VERSION "29102026"

NS_ :

BS_:

BU_: AMK_INV_RL AMK_INV_RR AMK_INV_FR AMK_INV_FL PC

VAL_TABLE_ VT_AMK_DiagnosticNumber 0 "0 No diagnostic" 257 "257 System diagnostics: SBM withdrawal" 258 "258 Leave RF active" 259 "259 System diagnostics: SBM withdrawal" 514 "514 System diagnostics: Check parallel EEPROM on the control board" 515 "515 System diagnostics: Check parallel EEPROM on the control board" 516 "516 System diagnostics: Check AZ(X27)-AW(X57)-BUS" 517 "517 System diagnostics: Check AZ(X27)-AW(X57)-BUS" 518 "518 System diagnostics" 519 "519 System diagnostics: SEEP in the inverter cannot be addressed" 520 "520 System diagnostics: SEEP in the inverter cannot be addressed" 521 "521 System diagnostics" 770 "770 System diagnostics" 771 "771 System diagnostics: Check parallel EEPROM on the control board" 772 "772 System diagnostics: Check parallel EEPROM on the control board" 773 "773 System diagnostics: Inadmissible database order" 774 "774 System diagnostics" 775 "775 System diagnostics: ID not supported" 776 "776 System diagnostics: It was attempted to use a parameter set which was not reserved for..." 777 "777 System diagnostics: Check parallel EEPROM on the control board" 778 "778 System diagnostics: The attribute of the selected data block is wrong" 779 "779 System diagnostics: The maximum value of the last changed parameter was exceeded" 780 "780 System diagnostics: The minimum value of the last changed parameter was not reached" 781 "781 System diagnostics: It was attempted to write a list which can only be read" 783 "783 System diagnostics: Error at distributing parameters during internal system update" 1024 "1024 System diagnostics: System fault in the control board area" 1025 "1025 System diagnostics" 1026 "1026 System diagnostics: Error on writing the serial EEPROM" 1027 "1027 System diagnostics: Data error in the EPROM" 1028 "1028 System diagnostics: RAM memory error, is checked during system initialization" 1029 "1029 System diagnostics: Data error in the parallel EEPROM" 1030 "1030 System diagnostics: Error on writing the parallel EEPROM" 1031 "1031 System diagnostics: Control panel does not report on initialization" 1032 "1032 System diagnostics: Reception error from the serial interface 1" 1033 "1033 System diagnostics: Reception error from the serial interface 2" 1034 "1034 System diagnostics: Time level overflow" 1035 "1035 System diagnostics: Faulty system initialization, possible external fault" 1036 "1036 System diagnostics: Fault" 1037 "1037 System diagnostics: Fault" 1038 "1038 System diagnostics: Fault" 1039 "1039 System diagnostics: Faulty memory access of the processor. Software reset is triggered...." 1040 "1040 Tripzone" 1041 "1041 Overtemperature external component mains" 1042 "1042 Mains phase fault" 1043 "1043 Line Voltage Error" 1044 "1044 No SBM" 1045 "1045 Mains overvoltage" 1046 "1046 Mains undervoltage" 1047 "1047 Inhibit time for UE" 1048 "1048 UE switching frequency too high" 1049 "1049 DC bus" 1050 "1050 Phase error L1" 1051 "1051 Phase error L2" 1052 "1052 Phase error L3" 1053 "1053 Phase sequence L1/L2" 1054 "1054 Phase sequence L1/L3" 1055 "1055 Phase sequence L2/L3" 1056 "1056 Mains phase sequence L1, L2 , L3" 1057 "1057 Fault +12 V" 1058 "1058 Fault -12 V" 1059 "1059 DC bus overvoltage" 1060 "1060 Regeneration fault" 1061 "1061 Braking transistor fault" 1062 "1062 System diagnostics" 1063 "1063 System diagnostics" 1064 "1064 System diagnostics" 1065 "1065 System diagnostics: QUE missing on RF activation" 1066 "1066 System diagnostics" 1067 "1067 System diagnostics: Fault DC bus" 1068 "1068 System diagnostics" 1069 "1069 System diagnostics" 1070 "1070 System diagnostics: FL not possible (timeout 20 s)" 1071 "1071 System diagnostics: Brake acknowledgment does not correspond to the expected value" 1072 "1072 System diagnostics" 1073 "1073 Cooling Air Temperature Warning" 1074 "1074 External line component temperature warning" 1075 "1075 Power supply unit temperature warning" 1076 "1076 Feed / Regeneration temperature warning" 1077 "1077 Line Voltage warning" 1078 "1078 Line undervoltage warning" 1079 "1079 System diagnostics: All square wave encoder breakage messages are displayed only with a..." 1080 "1080 Encoder line break analysis on option card, input 1 slot 1" 1081 "1081 Encoder line break analysis on option card, input 2 slot 1" 1082 "1082 Encoder line break analysis on option card, input 3 slot 1" 1083 "1083 Encoder line break analysis on option card, input 4 slot 1" 1084 "1084 Encoder line break analysis on option card, input 1 slot 2" 1085 "1085 Encoder line break analysis on option card, input 2 slot 2" 1086 "1086 Encoder line break analysis on option card, input 3 slot 2" 1087 "1087 Encoder line break analysis on option card, input 4 slot 2" 1088 "1088 Encoder line break analysis on option card, input 1 slot 3" 1089 "1089 Encoder line break analysis on option card, input 2 slot 3" 1090 "1090 Encoder line break analysis on option card, input 3 slot 3" 1091 "1091 Encoder line break analysis on option card, input 4 slot 3" 1092 "1092 Encoder line break analysis on option card, input 1 slot 4" 1093 "1093 Encoder line break analysis on option card, input 2 slot 4" 1094 "1094 Encoder line break analysis on option card, input 3 slot 4" 1095 "1095 Encoder line break analysis on option card, input 4 slot 4" 1096 "1096 Short-circuit/overload of the outputs option card, slot 1 (e.g. AZ-EA8 or AZ-EA24)" 1097 "1097 Short-circuit / overload of the outputs option card, slot 2 (e.g. AZ-EA8 or AZ-EA24)" 1098 "1098 Short-circuit/overload of the outputs option card, slot 3 (e.g. AZ-EA8 or AZ-EA24)" 1099 "1099 Short-circuit/overload of the outputs option card, slot 4 (e.g. AZ-EA8 or AZ-EA24)" 1100 "1100 System diagnostics: Short-circuit / overload digital outputs" 1101 "1101 Logic voltage error" 1102 "1102 Line voltage limit" 1103 "1103 Field bus warning" 1104 "1104 No FL with RF active" 1105 "1105 Reserved" 1106 "1106 System diagnostic" 1107 "1107 System diagnostics: Short circuit DC bus voltage" 1108 "1108 System diagnostics: Main contactor" 1109 "1109 System diagnostics: Shifting of Y-point" 1110 "1110 Warning brake transistor" 1111 "1111 Warning external component" 1112 "1112 Overload error external component" 1115 "1115 Communication monitoring" 1281 "1281 System diagnostics" 1282 "1282 ID32777, ID111, ID32769" 1283 "1283 ID111, ID32769" 1284 "1284 ID111, ID32769" 1285 "1285 ID32772 wrong" 1286 "1286 ID82 or ID83 too large" 1287 "1287 ID32890: 1, 2, 5, 10" 1288 "1288 ID110, ID111, ID32769" 1289 "1289 ID83 too small" 1290 "1290 ID82 too large" 1291 "1291 ID32774 faulty" 1292 "1292 SEEP checksum" 1293 "1293 Boot strap EEPROM" 1294 "1294 EEPROM defective" 1295 "1295 ID100 / ID101" 1296 "1296 ID211 / ID209 / ID210" 1297 "1297 ID212 / ID209 / ID210" 1298 "1298 ID100 faulty" 1299 "1299 ID32775: even" 1300 "1300 Error in Temporary Parameters" 1301 "1301 ID32778 faulty" 1302 "1302 System diagnostics: Operating mode incomplete, see 'ID32800 AMK main operating mode' et..." 1303 "1303 System diagnostics: Operating mode incomplete, see 'ID32800 AMK main operating mode' et..." 1304 "1304 System diagnostics: Operating mode incomplete, see 'ID32800 AMK main operating mode' et..." 1305 "1305 System diagnostics: Operating mode incomplete, see 'ID32800 AMK main operating mode' et..." 1306 "1306 System diagnostics: Operating mode incomplete, see 'ID32800 AMK main operating mode' et..." 1307 "1307 System diagnostics: Position resolution not realizable" 1308 "1308 System diagnostics: Resolution of the “Speed source pulses” source not realizable" 1309 "1309 System diagnostics: Speed window larger than 107372.5 rpm" 1310 "1310 System diagnostics: “Pole factor POLF” calculation out of tolerance" 1311 "1311 System diagnostics: 4 GPZ calculation inconclusive" 1312 "1312 System diagnostics: Negated direction of rotation permissible only for A and I encoders" 1313 "1313 ID82 less then ID83" 1314 "1314 System diagnostics" 1315 "1315 System diagnostics: Resolver 0 point shift inadmissible" 1316 "1316 ID32769/ID100 too large" 1317 "1317 ID32770/ID110 too large" 1318 "1318 ID32774 faulty" 1319 "1319 System diagnostics: Configuration of “Strobe” binary input wrong" 1320 "1320 System diagnostics" 1321 "1321 System diagnostics" 1322 "1322 System diagnostics" 1323 "1323 ID32769 IM < ID111 IN" 1324 "1324 ID32772 nN too large" 1325 "1325 ID32772 P1 reference" 1326 "1326 System diagnostics: Source converter/on (UE) incorrect" 1327 "1327 ID104 kv factor" 1328 "1328 System diagnostics" 1329 "1329 ID111/ID110 > 80%" 1330 "1330 ID32772 > ID113" 1331 "1331 ID209 > ID113" 1332 "1332 ID210 > ID113" 1333 "1333 System diagnostics: 'ID32780 Acceleration ramp' resp. 'ID32781 Deceleration ramp' are t..." 1334 "1334 ID38 > ID113" 1335 "1335 |ID39| > ID113" 1336 "1336 ID32778 > ID113" 1337 "1337 ID32783 > ID113" 1338 "1338 ID157 > ID113" 1339 "1339 ID125 > ID113" 1340 "1340 ID124 > ID113" 1341 "1341 AW-Imax wrong (SEEP)" 1342 "1342 System diagnostics: External error" 1343 "1343 System diagnostics: Internal fault or component failure" 1344 "1344 System diagnostics: Internal fault or component failure (AWMON)" 1345 "1345 System diagnostics: Internal fault or component failure (wrong BAV order)" 1346 "1346 System diagnostics: Internal fault or component failure (Handshake BAV/DTH)" 1347 "1347 System diagnostics: Internal fault or component failure (Handshake BAV/PEEP)" 1348 "1348 System diagnostics: Internal fault or component failure (Handshake BAV/AWMON)" 1349 "1349 System diagnostics: Internal fault or component failure" 1350 "1350 AW not present" 1351 "1351 AW not active" 1352 "1352 Can be changed only offline" 1353 "1353 Parameter Set change wrong" 1354 "1354 Im < Im1" 1355 "1355 Date ID32785" 1356 "1356 Date ID32785, ID32786" 1357 "1357 AWNR ID32787, ID32789, ID32791, ID32793" 1358 "1358 Source ID32787, ID32789, ID32791, ID32793" 1359 "1359 ID32873, ID32968, ID32977" 1360 "1360 Opt.1 ID32846, ID32855, ID32864" 1361 "1361 Opt.2 ID32846, ID32855, ID32864" 1362 "1362 Opt.3 ID32846, ID32855, ID32864" 1363 "1363 Opt.4 ID32846, ID32855, ID32864" 1364 "1364 Definition of output bits" 1365 "1365 AWNR output bit" 1366 "1366 Definition of input bits" 1367 "1367 ID32883 Option place 1" 1368 "1368 ID32884 Option place 2" 1369 "1369 ID32885 Option place 3" 1370 "1370 ID32886 Option place 4" 1371 "1371 ID32799 Standard Periphery" 1372 "1372 Option place 1 card defect" 1373 "1373 Option place 2 card defect" 1374 "1374 Option place 3 card defect" 1375 "1375 Option place 4 card defect" 1376 "1376 ID32882 Option place 1" 1377 "1377 ID32882 Option place 2" 1378 "1378 ID32882 Option place 3" 1379 "1379 ID32882 Option place 4" 1380 "1380 ID110, ID111, ID32769" 1381 "1381 LIW source calculation" 1382 "1382 System diagnostics" 1383 "1383 2PI value wrong" 1384 "1384 2PI value calculation" 1385 "1385 ID116, ID32776 ratio" 1386 "1386 Output DA1 … DA4" 1387 "1387 ID32846 wrong" 1388 "1388 ID32855 wrong" 1389 "1389 ID32864 wrong" 1390 "1390 System diagnostics: NC/LR time not integral." 1391 "1391 ID32772 wrong" 1392 "1392 ID158, ID32771, ID32772" 1393 "1393 AW not AZ-compatible" 1394 "1394 ID32892: x times 2 to the power 16" 1395 "1395 No Main Operation Mode" 1396 "1396 Operation mode not defined" 1397 "1397 Operation mode not impl." 1398 "1398 Setpoint source undefined" 1399 "1399 Setpoint Source (SQ) is Not Admissible in this Operation Mode (BA)" 1400 "1400 Option Card for Setpoint Source (SQ)" 1401 "1401 MGQ not selected" 1402 "1402 Source of Torque Limit (MGQ) inadmissible for this Operation Mode (BA)" 1403 "1403 Source of Torque Limit (MGQ) not implemented" 1404 "1404 Source of Torque Limit (MGQ) AW-analog assigned" 1405 "1405 Speed Ramp (DZLRMP) function missing" 1406 "1406 Speed Filter (DZLFLT) function missing" 1407 "1407 Selected Operation Mode (BA) not configured" 1408 "1408 Change of Operation Mode (BA) not executable" 1409 "1409 Selected AW No. not active" 1410 "1410 Selected Parameter Set" 1411 "1411 Type of Position Controller is Inadmissible" 1412 "1412 Type of External Encoder inadmissible" 1413 "1413 Missing option card" 1414 "1414 Unknown AW type" 1415 "1415 Wrong AW type" 1416 "1416 Change of Operation Mode inadmissible" 1417 "1417 System diagnostics: The chosen operation mode cannot be mapped" 1418 "1418 System diagnostics: The chosen operation mode cannot be mapped" 1419 "1419 System diagnostics: Speed filter activated but parameterised wrongly" 1420 "1420 System diagnostics: Speed ramp is activated but the ramp parameters are asymmetric or f..." 1421 "1421 System diagnostics: 'ID82 Positive torque limit' faulty" 1422 "1422 System diagnostics: Internal lists of controller configuration do not fit the operation..." 1423 "1423 Inadmissible Setpoint Source" 1424 "1424 Inadmissible Setpoint Source" 1425 "1425 Polarity" 1426 "1426 ID121/122 wrong" 1427 "1427 ID44 inadmissible" 1428 "1428 ID86 inadmissible" 1429 "1429 ID160 inadmissible" 1430 "1430 Position scaling" 1431 "1431 Velocity scaling" 1432 "1432 Velocity scaling IPO" 1433 "1433 Torque scaling" 1434 "1434 Acceleration scaling" 1435 "1435 ID76 inadmissible" 1436 "1436 Decade switch" 1438 "1438 Band width barrier" 1440 "1440 Data record changed" 1441 "1441 Clock synchronization" 1442 "1442 SEEP configuration" 1443 "1443 Test generator" 1444 "1444 PWM frequency" 1445 "1445 Current controller" 1446 "1446 EF can not be activated" 1447 "1447 Motor encoder gear" 1448 "1448 ID113 > ID34153" 1451 "1451 Configuration temperature sensor" 1453 "1453 Feed forward control" 1454 "1454 Error initialisation angle observer" 1455 "1455 Plausibility I/O" 1456 "1456 Ratio ID33194 to ID33195 incorrect" 1457 "1457 ID38 less then ID39" 1537 "1537 System diagnostics: SEEP error in the inverter" 1538 "1538 System diagnostics: Taskmaster- / taskslave combination is inadmissible" 1539 "1539 SEEP 1st checksum" 1540 "1540 SEEP 2nd checksum" 1541 "1541 Commanded AW missing" 1542 "1542 System diagnostics" 1543 "1543 System diagnostics: The manufacturer information was not written correctly in the SEEP" 1544 "1544 ID32953 no adjustment permissible" 1545 "1545 System diagnostics: Errors occurred when writing the current encoder values in the SEEP..." 1546 "1546 System diagnostics: Fault counter is missing" 1547 "1547 System diagnostics" 1548 "1548 System diagnostics" 1549 "1549 System diagnostics: Clock master / clock slave combination not permissible" 1550 "1550 System diagnostics: Clock master / clock slave combination not permissible" 1551 "1551 Encoder track failed" 1552 "1552 Encoder adjustment abort" 1553 "1553 Encoder adjustment timeout" 1554 "1554 ID32776 Sinus Encoder Period is faulty" 1555 "1555 Reference pulse" 1556 "1556 Reference Pulse - Encoder Input" 1557 "1557 Turn axis" 1558 "1558 System diagnostics: Inverter transfers faulty encoder feedback values" 1794 "1794 System diagnostics: Interpolator" 1795 "1795 System diagnostics: Interpolator" 1796 "1796 System diagnostics: Interpolator" 1797 "1797 System diagnostics: Interpolator" 1798 "1798 System diagnostics: Interpolator" 1799 "1799 System diagnostics: Interpolator" 1800 "1800 System diagnostics: Interpolator" 1801 "1801 System diagnostics: Interpolator" 1802 "1802 System diagnostics: Interpolator" 1803 "1803 System diagnostics: Interpolator" 1804 "1804 System diagnostics: Check final value (target value)" 1805 "1805 System diagnostics: Interpolator standardisation: dxifaktor with remainder ID136, ID137..." 1806 "1806 System diagnostics: Interpolator standardisation: dxifaktor = 0: increase ID136, ID137,..." 1807 "1807 System diagnostics: Permissible time between KMD commanding and BAV operation mode mana..." 1808 "1808 System diagnostics: Operation mode management acknowledges error after commanding" 1809 "1809 System diagnostics: Inadmissible commanding code in KMD-SS, check interface" 1810 "1810 System diagnostics: Inadmissible commanding function in KMD-SS, check interface" 1811 "1811 System diagnostics: Inverter can no longer be addressed" 1812 "1812 System diagnostics: Inverter can no longer be addressed" 1813 "1813 KMD user error" 1814 "1814 System diagnostics: Inadmissible commanding operation mode selected, BA may be assigned..." 1815 "1815 Controller enable missing" 1816 "1816 Not homed" 1817 "1817 System diagnostics: Synchronous running source in synchronous running inadmissible" 1818 "1818 System diagnostics" 1819 "1819 System diagnostics: Inverter address calculation impossible, operation mode incomplete" 1820 "1820 System diagnostics: Ramp down error e.g. in lifting axis function, time according to ID..." 1821 "1821 System diagnostics: IPO cannot perform direction change" 1822 "1822 System diagnostics: IPO cannot be activated" 1823 "1823 System diagnostics: IPO cannot be activated" 1824 "1824 System diagnostics: Inadmissible KMD code in KMD-SS, inadmissible timing check interface" 1825 "1825 System diagnostics: SINCOS encoder, encoder does not report within 2 sec. through RS485-SS" 1826 "1826 System diagnostics: SINCOS encoder, checksum of the encoder acknowledgement does not ag..." 1827 "1827 System diagnostics: Invalid encoder type, the SINCOS encoder type is not permitted in t..." 1828 "1828 System diagnostics: This message can occur only in connection with an abort of drive fu..." 1829 "1829 System diagnostics: 'ID55 Closed loop polarity' and 'ID43 Velocity polarity' may be onl..." 1830 "1830 System diagnostics: “Flying saw” drive function, waiting distance (ID278) is greater th..." 1831 "1831 System diagnostics: SINCOS encoder, encoder reports error (error bit set)" 1832 "1832 System diagnostics: “Absolute positioning” drive function" 1833 "1833 System diagnostics: “Lifting axis” drive function, |nactual| ≥ |1.2 x nlimit|" 1834 "1834 System diagnostics: SINCOS encoders: The difference of the double sampling of the absol..." 1835 "1835 System diagnostics: Special lift function" 1836 "1836 System diagnostics: Special Lift function" 1837 "1837 System diagnostics: Special Lift function" 1838 "1838 System diagnostics: Special Lift function" 1839 "1839 System diagnostics: Special Lift function" 1840 "1840 System diagnostics: Special Lift function" 1841 "1841 System diagnostics" 1842 "1842 System diagnostics: Special lift function" 1843 "1843 System diagnostics" 2049 "2049 System diagnostics" 2050 "2050 System diagnostics: ID address or ID property is not known" 2051 "2051 System diagnostics: Waiting time after order to logical subscriber is exceeded" 2052 "2052 System diagnostics: The ID to be edited is not contained in the database of the system" 2053 "2053 System diagnostics: Error acknowledgement in commanding the database" 2054 "2054 System diagnostics: Error acknowledgement in commanding the monitor" 2055 "2055 System diagnostics: Error acknowledgement in commanding the serial EEPROM" 2056 "2056 System diagnostics: Error acknowledgement in commanding the operation mode management" 2057 "2057 System diagnostics: Error acknowledgement in commanding the drive commanding KMD" 2058 "2058 System diagnostics: Error in LT → KMD commanding inverter, LT → KMD - logical subscribe..." 2059 "2059 System diagnostics: Error in LT→ KMD commanding AW2" 2060 "2060 System diagnostics: Error in LT → KMD commanding AW3" 2061 "2061 System diagnostics: Error in LT → KMD commanding AW4" 2062 "2062 System diagnostics: Error in LT → KMD commanding AW5" 2063 "2063 System diagnostics: Error in LT → KMD commanding AW6" 2064 "2064 System diagnostics: Error in LT → MD commanding AW7" 2065 "2065 System diagnostics: Error in LT → KMD commanding AW8" 2066 "2066 System diagnostics: Error acknowledgement in commanding a drive control" 2067 "2067 System diagnostics: Error acknowledgement in commanding the diagnostics" 2068 "2068 System diagnostics: Error acknowledgement in commanding the display function" 2069 "2069 System diagnostics: Error acknowledgement in commanding the lift function" 2070 "2070 System diagnostics: LT-SBUS, inverter not present" 2071 "2071 System diagnostics: Failure in the s-bus hardware; re-boot system or check hardware" 2072 "2072 System diagnostics: S-bus software received faulty information from connected device, c..." 2073 "2073 System diagnostics" 2074 "2074 System diagnostics: Disturbance of scope function" 2305 "2305 Phase U Short Circuit" 2306 "2306 Phase V Short Circuit" 2307 "2307 Phase W Short Circuit" 2308 "2308 Supply +12 V" 2309 "2309 Supply" 2310 "2310 Encoder communication" 2311 "2311 Encoder signal" 2312 "2312 Output Terminal Ground Fault" 2313 "2313 Synchronous running error" 2314 "2314 Master Synchronous Telegram AW" 2315 "2315 AW controller clock error" 2316 "2316 Motor direction of rotation" 2317 "2317 External encoder direction of rotation" 2318 "2318 Control deviation" 2319 "2319 n > nmax" 2320 "2320 EF inactive" 2321 "2321 System diagnostics: IGBT monitoring in PWM device detects overcurrent" 2322 "2322 System diagnostics: Inverter RAM memory error" 2323 "2323 System diagnostics: VECON watchdog" 2324 "2324 System diagnostics: Hardware significance in the AW SEEP invalid (M8030, 2 or 3 current..." 2325 "2325 System diagnostics: Error (timeout 5s) current controller adjustment" 2326 "2326 System diagnostics" 2327 "2327 Plausibility of the External Encoder" 2328 "2328 System diagnostics: Missing option card e.g. in the KU. For instance, if an AMK-A encod..." 2329 "2329 System diagnostics: Commutation error in synchronous machine with AMK-T encoder (SINCOS..." 2330 "2330 System diagnostics" 2331 "2331 System diagnostics: Ramp down error" 2332 "2332 System diagnostics" 2333 "2333 Position growth too large" 2334 "2334 System diagnostics: Output terminal overcurrent" 2335 "2335 Error reference pulse" 2336 "2336 System diagnostics: Current setpoint at the analog input of the slave AW was too large...." 2337 "2337 No clock enable acknowledgement" 2338 "2338 Magnetizing timeout" 2339 "2339 Ramp down error" 2340 "2340 Communication on AW" 2342 "2342 System diagnostics" 2343 "2343 System diagnostics" 2344 "2344 Monitoring actual position" 2345 "2345 Inverter overload error" 2346 "2346 Converter temperature error" 2347 "2347 Motor temperature error" 2348 "2348 System diagnostics" 2349 "2349 Inverter overload warning" 2350 "2350 Device temperature warning" 2351 "2351 Motor temperature warning" 2352 "2352 Motor overload warning" 2353 "2353 Motor overload error" 2354 "2354 Handshake brake" 2356 "2356 Setpoint stop active" 2357 "2357 Device overload warning" 2358 "2358 Device overload error" 2359 "2359 Motor overload warning" 2360 "2360 Motor overload error" 2361 "2361 EF Logic" 2362 "2362 Error Commutation Motor" 2365 "2365 Error angle observer" 2366 "2366 Limit switch" 2367 "2367 Error Non Dual Use" 2560 "2560 System diagnostics: EtherCAT" 2561 "2561 System diagnostics: SERCOS" 2562 "2562 System diagnostics: MDT reception error in the Comm.phase 3 or 4 Device Description Cla..." 2563 "2563 System diagnostics: SERCOS Device Description Invalid communication phase Class Error D..." 2564 "2564 System diagnostics: SERCOS" 2565 "2565 System diagnostics: Phase switchback (not on phase 0)" 2566 "2566 System diagnostics: Phase switchover without ready message" 2569 "2569 System diagnostics: Memory error (allocating)" 2570 "2570 System diagnostics: Memory error (deallocating)" 2571 "2571 System diagnostics: Timeout during communication phases switch-over (AS-PL)" 2572 "2572 System diagnostics: SERCOS" 2573 "2573 System diagnostics: SERCOS" 2574 "2574 System diagnostics: SERCOS" 2575 "2575 System diagnostics: In Kx-SC2 modules: ext. 48 V power supply is not available or has b..." 2576 "2576 System diagnostics" 2577 "2577 System diagnostics: Allocation of the real time control or real time status bit" 2578 "2578 System diagnostics: Test function active message (continuous light, zero bit stream)" 2579 "2579 System diagnostics: Error on initialization of the SERCOS option card" 2581 "2581 System diagnostics: SERCOS master driver initialization" 2582 "2582 System diagnostics: SERCOS master driver initialization" 2583 "2583 System diagnostics: SERCOS master configuration 'ID34036 CCB File'" 2584 "2584 System diagnostics: SERCOS master phase switchover" 2585 "2585 System diagnostics: SERCOS master time slot calculation" 2586 "2586 System diagnostics: SERCOS master service channel" 2587 "2587 System diagnostics: SERCOS master incorrect data in the service channel" 2588 "2588 System diagnostics: SERCOS master error in command execution" 2589 "2589 System diagnostics: SERCOS master has detected ring interruption" 2590 "2590 System diagnostics: SERCOS master has detected AT failure" 2591 "2591 System diagnostics: SERCOS master software error" 2592 "2592 System diagnostics: SERCOS master has detected MST failure" 2593 "2593 System diagnostics: SERCOS master real time error" 2594 "2594 System diagnostics: SERCOS master software error" 2595 "2595 System diagnostics: SERCOS" 2596 "2596 System diagnostics: SERCOS master has received the “error” acknowledgment to a command" 2597 "2597 System diagnostics: SERCOS master has received an error message from a remote node" 2598 "2598 System diagnostics: SERCOS has indicated a bad signal quality on the OWG receiver (exce..." 2599 "2599 System diagnostics: Error while activating the advanced operating mode" 2600 "2600 System diagnostics: Error memory space" 2601 "2601 System diagnostics: Adapter cannot be initialized" 2602 "2602 System diagnostics: Cable is interrupted (reaction according to 'ID 34027 BUS failure c..." 2603 "2603 System diagnostics: Data exchange mode is exited (e.g. after watchdog error; reaction a..." 2604 "2604 System diagnostics: Inadmissible field bus handshake code (e.g. SERVERERROR, SERVERWARN..." 2605 "2605 System diagnostics: PROFIBUS Initialization/ Error state" 2606 "2606 System diagnostics: PROFIBUS MSAC-C1 error (Master-Slave Acyclic Communication-Class1)" 2607 "2607 System diagnostics: PROFIBUS MSAC-C2 error (Master-Slave Acyclic Communication-Class2)" 2608 "2608 System diagnostics: PROFIBUS initialisation error" 2609 "2609 System diagnostics: PROFIBUS Warning – wrong parameter initialization" 2610 "2610 System diagnostics: PROFIBUS error bus configuration" 2611 "2611 System diagnostics: PROFIBUS error bus configuration" 2612 "2612 System diagnostics: PROFIBUS error bus configuration" 2613 "2613 System diagnostics: PROFIBUS error bus configuration" 2614 "2614 System diagnostics: PROFIBUS error bus configuration" 2615 "2615 System diagnostics: PROFIBUS error bus configuration" 2620 "2620 System diagnostics: Subscriber not connected with network" 2621 "2621 System diagnostics: Network error" 2622 "2622 System diagnostics: Transfer error/transmission error" 2623 "2623 System diagnostics: Adapter is constantly reconfigured" 2624 "2624 System diagnostics: ID34023=0, BUS subscriber address must be unequal to 0" 2625 "2625 System diagnostics: ARCNET telegram too long" 2626 "2626 System diagnostics: Node ID is already present" 2628 "2628 System diagnostics: Init. state error" 2640 "2640 LON failure" 2641 "2641 LON timeout IN" 2642 "2642 LON timeout OUT" 2643 "2643 LON timeout application" 2644 "2644 System diagnostics: Device reports within 2 s in the ramp up" 2645 "2645 System diagnostics: DPRAM writing error" 2660 "2660 System diagnostics: The required RAM memory for the system data is not present" 2661 "2661 System diagnostics: Unknown bus mode entry in 'ID34025 BUS mode'" 2663 "2663 System diagnostics: Interbus is inactive" 2664 "2664 System diagnostics: Interbus reset" 2665 "2665 System diagnostics: At least 20 invalid data cycles detected" 2680 "2680 System diagnostics: CAN AFP error during initialization" 2681 "2681 System diagnostics: Object Dictionary error" 2682 "2682 System diagnostics: Too much Receive PDOs and SDOs configured" 2683 "2683 System diagnostics: Software error (Reason could be false configuration data)" 2684 "2684 System diagnostics: Communication error" 2685 "2685 System diagnostics: Communication error" 2686 "2686 System diagnostics: AFP error" 2687 "2687 System diagnostics: Invalid Node address" 2688 "2688 System diagnostics: 'ID34025 Bus mode':AFP bit not valid" 2689 "2689 System diagnostics: Errors on configuring" 2690 "2690 System diagnostics: Error in Slave configuration (Data size in CCF element too big)" 2691 "2691 System diagnostics" 2692 "2692 System diagnostics: Software warning" 2693 "2693 System diagnostics: Slave Node State error" 2694 "2694 System diagnostics: Slave Node Guarding error" 2695 "2695 System diagnostics: Emergency received" 2696 "2696 System diagnostics: DSDO Router error" 2697 "2697 System diagnostics: Mandatory slave node missing" 2698 "2698 System diagnostics: SDO error during network configuration" 2699 "2699 System diagnostics: System error" 2721 "2721 System diagnostics: Slave defective or no longer on the bus" 2722 "2722 System diagnostics: Cable breakage" 2723 "2723 System Diagnostics" 2724 "2724 System diagnostics: Error during the initialisation for the EtherCAT option" 2725 "2725 System diagnostics" 2726 "2726 System diagnostics: Error in the EtherCAT master booting process" 2727 "2727 System diagnostics: Error EtherCAT configuration" 2728 "2728 System diagnostics: Error EtherCAT protocol during ID access" 2729 "2729 System diagnostics: Error EtherCAT service channel / mailbox" 2730 "2730 System diagnostics: Error EtherCAT datagram sending procedure, communication error" 2731 "2731 System diagnostics: Error EtherCAT sequence slave configuration" 2732 "2732 System diagnostics" 2741 "2741 Modbus configuration" 2742 "2742 MODBUS communication" 2743 "2743 MODBUS protocol" 2744 "2744 MODBUS command" 2760 "2760 System diagnostics: Missing DC bus voltage at state 'SWITCHED ON' or when switching to..." 2761 "2761 System diagnostics: Error when changing the operating mode" 2762 "2762 System diagnostics: Error in function 'Touch Probe'" 2763 "2763 System diagnostics: Error in scaling configuration" 2764 "2764 System diagnostics: Error in Brake function" 2816 "2816 PS option" 3072 "3072 Error option SERCOS" 3328 "3328 NC option error" 3584 "3584 Special SW msg: Fault overload protection connectbox (n)" 3585 "3585 FSE: CAN/config error during init (voltage limit / torque reduction limits)" 3586 "3586 FSE CAN: Error during initialization (config mode, index, signal, length, baud)" 3587 "3587 FSE CAN: Error during operation (setpoint telegram failure, checksum, counter)" 3588 "3588 Special SW msg: Frequency too low" 3589 "3589 Special SW msg: Frequency too high" 3590 "3590 Special SW msg: Voltage too low" 3591 "3591 Special SW msg: Voltage too high" 3592 "3592 Special SW msg: Fault voltage (switch on)" 3593 "3593 Special SW msg: Fault frequency (switch on)" 3594 "3594 Special SW msg: Warning string monitoring connectbox (n)..." 3595 "3595 Special SW msg: Fault init bus" 3596 "3596 Special SW msg: Fault check DC" 3597 "3597 Special SW msg: Fault check AC / DC" 3598 "3598 Special SW msg: See special descriptions corresponding to..." 3599 "3599 Special SW msg: See special descriptions corresponding to..." 3600 "3600 Special SW msg: See special descriptions corresponding to..." 3601 "3601 Special SW msg: See special descriptions corresponding to..." 3602 "3602 Special SW msg: See special descriptions corresponding to..." 3603 "3603 System diagnostics: AFP-PLC error" 3605 "3605 Safety - Invalid parameterisation" 3606 "3606 Safety - Error during operation" 3607 "3607 Safety - Internal system error" 3609 "3609 Safety - Faulty parameter transfer" 3610 "3610 Safety - Warning during operation" 3840 "3840 File access" 3841 "3841 System diagnostics: Internal communication: Error message returned from end device" 3842 "3842 System diagnostics: Internal communication: No heap memory could be addressed." 3843 "3843 System diagnostics: Internal communication: Source module does not exist (not logged in?)" 3844 "3844 System diagnostics: Internal communication: The addressed target does not exist" 3845 "3845 System diagnostics" 3846 "3846 System diagnostics: Internal communication: A module has logged on that already exists..." 3847 "3847 System diagnostics: Internal communication: The element code is unknown" 3848 "3848 System diagnostics: Internal communication: Too many modules have logged in or" 3849 "3849 System diagnostics: Internal communication: Protocol or command order is incorrect" 3850 "3850 System diagnostics: A bus connected to the internal communication is not in standby mod..." 3851 "3851 System diagnostics: An internal communication path has been occupied by a module by wri..." 3852 "3852 System diagnostics: An internal communication path specified by a module is not valid o..." 3853 "3853 System diagnostics: Router error in module setting" 3854 "3854 System diagnostics: Router memory overflow of the inernal buffer" 3855 "3855 System diagnostics: Router memory overflow at access to the internal database" 3860 "3860 ADB-File access" 3861 "3861 System start / update" 3862 "3862 System diagnostics: System exception, CPU error" 3863 "3863 System diagnostics: Router memory overflow internal buffer" 3864 "3864 Bus configuration" 3865 "3865 Software version option" 3867 "3867 System diagnostics: Error in updating device data record" 3868 "3868 System diagnostics: Error during initialisation of system" 3869 "3869 I/O Optional Card" 3871 "3871 System diagnostics: Communication" ;
VAL_TABLE_ VT_AMK_SystemReady 0 "Not_Ready" 1 "System_Ready" ;
VAL_TABLE_ VT_AMK_Error 0 "No_Error" 1 "Error_Active" ;
VAL_TABLE_ VT_AMK_Warning 0 "No_Warning" 1 "Warning_Active" ;
VAL_TABLE_ VT_AMK_Quit 0 "Not_Acknowledged" 1 "Acknowledged" ;
VAL_TABLE_ VT_AMK_DcOnStatus 0 "HV_Off" 1 "HV_On" ;
VAL_TABLE_ VT_AMK_InverterOnStatus 0 "Inverter_Off" 1 "Inverter_On" ;
VAL_TABLE_ VT_AMK_Derating 0 "No_Derating" 1 "Derating_Active" ;
VAL_TABLE_ VT_AMK_EnableCmd 0 "Disable" 1 "Enable" ;
VAL_TABLE_ VT_AMK_ErrorResetCmd 0 "No_Action" 1 "Reset_Error" ;

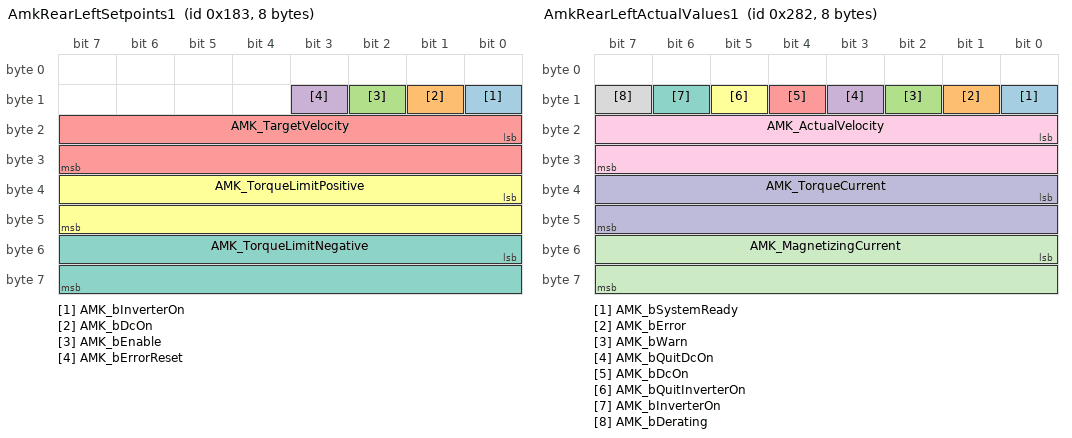
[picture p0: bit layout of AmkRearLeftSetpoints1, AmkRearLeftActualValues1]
BO_ 387 AmkRearLeftSetpoints1: 8 PC
 SG_ AMK_bInverterOn : 8|1@1+ (1,0) [0|1] ""  AMK_INV_RL
 SG_ AMK_bDcOn : 9|1@1+ (1,0) [0|1] ""  AMK_INV_RL
 SG_ AMK_bEnable : 10|1@1+ (1,0) [0|1] ""  AMK_INV_RL
 SG_ AMK_bErrorReset : 11|1@1+ (1,0) [0|1] ""  AMK_INV_RL
 SG_ AMK_TargetVelocity : 16|16@1- (1,0) [-30000|30000] "rpm"  AMK_INV_RL
 SG_ AMK_TorqueLimitPositive : 32|16@1- (0.1,0) [0|3276.7] "%Mn"  AMK_INV_RL
 SG_ AMK_TorqueLimitNegative : 48|16@1- (0.1,0) [-3276.8|0] "%Mn"  AMK_INV_RL

BO_ 642 AmkRearLeftActualValues1: 8 AMK_INV_RL
 SG_ AMK_bSystemReady : 8|1@1+ (1,0) [0|1] ""  PC
 SG_ AMK_bError : 9|1@1+ (1,0) [0|1] ""  PC
 SG_ AMK_bWarn : 10|1@1+ (1,0) [0|1] ""  PC
 SG_ AMK_bQuitDcOn : 11|1@1+ (1,0) [0|1] ""  PC
 SG_ AMK_bDcOn : 12|1@1+ (1,0) [0|1] ""  PC
 SG_ AMK_bQuitInverterOn : 13|1@1+ (1,0) [0|1] ""  PC
 SG_ AMK_bInverterOn : 14|1@1+ (1,0) [0|1] ""  PC
 SG_ AMK_bDerating : 15|1@1+ (1,0) [0|1] ""  PC
 SG_ AMK_ActualVelocity : 16|16@1- (1,0) [-32768|32767] "rpm"  PC
 SG_ AMK_TorqueCurrent : 32|16@1- (0.00653076171875,0) [-214.000|213.993] "A"  PC
 SG_ AMK_MagnetizingCurrent : 48|16@1- (0.00653076171875,0) [-214.000|213.993] "A"  PC

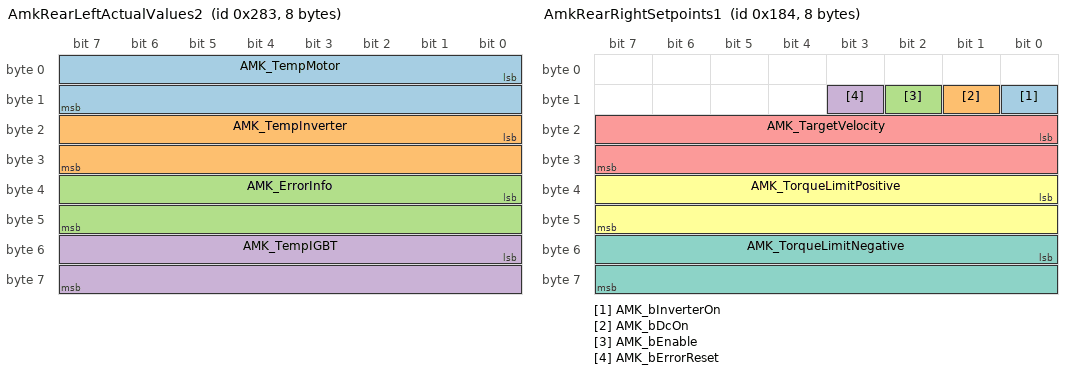
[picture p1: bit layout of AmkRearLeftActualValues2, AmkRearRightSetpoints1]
BO_ 643 AmkRearLeftActualValues2: 8 AMK_INV_RL
 SG_ AMK_TempMotor : 0|16@1- (0.1,0) [-3276.8|3276.7] "degC"  PC
 SG_ AMK_TempInverter : 16|16@1- (0.1,0) [-3276.8|3276.7] "degC"  PC
 SG_ AMK_ErrorInfo : 32|16@1+ (1,0) [0|65535] ""  PC
 SG_ AMK_TempIGBT : 48|16@1- (0.1,0) [-3276.8|3276.7] "degC"  PC

BO_ 388 AmkRearRightSetpoints1: 8 PC
 SG_ AMK_bInverterOn : 8|1@1+ (1,0) [0|1] ""  AMK_INV_RR
 SG_ AMK_bDcOn : 9|1@1+ (1,0) [0|1] ""  AMK_INV_RR
 SG_ AMK_bEnable : 10|1@1+ (1,0) [0|1] ""  AMK_INV_RR
 SG_ AMK_bErrorReset : 11|1@1+ (1,0) [0|1] ""  AMK_INV_RR
 SG_ AMK_TargetVelocity : 16|16@1- (1,0) [-30000|30000] "rpm"  AMK_INV_RR
 SG_ AMK_TorqueLimitPositive : 32|16@1- (0.1,0) [0|3276.7] "%Mn"  AMK_INV_RR
 SG_ AMK_TorqueLimitNegative : 48|16@1- (0.1,0) [-3276.8|0] "%Mn"  AMK_INV_RR

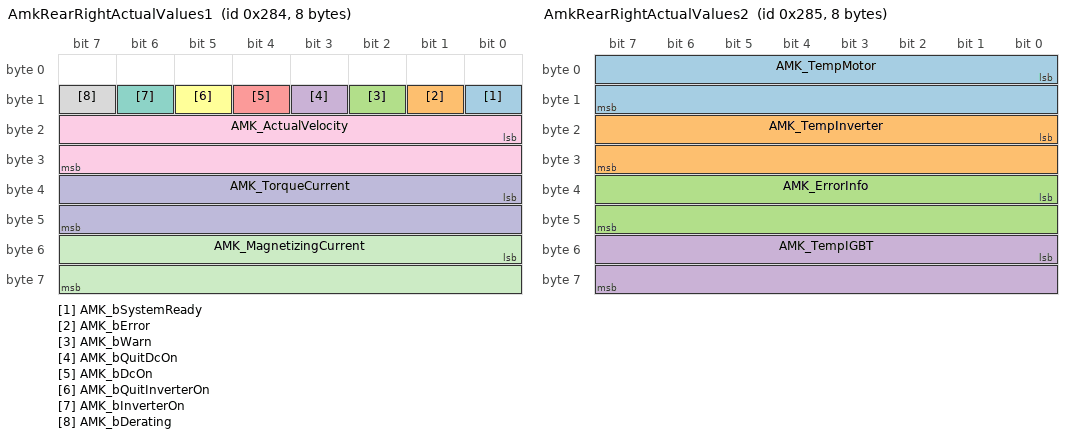
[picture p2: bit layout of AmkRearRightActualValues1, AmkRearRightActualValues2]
BO_ 644 AmkRearRightActualValues1: 8 AMK_INV_RR
 SG_ AMK_bSystemReady : 8|1@1+ (1,0) [0|1] ""  PC
 SG_ AMK_bError : 9|1@1+ (1,0) [0|1] ""  PC
 SG_ AMK_bWarn : 10|1@1+ (1,0) [0|1] ""  PC
 SG_ AMK_bQuitDcOn : 11|1@1+ (1,0) [0|1] ""  PC
 SG_ AMK_bDcOn : 12|1@1+ (1,0) [0|1] ""  PC
 SG_ AMK_bQuitInverterOn : 13|1@1+ (1,0) [0|1] ""  PC
 SG_ AMK_bInverterOn : 14|1@1+ (1,0) [0|1] ""  PC
 SG_ AMK_bDerating : 15|1@1+ (1,0) [0|1] ""  PC
 SG_ AMK_ActualVelocity : 16|16@1- (1,0) [-32768|32767] "rpm"  PC
 SG_ AMK_TorqueCurrent : 32|16@1- (0.00653076171875,0) [-214.000|213.993] "A"  PC
 SG_ AMK_MagnetizingCurrent : 48|16@1- (0.00653076171875,0) [-214.000|213.993] "A"  PC

BO_ 645 AmkRearRightActualValues2: 8 AMK_INV_RR
 SG_ AMK_TempMotor : 0|16@1- (0.1,0) [-3276.8|3276.7] "degC"  PC
 SG_ AMK_TempInverter : 16|16@1- (0.1,0) [-3276.8|3276.7] "degC"  PC
 SG_ AMK_ErrorInfo : 32|16@1+ (1,0) [0|65535] ""  PC
 SG_ AMK_TempIGBT : 48|16@1- (0.1,0) [-3276.8|3276.7] "degC"  PC

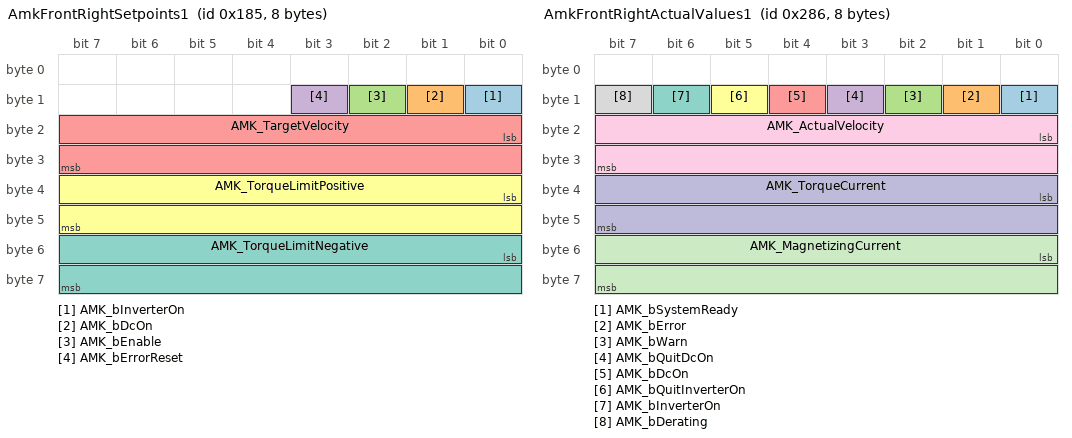
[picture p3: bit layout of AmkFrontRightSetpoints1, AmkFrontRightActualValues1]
BO_ 389 AmkFrontRightSetpoints1: 8 PC
 SG_ AMK_bInverterOn : 8|1@1+ (1,0) [0|1] ""  AMK_INV_FR
 SG_ AMK_bDcOn : 9|1@1+ (1,0) [0|1] ""  AMK_INV_FR
 SG_ AMK_bEnable : 10|1@1+ (1,0) [0|1] ""  AMK_INV_FR
 SG_ AMK_bErrorReset : 11|1@1+ (1,0) [0|1] ""  AMK_INV_FR
 SG_ AMK_TargetVelocity : 16|16@1- (1,0) [-30000|30000] "rpm"  AMK_INV_FR
 SG_ AMK_TorqueLimitPositive : 32|16@1- (0.1,0) [0|3276.7] "%Mn"  AMK_INV_FR
 SG_ AMK_TorqueLimitNegative : 48|16@1- (0.1,0) [-3276.8|0] "%Mn"  AMK_INV_FR

BO_ 646 AmkFrontRightActualValues1: 8 AMK_INV_FR
 SG_ AMK_bSystemReady : 8|1@1+ (1,0) [0|1] ""  PC
 SG_ AMK_bError : 9|1@1+ (1,0) [0|1] ""  PC
 SG_ AMK_bWarn : 10|1@1+ (1,0) [0|1] ""  PC
 SG_ AMK_bQuitDcOn : 11|1@1+ (1,0) [0|1] ""  PC
 SG_ AMK_bDcOn : 12|1@1+ (1,0) [0|1] ""  PC
 SG_ AMK_bQuitInverterOn : 13|1@1+ (1,0) [0|1] ""  PC
 SG_ AMK_bInverterOn : 14|1@1+ (1,0) [0|1] ""  PC
 SG_ AMK_bDerating : 15|1@1+ (1,0) [0|1] ""  PC
 SG_ AMK_ActualVelocity : 16|16@1- (1,0) [-32768|32767] "rpm"  PC
 SG_ AMK_TorqueCurrent : 32|16@1- (0.00653076171875,0) [-214.000|213.993] "A"  PC
 SG_ AMK_MagnetizingCurrent : 48|16@1- (0.00653076171875,0) [-214.000|213.993] "A"  PC

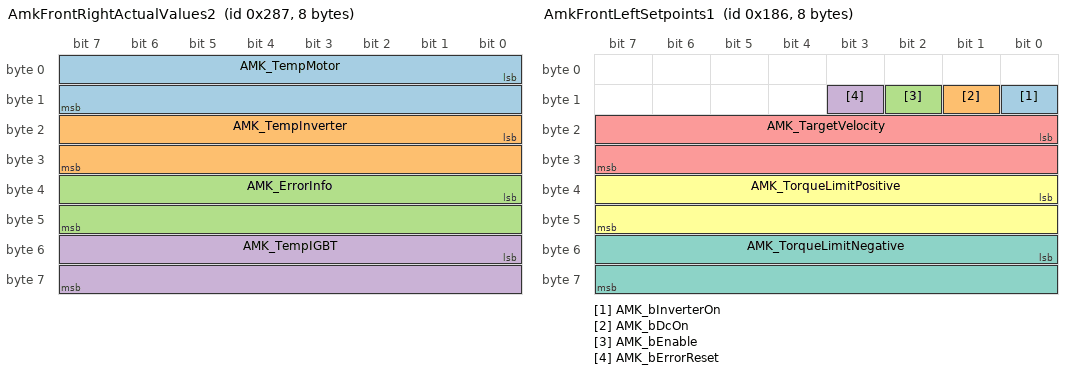
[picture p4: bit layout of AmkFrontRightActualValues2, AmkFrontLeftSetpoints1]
BO_ 647 AmkFrontRightActualValues2: 8 AMK_INV_FR
 SG_ AMK_TempMotor : 0|16@1- (0.1,0) [-3276.8|3276.7] "degC"  PC
 SG_ AMK_TempInverter : 16|16@1- (0.1,0) [-3276.8|3276.7] "degC"  PC
 SG_ AMK_ErrorInfo : 32|16@1+ (1,0) [0|65535] ""  PC
 SG_ AMK_TempIGBT : 48|16@1- (0.1,0) [-3276.8|3276.7] "degC"  PC

BO_ 390 AmkFrontLeftSetpoints1: 8 PC
 SG_ AMK_bInverterOn : 8|1@1+ (1,0) [0|1] ""  AMK_INV_FL
 SG_ AMK_bDcOn : 9|1@1+ (1,0) [0|1] ""  AMK_INV_FL
 SG_ AMK_bEnable : 10|1@1+ (1,0) [0|1] ""  AMK_INV_FL
 SG_ AMK_bErrorReset : 11|1@1+ (1,0) [0|1] ""  AMK_INV_FL
 SG_ AMK_TargetVelocity : 16|16@1- (1,0) [-30000|30000] "rpm"  AMK_INV_FL
 SG_ AMK_TorqueLimitPositive : 32|16@1- (0.1,0) [0|3276.7] "%Mn"  AMK_INV_FL
 SG_ AMK_TorqueLimitNegative : 48|16@1- (0.1,0) [-3276.8|0] "%Mn"  AMK_INV_FL

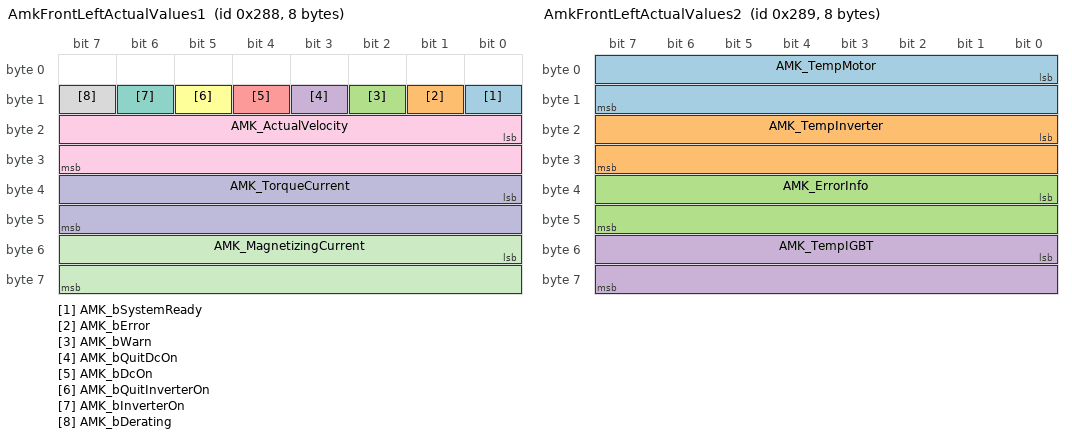
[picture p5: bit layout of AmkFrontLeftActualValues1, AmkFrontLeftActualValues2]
BO_ 648 AmkFrontLeftActualValues1: 8 AMK_INV_FL
 SG_ AMK_bSystemReady : 8|1@1+ (1,0) [0|1] ""  PC
 SG_ AMK_bError : 9|1@1+ (1,0) [0|1] ""  PC
 SG_ AMK_bWarn : 10|1@1+ (1,0) [0|1] ""  PC
 SG_ AMK_bQuitDcOn : 11|1@1+ (1,0) [0|1] ""  PC
 SG_ AMK_bDcOn : 12|1@1+ (1,0) [0|1] ""  PC
 SG_ AMK_bQuitInverterOn : 13|1@1+ (1,0) [0|1] ""  PC
 SG_ AMK_bInverterOn : 14|1@1+ (1,0) [0|1] ""  PC
 SG_ AMK_bDerating : 15|1@1+ (1,0) [0|1] ""  PC
 SG_ AMK_ActualVelocity : 16|16@1- (1,0) [-32768|32767] "rpm"  PC
 SG_ AMK_TorqueCurrent : 32|16@1- (0.00653076171875,0) [-214.000|213.993] "A"  PC
 SG_ AMK_MagnetizingCurrent : 48|16@1- (0.00653076171875,0) [-214.000|213.993] "A"  PC

BO_ 649 AmkFrontLeftActualValues2: 8 AMK_INV_FL
 SG_ AMK_TempMotor : 0|16@1- (0.1,0) [-3276.8|3276.7] "degC"  PC
 SG_ AMK_TempInverter : 16|16@1- (0.1,0) [-3276.8|3276.7] "degC"  PC
 SG_ AMK_ErrorInfo : 32|16@1+ (1,0) [0|65535] ""  PC
 SG_ AMK_TempIGBT : 48|16@1- (0.1,0) [-3276.8|3276.7] "degC"  PC

CM_ "AMK Racing Kit 4WD (KW26-S5-FSE-4Q) - Fixed CAN message configuration, CAN 2.0A, Intel byte order. Sources: PDK_205481_KW26-S5-FSE-4Q 2020/44, PDK_025786_Diagnose 2023/16, Motor_data_sheet_A2370DD_DD5.";
CM_ BO_ 387 "Rear Left AMK Setpoints 1: control word + setpoints (PC -> inverter). Telegram failure monitoring: error if no telegram > 50 ms.";
CM_ BO_ 642 "Rear Left AMK Actual Values 1: status word + actual values.";
CM_ BO_ 643 "Rear Left AMK Actual Values 2: temperatures + diagnostic number.";
CM_ SG_ 387 AMK_bInverterOn "Controller enable (AMK_Control bit 8). Motor control also needs HW RF signal X140 BE1 + AMK_bEnable.";
CM_ SG_ 387 AMK_bDcOn "HV activation (AMK_Control bit 9).";
CM_ SG_ 387 AMK_bEnable "Driver enable (AMK_Control bit 10).";
CM_ SG_ 387 AMK_bErrorReset "Remove error (AMK_Control bit 11). All setpoints must be 0, otherwise the command is not executed.";
CM_ SG_ 387 AMK_TargetVelocity "Speed setpoint [rpm]. Inverter limits setpoints to +/-30000 rpm (motor A2370DD: Nn 12000 rpm, no-load 18617 rpm).";
CM_ SG_ 387 AMK_TorqueLimitPositive "Positive torque limit, unit 0.1 % Mn (raw 1000 = 100 % Mn). Motor A2370DD: Mn = 9.8 Nm (ID32771), Mmax = 21 Nm ~ 214 % Mn.";
CM_ SG_ 387 AMK_TorqueLimitNegative "Negative torque limit, unit 0.1 % Mn (raw -1000 = -100 % Mn). Motor A2370DD: Mn = 9.8 Nm, Mmax = 21 Nm ~ 214 % Mn.";
CM_ SG_ 642 AMK_bSystemReady "System ready, SBM (AMK_Status bit 8).";
CM_ SG_ 642 AMK_bError "Error (AMK_Status bit 9). Diagnostic number in AMK_ErrorInfo.";
CM_ SG_ 642 AMK_bWarn "Warning (AMK_Status bit 10).";
CM_ SG_ 642 AMK_bQuitDcOn "HV activation acknowledgment (AMK_Status bit 11).";
CM_ SG_ 642 AMK_bDcOn "HV activation level (AMK_Status bit 12).";
CM_ SG_ 642 AMK_bQuitInverterOn "Controller enable acknowledgment (AMK_Status bit 13). Reset when motor control is deactivated after an error.";
CM_ SG_ 642 AMK_bInverterOn "Controller enable level (AMK_Status bit 14).";
CM_ SG_ 642 AMK_bDerating "Derating, torque limitation active (AMK_Status bit 15).";
CM_ SG_ 642 AMK_ActualVelocity "Actual speed value [rpm].";
CM_ SG_ 642 AMK_TorqueCurrent "Actual torque current Iq. Iq[A] = raw * ID110 / 16384. Factor assumes ID110 'Converter peak current' = 107 A (KW26-S5-FSE-4Q Imax) - verify ID110 in AIPEX.";
CM_ SG_ 642 AMK_MagnetizingCurrent "Actual magnetizing (field weakening) current Id. Id[A] = raw * ID110 / 16384. Factor assumes ID110 = 107 A - verify in AIPEX.";
CM_ SG_ 643 AMK_TempMotor "Motor temperature [0.1 degC] (KTY84 on X12). Torque reduction default 125.0-140.0 degC (ID32798-11/12).";
CM_ SG_ 643 AMK_TempInverter "Inverter cold plate temperature [0.1 degC]. Torque reduction default 50.0-60.0 degC (ID32798-5/6).";
CM_ SG_ 643 AMK_ErrorInfo "Diagnostic number (AMK ID390), see PDK_025786_Diagnose. 0 = no diagnostic. 3587 = CAN error during operation (e.g. setpoint telegram missing > 50 ms).";
CM_ SG_ 643 AMK_TempIGBT "IGBT temperature [0.1 degC].";
CM_ BO_ 388 "Rear Right AMK Setpoints 1: control word + setpoints (PC -> inverter). Telegram failure monitoring: error if no telegram > 50 ms.";
CM_ BO_ 644 "Rear Right AMK Actual Values 1: status word + actual values.";
CM_ BO_ 645 "Rear Right AMK Actual Values 2: temperatures + diagnostic number.";
CM_ SG_ 388 AMK_bInverterOn "Controller enable (AMK_Control bit 8). Motor control also needs HW RF signal X140 BE1 + AMK_bEnable.";
CM_ SG_ 388 AMK_bDcOn "HV activation (AMK_Control bit 9).";
CM_ SG_ 388 AMK_bEnable "Driver enable (AMK_Control bit 10).";
CM_ SG_ 388 AMK_bErrorReset "Remove error (AMK_Control bit 11). All setpoints must be 0, otherwise the command is not executed.";
CM_ SG_ 388 AMK_TargetVelocity "Speed setpoint [rpm]. Inverter limits setpoints to +/-30000 rpm (motor A2370DD: Nn 12000 rpm, no-load 18617 rpm).";
CM_ SG_ 388 AMK_TorqueLimitPositive "Positive torque limit, unit 0.1 % Mn (raw 1000 = 100 % Mn). Motor A2370DD: Mn = 9.8 Nm (ID32771), Mmax = 21 Nm ~ 214 % Mn.";
CM_ SG_ 388 AMK_TorqueLimitNegative "Negative torque limit, unit 0.1 % Mn (raw -1000 = -100 % Mn). Motor A2370DD: Mn = 9.8 Nm, Mmax = 21 Nm ~ 214 % Mn.";
CM_ SG_ 644 AMK_bSystemReady "System ready, SBM (AMK_Status bit 8).";
CM_ SG_ 644 AMK_bError "Error (AMK_Status bit 9). Diagnostic number in AMK_ErrorInfo.";
CM_ SG_ 644 AMK_bWarn "Warning (AMK_Status bit 10).";
CM_ SG_ 644 AMK_bQuitDcOn "HV activation acknowledgment (AMK_Status bit 11).";
CM_ SG_ 644 AMK_bDcOn "HV activation level (AMK_Status bit 12).";
CM_ SG_ 644 AMK_bQuitInverterOn "Controller enable acknowledgment (AMK_Status bit 13). Reset when motor control is deactivated after an error.";
CM_ SG_ 644 AMK_bInverterOn "Controller enable level (AMK_Status bit 14).";
CM_ SG_ 644 AMK_bDerating "Derating, torque limitation active (AMK_Status bit 15).";
CM_ SG_ 644 AMK_ActualVelocity "Actual speed value [rpm].";
CM_ SG_ 644 AMK_TorqueCurrent "Actual torque current Iq. Iq[A] = raw * ID110 / 16384. Factor assumes ID110 'Converter peak current' = 107 A (KW26-S5-FSE-4Q Imax) - verify ID110 in AIPEX.";
CM_ SG_ 644 AMK_MagnetizingCurrent "Actual magnetizing (field weakening) current Id. Id[A] = raw * ID110 / 16384. Factor assumes ID110 = 107 A - verify in AIPEX.";
CM_ SG_ 645 AMK_TempMotor "Motor temperature [0.1 degC] (KTY84 on X12). Torque reduction default 125.0-140.0 degC (ID32798-11/12).";
CM_ SG_ 645 AMK_TempInverter "Inverter cold plate temperature [0.1 degC]. Torque reduction default 50.0-60.0 degC (ID32798-5/6).";
CM_ SG_ 645 AMK_ErrorInfo "Diagnostic number (AMK ID390), see PDK_025786_Diagnose. 0 = no diagnostic. 3587 = CAN error during operation (e.g. setpoint telegram missing > 50 ms).";
CM_ SG_ 645 AMK_TempIGBT "IGBT temperature [0.1 degC].";
CM_ BO_ 389 "Front Right AMK Setpoints 1: control word + setpoints (PC -> inverter). Telegram failure monitoring: error if no telegram > 50 ms.";
CM_ BO_ 646 "Front Right AMK Actual Values 1: status word + actual values.";
CM_ BO_ 647 "Front Right AMK Actual Values 2: temperatures + diagnostic number.";
CM_ SG_ 389 AMK_bInverterOn "Controller enable (AMK_Control bit 8). Motor control also needs HW RF signal X140 BE1 + AMK_bEnable.";
CM_ SG_ 389 AMK_bDcOn "HV activation (AMK_Control bit 9).";
CM_ SG_ 389 AMK_bEnable "Driver enable (AMK_Control bit 10).";
CM_ SG_ 389 AMK_bErrorReset "Remove error (AMK_Control bit 11). All setpoints must be 0, otherwise the command is not executed.";
CM_ SG_ 389 AMK_TargetVelocity "Speed setpoint [rpm]. Inverter limits setpoints to +/-30000 rpm (motor A2370DD: Nn 12000 rpm, no-load 18617 rpm).";
CM_ SG_ 389 AMK_TorqueLimitPositive "Positive torque limit, unit 0.1 % Mn (raw 1000 = 100 % Mn). Motor A2370DD: Mn = 9.8 Nm (ID32771), Mmax = 21 Nm ~ 214 % Mn.";
CM_ SG_ 389 AMK_TorqueLimitNegative "Negative torque limit, unit 0.1 % Mn (raw -1000 = -100 % Mn). Motor A2370DD: Mn = 9.8 Nm, Mmax = 21 Nm ~ 214 % Mn.";
CM_ SG_ 646 AMK_bSystemReady "System ready, SBM (AMK_Status bit 8).";
CM_ SG_ 646 AMK_bError "Error (AMK_Status bit 9). Diagnostic number in AMK_ErrorInfo.";
CM_ SG_ 646 AMK_bWarn "Warning (AMK_Status bit 10).";
CM_ SG_ 646 AMK_bQuitDcOn "HV activation acknowledgment (AMK_Status bit 11).";
CM_ SG_ 646 AMK_bDcOn "HV activation level (AMK_Status bit 12).";
CM_ SG_ 646 AMK_bQuitInverterOn "Controller enable acknowledgment (AMK_Status bit 13). Reset when motor control is deactivated after an error.";
CM_ SG_ 646 AMK_bInverterOn "Controller enable level (AMK_Status bit 14).";
CM_ SG_ 646 AMK_bDerating "Derating, torque limitation active (AMK_Status bit 15).";
CM_ SG_ 646 AMK_ActualVelocity "Actual speed value [rpm].";
CM_ SG_ 646 AMK_TorqueCurrent "Actual torque current Iq. Iq[A] = raw * ID110 / 16384. Factor assumes ID110 'Converter peak current' = 107 A (KW26-S5-FSE-4Q Imax) - verify ID110 in AIPEX.";
CM_ SG_ 646 AMK_MagnetizingCurrent "Actual magnetizing (field weakening) current Id. Id[A] = raw * ID110 / 16384. Factor assumes ID110 = 107 A - verify in AIPEX.";
CM_ SG_ 647 AMK_TempMotor "Motor temperature [0.1 degC] (KTY84 on X12). Torque reduction default 125.0-140.0 degC (ID32798-11/12).";
CM_ SG_ 647 AMK_TempInverter "Inverter cold plate temperature [0.1 degC]. Torque reduction default 50.0-60.0 degC (ID32798-5/6).";
CM_ SG_ 647 AMK_ErrorInfo "Diagnostic number (AMK ID390), see PDK_025786_Diagnose. 0 = no diagnostic. 3587 = CAN error during operation (e.g. setpoint telegram missing > 50 ms).";
CM_ SG_ 647 AMK_TempIGBT "IGBT temperature [0.1 degC].";
CM_ BO_ 390 "Front Left AMK Setpoints 1: control word + setpoints (PC -> inverter). Telegram failure monitoring: error if no telegram > 50 ms.";
CM_ BO_ 648 "Front Left AMK Actual Values 1: status word + actual values.";
CM_ BO_ 649 "Front Left AMK Actual Values 2: temperatures + diagnostic number.";
CM_ SG_ 390 AMK_bInverterOn "Controller enable (AMK_Control bit 8). Motor control also needs HW RF signal X140 BE1 + AMK_bEnable.";
CM_ SG_ 390 AMK_bDcOn "HV activation (AMK_Control bit 9).";
CM_ SG_ 390 AMK_bEnable "Driver enable (AMK_Control bit 10).";
CM_ SG_ 390 AMK_bErrorReset "Remove error (AMK_Control bit 11). All setpoints must be 0, otherwise the command is not executed.";
CM_ SG_ 390 AMK_TargetVelocity "Speed setpoint [rpm]. Inverter limits setpoints to +/-30000 rpm (motor A2370DD: Nn 12000 rpm, no-load 18617 rpm).";
CM_ SG_ 390 AMK_TorqueLimitPositive "Positive torque limit, unit 0.1 % Mn (raw 1000 = 100 % Mn). Motor A2370DD: Mn = 9.8 Nm (ID32771), Mmax = 21 Nm ~ 214 % Mn.";
CM_ SG_ 390 AMK_TorqueLimitNegative "Negative torque limit, unit 0.1 % Mn (raw -1000 = -100 % Mn). Motor A2370DD: Mn = 9.8 Nm, Mmax = 21 Nm ~ 214 % Mn.";
CM_ SG_ 648 AMK_bSystemReady "System ready, SBM (AMK_Status bit 8).";
CM_ SG_ 648 AMK_bError "Error (AMK_Status bit 9). Diagnostic number in AMK_ErrorInfo.";
CM_ SG_ 648 AMK_bWarn "Warning (AMK_Status bit 10).";
CM_ SG_ 648 AMK_bQuitDcOn "HV activation acknowledgment (AMK_Status bit 11).";
CM_ SG_ 648 AMK_bDcOn "HV activation level (AMK_Status bit 12).";
CM_ SG_ 648 AMK_bQuitInverterOn "Controller enable acknowledgment (AMK_Status bit 13). Reset when motor control is deactivated after an error.";
CM_ SG_ 648 AMK_bInverterOn "Controller enable level (AMK_Status bit 14).";
CM_ SG_ 648 AMK_bDerating "Derating, torque limitation active (AMK_Status bit 15).";
CM_ SG_ 648 AMK_ActualVelocity "Actual speed value [rpm].";
CM_ SG_ 648 AMK_TorqueCurrent "Actual torque current Iq. Iq[A] = raw * ID110 / 16384. Factor assumes ID110 'Converter peak current' = 107 A (KW26-S5-FSE-4Q Imax) - verify ID110 in AIPEX.";
CM_ SG_ 648 AMK_MagnetizingCurrent "Actual magnetizing (field weakening) current Id. Id[A] = raw * ID110 / 16384. Factor assumes ID110 = 107 A - verify in AIPEX.";
CM_ SG_ 649 AMK_TempMotor "Motor temperature [0.1 degC] (KTY84 on X12). Torque reduction default 125.0-140.0 degC (ID32798-11/12).";
CM_ SG_ 649 AMK_TempInverter "Inverter cold plate temperature [0.1 degC]. Torque reduction default 50.0-60.0 degC (ID32798-5/6).";
CM_ SG_ 649 AMK_ErrorInfo "Diagnostic number (AMK ID390), see PDK_025786_Diagnose. 0 = no diagnostic. 3587 = CAN error during operation (e.g. setpoint telegram missing > 50 ms).";
CM_ SG_ 649 AMK_TempIGBT "IGBT temperature [0.1 degC].";

BA_DEF_ BO_ "GenMsgCycleTime" INT 0 65535;
BA_DEF_ SG_ "GenSigStartValue" FLOAT -100000 100000;
BA_DEF_DEF_ "GenMsgCycleTime" 0;
BA_DEF_DEF_ "GenSigStartValue" 0;

BA_ "GenMsgCycleTime" BO_ 387 5;
BA_ "GenMsgCycleTime" BO_ 642 5;
BA_ "GenMsgCycleTime" BO_ 643 5;
BA_ "GenMsgCycleTime" BO_ 388 5;
BA_ "GenMsgCycleTime" BO_ 644 5;
BA_ "GenMsgCycleTime" BO_ 645 5;
BA_ "GenMsgCycleTime" BO_ 389 5;
BA_ "GenMsgCycleTime" BO_ 646 5;
BA_ "GenMsgCycleTime" BO_ 647 5;
BA_ "GenMsgCycleTime" BO_ 390 5;
BA_ "GenMsgCycleTime" BO_ 648 5;
BA_ "GenMsgCycleTime" BO_ 649 5;

BA_ "GenSigStartValue" SG_ 387 AMK_TorqueLimitPositive 1000;
BA_ "GenSigStartValue" SG_ 388 AMK_TorqueLimitPositive 1000;
BA_ "GenSigStartValue" SG_ 389 AMK_TorqueLimitPositive 1000;
BA_ "GenSigStartValue" SG_ 390 AMK_TorqueLimitPositive 1000;

BA_ "GenSigStartValue" SG_ 387 AMK_TorqueLimitNegative -1000;
BA_ "GenSigStartValue" SG_ 388 AMK_TorqueLimitNegative -1000;
BA_ "GenSigStartValue" SG_ 389 AMK_TorqueLimitNegative -1000;
BA_ "GenSigStartValue" SG_ 390 AMK_TorqueLimitNegative -1000;

VAL_ 642 AMK_bSystemReady 0 "Not_Ready" 1 "System_Ready" ;
VAL_ 642 AMK_bError 0 "No_Error" 1 "Error_Active" ;
VAL_ 642 AMK_bWarn 0 "No_Warning" 1 "Warning_Active" ;
VAL_ 642 AMK_bQuitDcOn 0 "Not_Acknowledged" 1 "Acknowledged" ;
VAL_ 642 AMK_bDcOn 0 "HV_Off" 1 "HV_On" ;
VAL_ 642 AMK_bQuitInverterOn 0 "Not_Acknowledged" 1 "Acknowledged" ;
VAL_ 642 AMK_bInverterOn 0 "Inverter_Off" 1 "Inverter_On" ;
VAL_ 642 AMK_bDerating 0 "No_Derating" 1 "Derating_Active" ;

VAL_ 644 AMK_bSystemReady 0 "Not_Ready" 1 "System_Ready" ;
VAL_ 644 AMK_bError 0 "No_Error" 1 "Error_Active" ;
VAL_ 644 AMK_bWarn 0 "No_Warning" 1 "Warning_Active" ;
VAL_ 644 AMK_bQuitDcOn 0 "Not_Acknowledged" 1 "Acknowledged" ;
VAL_ 644 AMK_bDcOn 0 "HV_Off" 1 "HV_On" ;
VAL_ 644 AMK_bQuitInverterOn 0 "Not_Acknowledged" 1 "Acknowledged" ;
VAL_ 644 AMK_bInverterOn 0 "Inverter_Off" 1 "Inverter_On" ;
VAL_ 644 AMK_bDerating 0 "No_Derating" 1 "Derating_Active" ;

VAL_ 646 AMK_bSystemReady 0 "Not_Ready" 1 "System_Ready" ;
VAL_ 646 AMK_bError 0 "No_Error" 1 "Error_Active" ;
VAL_ 646 AMK_bWarn 0 "No_Warning" 1 "Warning_Active" ;
VAL_ 646 AMK_bQuitDcOn 0 "Not_Acknowledged" 1 "Acknowledged" ;
VAL_ 646 AMK_bDcOn 0 "HV_Off" 1 "HV_On" ;
VAL_ 646 AMK_bQuitInverterOn 0 "Not_Acknowledged" 1 "Acknowledged" ;
VAL_ 646 AMK_bInverterOn 0 "Inverter_Off" 1 "Inverter_On" ;
VAL_ 646 AMK_bDerating 0 "No_Derating" 1 "Derating_Active" ;

VAL_ 648 AMK_bSystemReady 0 "Not_Ready" 1 "System_Ready" ;
VAL_ 648 AMK_bError 0 "No_Error" 1 "Error_Active" ;
VAL_ 648 AMK_bWarn 0 "No_Warning" 1 "Warning_Active" ;
VAL_ 648 AMK_bQuitDcOn 0 "Not_Acknowledged" 1 "Acknowledged" ;
VAL_ 648 AMK_bDcOn 0 "HV_Off" 1 "HV_On" ;
VAL_ 648 AMK_bQuitInverterOn 0 "Not_Acknowledged" 1 "Acknowledged" ;
VAL_ 648 AMK_bInverterOn 0 "Inverter_Off" 1 "Inverter_On" ;
VAL_ 648 AMK_bDerating 0 "No_Derating" 1 "Derating_Active" ;

VAL_ 387 AMK_bInverterOn 0 "Disable" 1 "Enable" ;
VAL_ 387 AMK_bDcOn 0 "Disable" 1 "Enable" ;
VAL_ 387 AMK_bEnable 0 "Disable" 1 "Enable" ;
VAL_ 387 AMK_bErrorReset 0 "No_Action" 1 "Reset_Error" ;

VAL_ 388 AMK_bInverterOn 0 "Disable" 1 "Enable" ;
VAL_ 388 AMK_bDcOn 0 "Disable" 1 "Enable" ;
VAL_ 388 AMK_bEnable 0 "Disable" 1 "Enable" ;
VAL_ 388 AMK_bErrorReset 0 "No_Action" 1 "Reset_Error" ;

VAL_ 389 AMK_bInverterOn 0 "Disable" 1 "Enable" ;
VAL_ 389 AMK_bDcOn 0 "Disable" 1 "Enable" ;
VAL_ 389 AMK_bEnable 0 "Disable" 1 "Enable" ;
VAL_ 389 AMK_bErrorReset 0 "No_Action" 1 "Reset_Error" ;

VAL_ 390 AMK_bInverterOn 0 "Disable" 1 "Enable" ;
VAL_ 390 AMK_bDcOn 0 "Disable" 1 "Enable" ;
VAL_ 390 AMK_bEnable 0 "Disable" 1 "Enable" ;
VAL_ 390 AMK_bErrorReset 0 "No_Action" 1 "Reset_Error" ;

VAL_ 643 AMK_ErrorInfo 0 "0 No diagnostic" 257 "257 System diagnostics: SBM withdrawal" 258 "258 Leave RF active" 259 "259 System diagnostics: SBM withdrawal" 514 "514 System diagnostics: Check parallel EEPROM on the control board" 515 "515 System diagnostics: Check parallel EEPROM on the control board" 516 "516 System diagnostics: Check AZ(X27)-AW(X57)-BUS" 517 "517 System diagnostics: Check AZ(X27)-AW(X57)-BUS" 518 "518 System diagnostics" 519 "519 System diagnostics: SEEP in the inverter cannot be addressed" 520 "520 System diagnostics: SEEP in the inverter cannot be addressed" 521 "521 System diagnostics" 770 "770 System diagnostics" 771 "771 System diagnostics: Check parallel EEPROM on the control board" 772 "772 System diagnostics: Check parallel EEPROM on the control board" 773 "773 System diagnostics: Inadmissible database order" 774 "774 System diagnostics" 775 "775 System diagnostics: ID not supported" 776 "776 System diagnostics: It was attempted to use a parameter set which was not reserved for..." 777 "777 System diagnostics: Check parallel EEPROM on the control board" 778 "778 System diagnostics: The attribute of the selected data block is wrong" 779 "779 System diagnostics: The maximum value of the last changed parameter was exceeded" 780 "780 System diagnostics: The minimum value of the last changed parameter was not reached" 781 "781 System diagnostics: It was attempted to write a list which can only be read" 783 "783 System diagnostics: Error at distributing parameters during internal system update" 1024 "1024 System diagnostics: System fault in the control board area" 1025 "1025 System diagnostics" 1026 "1026 System diagnostics: Error on writing the serial EEPROM" 1027 "1027 System diagnostics: Data error in the EPROM" 1028 "1028 System diagnostics: RAM memory error, is checked during system initialization" 1029 "1029 System diagnostics: Data error in the parallel EEPROM" 1030 "1030 System diagnostics: Error on writing the parallel EEPROM" 1031 "1031 System diagnostics: Control panel does not report on initialization" 1032 "1032 System diagnostics: Reception error from the serial interface 1" 1033 "1033 System diagnostics: Reception error from the serial interface 2" 1034 "1034 System diagnostics: Time level overflow" 1035 "1035 System diagnostics: Faulty system initialization, possible external fault" 1036 "1036 System diagnostics: Fault" 1037 "1037 System diagnostics: Fault" 1038 "1038 System diagnostics: Fault" 1039 "1039 System diagnostics: Faulty memory access of the processor. Software reset is triggered...." 1040 "1040 Tripzone" 1041 "1041 Overtemperature external component mains" 1042 "1042 Mains phase fault" 1043 "1043 Line Voltage Error" 1044 "1044 No SBM" 1045 "1045 Mains overvoltage" 1046 "1046 Mains undervoltage" 1047 "1047 Inhibit time for UE" 1048 "1048 UE switching frequency too high" 1049 "1049 DC bus" 1050 "1050 Phase error L1" 1051 "1051 Phase error L2" 1052 "1052 Phase error L3" 1053 "1053 Phase sequence L1/L2" 1054 "1054 Phase sequence L1/L3" 1055 "1055 Phase sequence L2/L3" 1056 "1056 Mains phase sequence L1, L2 , L3" 1057 "1057 Fault +12 V" 1058 "1058 Fault -12 V" 1059 "1059 DC bus overvoltage" 1060 "1060 Regeneration fault" 1061 "1061 Braking transistor fault" 1062 "1062 System diagnostics" 1063 "1063 System diagnostics" 1064 "1064 System diagnostics" 1065 "1065 System diagnostics: QUE missing on RF activation" 1066 "1066 System diagnostics" 1067 "1067 System diagnostics: Fault DC bus" 1068 "1068 System diagnostics" 1069 "1069 System diagnostics" 1070 "1070 System diagnostics: FL not possible (timeout 20 s)" 1071 "1071 System diagnostics: Brake acknowledgment does not correspond to the expected value" 1072 "1072 System diagnostics" 1073 "1073 Cooling Air Temperature Warning" 1074 "1074 External line component temperature warning" 1075 "1075 Power supply unit temperature warning" 1076 "1076 Feed / Regeneration temperature warning" 1077 "1077 Line Voltage warning" 1078 "1078 Line undervoltage warning" 1079 "1079 System diagnostics: All square wave encoder breakage messages are displayed only with a..." 1080 "1080 Encoder line break analysis on option card, input 1 slot 1" 1081 "1081 Encoder line break analysis on option card, input 2 slot 1" 1082 "1082 Encoder line break analysis on option card, input 3 slot 1" 1083 "1083 Encoder line break analysis on option card, input 4 slot 1" 1084 "1084 Encoder line break analysis on option card, input 1 slot 2" 1085 "1085 Encoder line break analysis on option card, input 2 slot 2" 1086 "1086 Encoder line break analysis on option card, input 3 slot 2" 1087 "1087 Encoder line break analysis on option card, input 4 slot 2" 1088 "1088 Encoder line break analysis on option card, input 1 slot 3" 1089 "1089 Encoder line break analysis on option card, input 2 slot 3" 1090 "1090 Encoder line break analysis on option card, input 3 slot 3" 1091 "1091 Encoder line break analysis on option card, input 4 slot 3" 1092 "1092 Encoder line break analysis on option card, input 1 slot 4" 1093 "1093 Encoder line break analysis on option card, input 2 slot 4" 1094 "1094 Encoder line break analysis on option card, input 3 slot 4" 1095 "1095 Encoder line break analysis on option card, input 4 slot 4" 1096 "1096 Short-circuit/overload of the outputs option card, slot 1 (e.g. AZ-EA8 or AZ-EA24)" 1097 "1097 Short-circuit / overload of the outputs option card, slot 2 (e.g. AZ-EA8 or AZ-EA24)" 1098 "1098 Short-circuit/overload of the outputs option card, slot 3 (e.g. AZ-EA8 or AZ-EA24)" 1099 "1099 Short-circuit/overload of the outputs option card, slot 4 (e.g. AZ-EA8 or AZ-EA24)" 1100 "1100 System diagnostics: Short-circuit / overload digital outputs" 1101 "1101 Logic voltage error" 1102 "1102 Line voltage limit" 1103 "1103 Field bus warning" 1104 "1104 No FL with RF active" 1105 "1105 Reserved" 1106 "1106 System diagnostic" 1107 "1107 System diagnostics: Short circuit DC bus voltage" 1108 "1108 System diagnostics: Main contactor" 1109 "1109 System diagnostics: Shifting of Y-point" 1110 "1110 Warning brake transistor" 1111 "1111 Warning external component" 1112 "1112 Overload error external component" 1115 "1115 Communication monitoring" 1281 "1281 System diagnostics" 1282 "1282 ID32777, ID111, ID32769" 1283 "1283 ID111, ID32769" 1284 "1284 ID111, ID32769" 1285 "1285 ID32772 wrong" 1286 "1286 ID82 or ID83 too large" 1287 "1287 ID32890: 1, 2, 5, 10" 1288 "1288 ID110, ID111, ID32769" 1289 "1289 ID83 too small" 1290 "1290 ID82 too large" 1291 "1291 ID32774 faulty" 1292 "1292 SEEP checksum" 1293 "1293 Boot strap EEPROM" 1294 "1294 EEPROM defective" 1295 "1295 ID100 / ID101" 1296 "1296 ID211 / ID209 / ID210" 1297 "1297 ID212 / ID209 / ID210" 1298 "1298 ID100 faulty" 1299 "1299 ID32775: even" 1300 "1300 Error in Temporary Parameters" 1301 "1301 ID32778 faulty" 1302 "1302 System diagnostics: Operating mode incomplete, see 'ID32800 AMK main operating mode' et..." 1303 "1303 System diagnostics: Operating mode incomplete, see 'ID32800 AMK main operating mode' et..." 1304 "1304 System diagnostics: Operating mode incomplete, see 'ID32800 AMK main operating mode' et..." 1305 "1305 System diagnostics: Operating mode incomplete, see 'ID32800 AMK main operating mode' et..." 1306 "1306 System diagnostics: Operating mode incomplete, see 'ID32800 AMK main operating mode' et..." 1307 "1307 System diagnostics: Position resolution not realizable" 1308 "1308 System diagnostics: Resolution of the “Speed source pulses” source not realizable" 1309 "1309 System diagnostics: Speed window larger than 107372.5 rpm" 1310 "1310 System diagnostics: “Pole factor POLF” calculation out of tolerance" 1311 "1311 System diagnostics: 4 GPZ calculation inconclusive" 1312 "1312 System diagnostics: Negated direction of rotation permissible only for A and I encoders" 1313 "1313 ID82 less then ID83" 1314 "1314 System diagnostics" 1315 "1315 System diagnostics: Resolver 0 point shift inadmissible" 1316 "1316 ID32769/ID100 too large" 1317 "1317 ID32770/ID110 too large" 1318 "1318 ID32774 faulty" 1319 "1319 System diagnostics: Configuration of “Strobe” binary input wrong" 1320 "1320 System diagnostics" 1321 "1321 System diagnostics" 1322 "1322 System diagnostics" 1323 "1323 ID32769 IM < ID111 IN" 1324 "1324 ID32772 nN too large" 1325 "1325 ID32772 P1 reference" 1326 "1326 System diagnostics: Source converter/on (UE) incorrect" 1327 "1327 ID104 kv factor" 1328 "1328 System diagnostics" 1329 "1329 ID111/ID110 > 80%" 1330 "1330 ID32772 > ID113" 1331 "1331 ID209 > ID113" 1332 "1332 ID210 > ID113" 1333 "1333 System diagnostics: 'ID32780 Acceleration ramp' resp. 'ID32781 Deceleration ramp' are t..." 1334 "1334 ID38 > ID113" 1335 "1335 |ID39| > ID113" 1336 "1336 ID32778 > ID113" 1337 "1337 ID32783 > ID113" 1338 "1338 ID157 > ID113" 1339 "1339 ID125 > ID113" 1340 "1340 ID124 > ID113" 1341 "1341 AW-Imax wrong (SEEP)" 1342 "1342 System diagnostics: External error" 1343 "1343 System diagnostics: Internal fault or component failure" 1344 "1344 System diagnostics: Internal fault or component failure (AWMON)" 1345 "1345 System diagnostics: Internal fault or component failure (wrong BAV order)" 1346 "1346 System diagnostics: Internal fault or component failure (Handshake BAV/DTH)" 1347 "1347 System diagnostics: Internal fault or component failure (Handshake BAV/PEEP)" 1348 "1348 System diagnostics: Internal fault or component failure (Handshake BAV/AWMON)" 1349 "1349 System diagnostics: Internal fault or component failure" 1350 "1350 AW not present" 1351 "1351 AW not active" 1352 "1352 Can be changed only offline" 1353 "1353 Parameter Set change wrong" 1354 "1354 Im < Im1" 1355 "1355 Date ID32785" 1356 "1356 Date ID32785, ID32786" 1357 "1357 AWNR ID32787, ID32789, ID32791, ID32793" 1358 "1358 Source ID32787, ID32789, ID32791, ID32793" 1359 "1359 ID32873, ID32968, ID32977" 1360 "1360 Opt.1 ID32846, ID32855, ID32864" 1361 "1361 Opt.2 ID32846, ID32855, ID32864" 1362 "1362 Opt.3 ID32846, ID32855, ID32864" 1363 "1363 Opt.4 ID32846, ID32855, ID32864" 1364 "1364 Definition of output bits" 1365 "1365 AWNR output bit" 1366 "1366 Definition of input bits" 1367 "1367 ID32883 Option place 1" 1368 "1368 ID32884 Option place 2" 1369 "1369 ID32885 Option place 3" 1370 "1370 ID32886 Option place 4" 1371 "1371 ID32799 Standard Periphery" 1372 "1372 Option place 1 card defect" 1373 "1373 Option place 2 card defect" 1374 "1374 Option place 3 card defect" 1375 "1375 Option place 4 card defect" 1376 "1376 ID32882 Option place 1" 1377 "1377 ID32882 Option place 2" 1378 "1378 ID32882 Option place 3" 1379 "1379 ID32882 Option place 4" 1380 "1380 ID110, ID111, ID32769" 1381 "1381 LIW source calculation" 1382 "1382 System diagnostics" 1383 "1383 2PI value wrong" 1384 "1384 2PI value calculation" 1385 "1385 ID116, ID32776 ratio" 1386 "1386 Output DA1 … DA4" 1387 "1387 ID32846 wrong" 1388 "1388 ID32855 wrong" 1389 "1389 ID32864 wrong" 1390 "1390 System diagnostics: NC/LR time not integral." 1391 "1391 ID32772 wrong" 1392 "1392 ID158, ID32771, ID32772" 1393 "1393 AW not AZ-compatible" 1394 "1394 ID32892: x times 2 to the power 16" 1395 "1395 No Main Operation Mode" 1396 "1396 Operation mode not defined" 1397 "1397 Operation mode not impl." 1398 "1398 Setpoint source undefined" 1399 "1399 Setpoint Source (SQ) is Not Admissible in this Operation Mode (BA)" 1400 "1400 Option Card for Setpoint Source (SQ)" 1401 "1401 MGQ not selected" 1402 "1402 Source of Torque Limit (MGQ) inadmissible for this Operation Mode (BA)" 1403 "1403 Source of Torque Limit (MGQ) not implemented" 1404 "1404 Source of Torque Limit (MGQ) AW-analog assigned" 1405 "1405 Speed Ramp (DZLRMP) function missing" 1406 "1406 Speed Filter (DZLFLT) function missing" 1407 "1407 Selected Operation Mode (BA) not configured" 1408 "1408 Change of Operation Mode (BA) not executable" 1409 "1409 Selected AW No. not active" 1410 "1410 Selected Parameter Set" 1411 "1411 Type of Position Controller is Inadmissible" 1412 "1412 Type of External Encoder inadmissible" 1413 "1413 Missing option card" 1414 "1414 Unknown AW type" 1415 "1415 Wrong AW type" 1416 "1416 Change of Operation Mode inadmissible" 1417 "1417 System diagnostics: The chosen operation mode cannot be mapped" 1418 "1418 System diagnostics: The chosen operation mode cannot be mapped" 1419 "1419 System diagnostics: Speed filter activated but parameterised wrongly" 1420 "1420 System diagnostics: Speed ramp is activated but the ramp parameters are asymmetric or f..." 1421 "1421 System diagnostics: 'ID82 Positive torque limit' faulty" 1422 "1422 System diagnostics: Internal lists of controller configuration do not fit the operation..." 1423 "1423 Inadmissible Setpoint Source" 1424 "1424 Inadmissible Setpoint Source" 1425 "1425 Polarity" 1426 "1426 ID121/122 wrong" 1427 "1427 ID44 inadmissible" 1428 "1428 ID86 inadmissible" 1429 "1429 ID160 inadmissible" 1430 "1430 Position scaling" 1431 "1431 Velocity scaling" 1432 "1432 Velocity scaling IPO" 1433 "1433 Torque scaling" 1434 "1434 Acceleration scaling" 1435 "1435 ID76 inadmissible" 1436 "1436 Decade switch" 1438 "1438 Band width barrier" 1440 "1440 Data record changed" 1441 "1441 Clock synchronization" 1442 "1442 SEEP configuration" 1443 "1443 Test generator" 1444 "1444 PWM frequency" 1445 "1445 Current controller" 1446 "1446 EF can not be activated" 1447 "1447 Motor encoder gear" 1448 "1448 ID113 > ID34153" 1451 "1451 Configuration temperature sensor" 1453 "1453 Feed forward control" 1454 "1454 Error initialisation angle observer" 1455 "1455 Plausibility I/O" 1456 "1456 Ratio ID33194 to ID33195 incorrect" 1457 "1457 ID38 less then ID39" 1537 "1537 System diagnostics: SEEP error in the inverter" 1538 "1538 System diagnostics: Taskmaster- / taskslave combination is inadmissible" 1539 "1539 SEEP 1st checksum" 1540 "1540 SEEP 2nd checksum" 1541 "1541 Commanded AW missing" 1542 "1542 System diagnostics" 1543 "1543 System diagnostics: The manufacturer information was not written correctly in the SEEP" 1544 "1544 ID32953 no adjustment permissible" 1545 "1545 System diagnostics: Errors occurred when writing the current encoder values in the SEEP..." 1546 "1546 System diagnostics: Fault counter is missing" 1547 "1547 System diagnostics" 1548 "1548 System diagnostics" 1549 "1549 System diagnostics: Clock master / clock slave combination not permissible" 1550 "1550 System diagnostics: Clock master / clock slave combination not permissible" 1551 "1551 Encoder track failed" 1552 "1552 Encoder adjustment abort" 1553 "1553 Encoder adjustment timeout" 1554 "1554 ID32776 Sinus Encoder Period is faulty" 1555 "1555 Reference pulse" 1556 "1556 Reference Pulse - Encoder Input" 1557 "1557 Turn axis" 1558 "1558 System diagnostics: Inverter transfers faulty encoder feedback values" 1794 "1794 System diagnostics: Interpolator" 1795 "1795 System diagnostics: Interpolator" 1796 "1796 System diagnostics: Interpolator" 1797 "1797 System diagnostics: Interpolator" 1798 "1798 System diagnostics: Interpolator" 1799 "1799 System diagnostics: Interpolator" 1800 "1800 System diagnostics: Interpolator" 1801 "1801 System diagnostics: Interpolator" 1802 "1802 System diagnostics: Interpolator" 1803 "1803 System diagnostics: Interpolator" 1804 "1804 System diagnostics: Check final value (target value)" 1805 "1805 System diagnostics: Interpolator standardisation: dxifaktor with remainder ID136, ID137..." 1806 "1806 System diagnostics: Interpolator standardisation: dxifaktor = 0: increase ID136, ID137,..." 1807 "1807 System diagnostics: Permissible time between KMD commanding and BAV operation mode mana..." 1808 "1808 System diagnostics: Operation mode management acknowledges error after commanding" 1809 "1809 System diagnostics: Inadmissible commanding code in KMD-SS, check interface" 1810 "1810 System diagnostics: Inadmissible commanding function in KMD-SS, check interface" 1811 "1811 System diagnostics: Inverter can no longer be addressed" 1812 "1812 System diagnostics: Inverter can no longer be addressed" 1813 "1813 KMD user error" 1814 "1814 System diagnostics: Inadmissible commanding operation mode selected, BA may be assigned..." 1815 "1815 Controller enable missing" 1816 "1816 Not homed" 1817 "1817 System diagnostics: Synchronous running source in synchronous running inadmissible" 1818 "1818 System diagnostics" 1819 "1819 System diagnostics: Inverter address calculation impossible, operation mode incomplete" 1820 "1820 System diagnostics: Ramp down error e.g. in lifting axis function, time according to ID..." 1821 "1821 System diagnostics: IPO cannot perform direction change" 1822 "1822 System diagnostics: IPO cannot be activated" 1823 "1823 System diagnostics: IPO cannot be activated" 1824 "1824 System diagnostics: Inadmissible KMD code in KMD-SS, inadmissible timing check interface" 1825 "1825 System diagnostics: SINCOS encoder, encoder does not report within 2 sec. through RS485-SS" 1826 "1826 System diagnostics: SINCOS encoder, checksum of the encoder acknowledgement does not ag..." 1827 "1827 System diagnostics: Invalid encoder type, the SINCOS encoder type is not permitted in t..." 1828 "1828 System diagnostics: This message can occur only in connection with an abort of drive fu..." 1829 "1829 System diagnostics: 'ID55 Closed loop polarity' and 'ID43 Velocity polarity' may be onl..." 1830 "1830 System diagnostics: “Flying saw” drive function, waiting distance (ID278) is greater th..." 1831 "1831 System diagnostics: SINCOS encoder, encoder reports error (error bit set)" 1832 "1832 System diagnostics: “Absolute positioning” drive function" 1833 "1833 System diagnostics: “Lifting axis” drive function, |nactual| ≥ |1.2 x nlimit|" 1834 "1834 System diagnostics: SINCOS encoders: The difference of the double sampling of the absol..." 1835 "1835 System diagnostics: Special lift function" 1836 "1836 System diagnostics: Special Lift function" 1837 "1837 System diagnostics: Special Lift function" 1838 "1838 System diagnostics: Special Lift function" 1839 "1839 System diagnostics: Special Lift function" 1840 "1840 System diagnostics: Special Lift function" 1841 "1841 System diagnostics" 1842 "1842 System diagnostics: Special lift function" 1843 "1843 System diagnostics" 2049 "2049 System diagnostics" 2050 "2050 System diagnostics: ID address or ID property is not known" 2051 "2051 System diagnostics: Waiting time after order to logical subscriber is exceeded" 2052 "2052 System diagnostics: The ID to be edited is not contained in the database of the system" 2053 "2053 System diagnostics: Error acknowledgement in commanding the database" 2054 "2054 System diagnostics: Error acknowledgement in commanding the monitor" 2055 "2055 System diagnostics: Error acknowledgement in commanding the serial EEPROM" 2056 "2056 System diagnostics: Error acknowledgement in commanding the operation mode management" 2057 "2057 System diagnostics: Error acknowledgement in commanding the drive commanding KMD" 2058 "2058 System diagnostics: Error in LT → KMD commanding inverter, LT → KMD - logical subscribe..." 2059 "2059 System diagnostics: Error in LT→ KMD commanding AW2" 2060 "2060 System diagnostics: Error in LT → KMD commanding AW3" 2061 "2061 System diagnostics: Error in LT → KMD commanding AW4" 2062 "2062 System diagnostics: Error in LT → KMD commanding AW5" 2063 "2063 System diagnostics: Error in LT → KMD commanding AW6" 2064 "2064 System diagnostics: Error in LT → MD commanding AW7" 2065 "2065 System diagnostics: Error in LT → KMD commanding AW8" 2066 "2066 System diagnostics: Error acknowledgement in commanding a drive control" 2067 "2067 System diagnostics: Error acknowledgement in commanding the diagnostics" 2068 "2068 System diagnostics: Error acknowledgement in commanding the display function" 2069 "2069 System diagnostics: Error acknowledgement in commanding the lift function" 2070 "2070 System diagnostics: LT-SBUS, inverter not present" 2071 "2071 System diagnostics: Failure in the s-bus hardware; re-boot system or check hardware" 2072 "2072 System diagnostics: S-bus software received faulty information from connected device, c..." 2073 "2073 System diagnostics" 2074 "2074 System diagnostics: Disturbance of scope function" 2305 "2305 Phase U Short Circuit" 2306 "2306 Phase V Short Circuit" 2307 "2307 Phase W Short Circuit" 2308 "2308 Supply +12 V" 2309 "2309 Supply" 2310 "2310 Encoder communication" 2311 "2311 Encoder signal" 2312 "2312 Output Terminal Ground Fault" 2313 "2313 Synchronous running error" 2314 "2314 Master Synchronous Telegram AW" 2315 "2315 AW controller clock error" 2316 "2316 Motor direction of rotation" 2317 "2317 External encoder direction of rotation" 2318 "2318 Control deviation" 2319 "2319 n > nmax" 2320 "2320 EF inactive" 2321 "2321 System diagnostics: IGBT monitoring in PWM device detects overcurrent" 2322 "2322 System diagnostics: Inverter RAM memory error" 2323 "2323 System diagnostics: VECON watchdog" 2324 "2324 System diagnostics: Hardware significance in the AW SEEP invalid (M8030, 2 or 3 current..." 2325 "2325 System diagnostics: Error (timeout 5s) current controller adjustment" 2326 "2326 System diagnostics" 2327 "2327 Plausibility of the External Encoder" 2328 "2328 System diagnostics: Missing option card e.g. in the KU. For instance, if an AMK-A encod..." 2329 "2329 System diagnostics: Commutation error in synchronous machine with AMK-T encoder (SINCOS..." 2330 "2330 System diagnostics" 2331 "2331 System diagnostics: Ramp down error" 2332 "2332 System diagnostics" 2333 "2333 Position growth too large" 2334 "2334 System diagnostics: Output terminal overcurrent" 2335 "2335 Error reference pulse" 2336 "2336 System diagnostics: Current setpoint at the analog input of the slave AW was too large...." 2337 "2337 No clock enable acknowledgement" 2338 "2338 Magnetizing timeout" 2339 "2339 Ramp down error" 2340 "2340 Communication on AW" 2342 "2342 System diagnostics" 2343 "2343 System diagnostics" 2344 "2344 Monitoring actual position" 2345 "2345 Inverter overload error" 2346 "2346 Converter temperature error" 2347 "2347 Motor temperature error" 2348 "2348 System diagnostics" 2349 "2349 Inverter overload warning" 2350 "2350 Device temperature warning" 2351 "2351 Motor temperature warning" 2352 "2352 Motor overload warning" 2353 "2353 Motor overload error" 2354 "2354 Handshake brake" 2356 "2356 Setpoint stop active" 2357 "2357 Device overload warning" 2358 "2358 Device overload error" 2359 "2359 Motor overload warning" 2360 "2360 Motor overload error" 2361 "2361 EF Logic" 2362 "2362 Error Commutation Motor" 2365 "2365 Error angle observer" 2366 "2366 Limit switch" 2367 "2367 Error Non Dual Use" 2560 "2560 System diagnostics: EtherCAT" 2561 "2561 System diagnostics: SERCOS" 2562 "2562 System diagnostics: MDT reception error in the Comm.phase 3 or 4 Device Description Cla..." 2563 "2563 System diagnostics: SERCOS Device Description Invalid communication phase Class Error D..." 2564 "2564 System diagnostics: SERCOS" 2565 "2565 System diagnostics: Phase switchback (not on phase 0)" 2566 "2566 System diagnostics: Phase switchover without ready message" 2569 "2569 System diagnostics: Memory error (allocating)" 2570 "2570 System diagnostics: Memory error (deallocating)" 2571 "2571 System diagnostics: Timeout during communication phases switch-over (AS-PL)" 2572 "2572 System diagnostics: SERCOS" 2573 "2573 System diagnostics: SERCOS" 2574 "2574 System diagnostics: SERCOS" 2575 "2575 System diagnostics: In Kx-SC2 modules: ext. 48 V power supply is not available or has b..." 2576 "2576 System diagnostics" 2577 "2577 System diagnostics: Allocation of the real time control or real time status bit" 2578 "2578 System diagnostics: Test function active message (continuous light, zero bit stream)" 2579 "2579 System diagnostics: Error on initialization of the SERCOS option card" 2581 "2581 System diagnostics: SERCOS master driver initialization" 2582 "2582 System diagnostics: SERCOS master driver initialization" 2583 "2583 System diagnostics: SERCOS master configuration 'ID34036 CCB File'" 2584 "2584 System diagnostics: SERCOS master phase switchover" 2585 "2585 System diagnostics: SERCOS master time slot calculation" 2586 "2586 System diagnostics: SERCOS master service channel" 2587 "2587 System diagnostics: SERCOS master incorrect data in the service channel" 2588 "2588 System diagnostics: SERCOS master error in command execution" 2589 "2589 System diagnostics: SERCOS master has detected ring interruption" 2590 "2590 System diagnostics: SERCOS master has detected AT failure" 2591 "2591 System diagnostics: SERCOS master software error" 2592 "2592 System diagnostics: SERCOS master has detected MST failure" 2593 "2593 System diagnostics: SERCOS master real time error" 2594 "2594 System diagnostics: SERCOS master software error" 2595 "2595 System diagnostics: SERCOS" 2596 "2596 System diagnostics: SERCOS master has received the “error” acknowledgment to a command" 2597 "2597 System diagnostics: SERCOS master has received an error message from a remote node" 2598 "2598 System diagnostics: SERCOS has indicated a bad signal quality on the OWG receiver (exce..." 2599 "2599 System diagnostics: Error while activating the advanced operating mode" 2600 "2600 System diagnostics: Error memory space" 2601 "2601 System diagnostics: Adapter cannot be initialized" 2602 "2602 System diagnostics: Cable is interrupted (reaction according to 'ID 34027 BUS failure c..." 2603 "2603 System diagnostics: Data exchange mode is exited (e.g. after watchdog error; reaction a..." 2604 "2604 System diagnostics: Inadmissible field bus handshake code (e.g. SERVERERROR, SERVERWARN..." 2605 "2605 System diagnostics: PROFIBUS Initialization/ Error state" 2606 "2606 System diagnostics: PROFIBUS MSAC-C1 error (Master-Slave Acyclic Communication-Class1)" 2607 "2607 System diagnostics: PROFIBUS MSAC-C2 error (Master-Slave Acyclic Communication-Class2)" 2608 "2608 System diagnostics: PROFIBUS initialisation error" 2609 "2609 System diagnostics: PROFIBUS Warning – wrong parameter initialization" 2610 "2610 System diagnostics: PROFIBUS error bus configuration" 2611 "2611 System diagnostics: PROFIBUS error bus configuration" 2612 "2612 System diagnostics: PROFIBUS error bus configuration" 2613 "2613 System diagnostics: PROFIBUS error bus configuration" 2614 "2614 System diagnostics: PROFIBUS error bus configuration" 2615 "2615 System diagnostics: PROFIBUS error bus configuration" 2620 "2620 System diagnostics: Subscriber not connected with network" 2621 "2621 System diagnostics: Network error" 2622 "2622 System diagnostics: Transfer error/transmission error" 2623 "2623 System diagnostics: Adapter is constantly reconfigured" 2624 "2624 System diagnostics: ID34023=0, BUS subscriber address must be unequal to 0" 2625 "2625 System diagnostics: ARCNET telegram too long" 2626 "2626 System diagnostics: Node ID is already present" 2628 "2628 System diagnostics: Init. state error" 2640 "2640 LON failure" 2641 "2641 LON timeout IN" 2642 "2642 LON timeout OUT" 2643 "2643 LON timeout application" 2644 "2644 System diagnostics: Device reports within 2 s in the ramp up" 2645 "2645 System diagnostics: DPRAM writing error" 2660 "2660 System diagnostics: The required RAM memory for the system data is not present" 2661 "2661 System diagnostics: Unknown bus mode entry in 'ID34025 BUS mode'" 2663 "2663 System diagnostics: Interbus is inactive" 2664 "2664 System diagnostics: Interbus reset" 2665 "2665 System diagnostics: At least 20 invalid data cycles detected" 2680 "2680 System diagnostics: CAN AFP error during initialization" 2681 "2681 System diagnostics: Object Dictionary error" 2682 "2682 System diagnostics: Too much Receive PDOs and SDOs configured" 2683 "2683 System diagnostics: Software error (Reason could be false configuration data)" 2684 "2684 System diagnostics: Communication error" 2685 "2685 System diagnostics: Communication error" 2686 "2686 System diagnostics: AFP error" 2687 "2687 System diagnostics: Invalid Node address" 2688 "2688 System diagnostics: 'ID34025 Bus mode':AFP bit not valid" 2689 "2689 System diagnostics: Errors on configuring" 2690 "2690 System diagnostics: Error in Slave configuration (Data size in CCF element too big)" 2691 "2691 System diagnostics" 2692 "2692 System diagnostics: Software warning" 2693 "2693 System diagnostics: Slave Node State error" 2694 "2694 System diagnostics: Slave Node Guarding error" 2695 "2695 System diagnostics: Emergency received" 2696 "2696 System diagnostics: DSDO Router error" 2697 "2697 System diagnostics: Mandatory slave node missing" 2698 "2698 System diagnostics: SDO error during network configuration" 2699 "2699 System diagnostics: System error" 2721 "2721 System diagnostics: Slave defective or no longer on the bus" 2722 "2722 System diagnostics: Cable breakage" 2723 "2723 System Diagnostics" 2724 "2724 System diagnostics: Error during the initialisation for the EtherCAT option" 2725 "2725 System diagnostics" 2726 "2726 System diagnostics: Error in the EtherCAT master booting process" 2727 "2727 System diagnostics: Error EtherCAT configuration" 2728 "2728 System diagnostics: Error EtherCAT protocol during ID access" 2729 "2729 System diagnostics: Error EtherCAT service channel / mailbox" 2730 "2730 System diagnostics: Error EtherCAT datagram sending procedure, communication error" 2731 "2731 System diagnostics: Error EtherCAT sequence slave configuration" 2732 "2732 System diagnostics" 2741 "2741 Modbus configuration" 2742 "2742 MODBUS communication" 2743 "2743 MODBUS protocol" 2744 "2744 MODBUS command" 2760 "2760 System diagnostics: Missing DC bus voltage at state 'SWITCHED ON' or when switching to..." 2761 "2761 System diagnostics: Error when changing the operating mode" 2762 "2762 System diagnostics: Error in function 'Touch Probe'" 2763 "2763 System diagnostics: Error in scaling configuration" 2764 "2764 System diagnostics: Error in Brake function" 2816 "2816 PS option" 3072 "3072 Error option SERCOS" 3328 "3328 NC option error" 3584 "3584 Special SW msg: Fault overload protection connectbox (n)" 3585 "3585 FSE: CAN/config error during init (voltage limit / torque reduction limits)" 3586 "3586 FSE CAN: Error during initialization (config mode, index, signal, length, baud)" 3587 "3587 FSE CAN: Error during operation (setpoint telegram failure, checksum, counter)" 3588 "3588 Special SW msg: Frequency too low" 3589 "3589 Special SW msg: Frequency too high" 3590 "3590 Special SW msg: Voltage too low" 3591 "3591 Special SW msg: Voltage too high" 3592 "3592 Special SW msg: Fault voltage (switch on)" 3593 "3593 Special SW msg: Fault frequency (switch on)" 3594 "3594 Special SW msg: Warning string monitoring connectbox (n)..." 3595 "3595 Special SW msg: Fault init bus" 3596 "3596 Special SW msg: Fault check DC" 3597 "3597 Special SW msg: Fault check AC / DC" 3598 "3598 Special SW msg: See special descriptions corresponding to..." 3599 "3599 Special SW msg: See special descriptions corresponding to..." 3600 "3600 Special SW msg: See special descriptions corresponding to..." 3601 "3601 Special SW msg: See special descriptions corresponding to..." 3602 "3602 Special SW msg: See special descriptions corresponding to..." 3603 "3603 System diagnostics: AFP-PLC error" 3605 "3605 Safety - Invalid parameterisation" 3606 "3606 Safety - Error during operation" 3607 "3607 Safety - Internal system error" 3609 "3609 Safety - Faulty parameter transfer" 3610 "3610 Safety - Warning during operation" 3840 "3840 File access" 3841 "3841 System diagnostics: Internal communication: Error message returned from end device" 3842 "3842 System diagnostics: Internal communication: No heap memory could be addressed." 3843 "3843 System diagnostics: Internal communication: Source module does not exist (not logged in?)" 3844 "3844 System diagnostics: Internal communication: The addressed target does not exist" 3845 "3845 System diagnostics" 3846 "3846 System diagnostics: Internal communication: A module has logged on that already exists..." 3847 "3847 System diagnostics: Internal communication: The element code is unknown" 3848 "3848 System diagnostics: Internal communication: Too many modules have logged in or" 3849 "3849 System diagnostics: Internal communication: Protocol or command order is incorrect" 3850 "3850 System diagnostics: A bus connected to the internal communication is not in standby mod..." 3851 "3851 System diagnostics: An internal communication path has been occupied by a module by wri..." 3852 "3852 System diagnostics: An internal communication path specified by a module is not valid o..." 3853 "3853 System diagnostics: Router error in module setting" 3854 "3854 System diagnostics: Router memory overflow of the inernal buffer" 3855 "3855 System diagnostics: Router memory overflow at access to the internal database" 3860 "3860 ADB-File access" 3861 "3861 System start / update" 3862 "3862 System diagnostics: System exception, CPU error" 3863 "3863 System diagnostics: Router memory overflow internal buffer" 3864 "3864 Bus configuration" 3865 "3865 Software version option" 3867 "3867 System diagnostics: Error in updating device data record" 3868 "3868 System diagnostics: Error during initialisation of system" 3869 "3869 I/O Optional Card" 3871 "3871 System diagnostics: Communication" ;
VAL_ 645 AMK_ErrorInfo 0 "0 No diagnostic" 257 "257 System diagnostics: SBM withdrawal" 258 "258 Leave RF active" 259 "259 System diagnostics: SBM withdrawal" 514 "514 System diagnostics: Check parallel EEPROM on the control board" 515 "515 System diagnostics: Check parallel EEPROM on the control board" 516 "516 System diagnostics: Check AZ(X27)-AW(X57)-BUS" 517 "517 System diagnostics: Check AZ(X27)-AW(X57)-BUS" 518 "518 System diagnostics" 519 "519 System diagnostics: SEEP in the inverter cannot be addressed" 520 "520 System diagnostics: SEEP in the inverter cannot be addressed" 521 "521 System diagnostics" 770 "770 System diagnostics" 771 "771 System diagnostics: Check parallel EEPROM on the control board" 772 "772 System diagnostics: Check parallel EEPROM on the control board" 773 "773 System diagnostics: Inadmissible database order" 774 "774 System diagnostics" 775 "775 System diagnostics: ID not supported" 776 "776 System diagnostics: It was attempted to use a parameter set which was not reserved for..." 777 "777 System diagnostics: Check parallel EEPROM on the control board" 778 "778 System diagnostics: The attribute of the selected data block is wrong" 779 "779 System diagnostics: The maximum value of the last changed parameter was exceeded" 780 "780 System diagnostics: The minimum value of the last changed parameter was not reached" 781 "781 System diagnostics: It was attempted to write a list which can only be read" 783 "783 System diagnostics: Error at distributing parameters during internal system update" 1024 "1024 System diagnostics: System fault in the control board area" 1025 "1025 System diagnostics" 1026 "1026 System diagnostics: Error on writing the serial EEPROM" 1027 "1027 System diagnostics: Data error in the EPROM" 1028 "1028 System diagnostics: RAM memory error, is checked during system initialization" 1029 "1029 System diagnostics: Data error in the parallel EEPROM" 1030 "1030 System diagnostics: Error on writing the parallel EEPROM" 1031 "1031 System diagnostics: Control panel does not report on initialization" 1032 "1032 System diagnostics: Reception error from the serial interface 1" 1033 "1033 System diagnostics: Reception error from the serial interface 2" 1034 "1034 System diagnostics: Time level overflow" 1035 "1035 System diagnostics: Faulty system initialization, possible external fault" 1036 "1036 System diagnostics: Fault" 1037 "1037 System diagnostics: Fault" 1038 "1038 System diagnostics: Fault" 1039 "1039 System diagnostics: Faulty memory access of the processor. Software reset is triggered...." 1040 "1040 Tripzone" 1041 "1041 Overtemperature external component mains" 1042 "1042 Mains phase fault" 1043 "1043 Line Voltage Error" 1044 "1044 No SBM" 1045 "1045 Mains overvoltage" 1046 "1046 Mains undervoltage" 1047 "1047 Inhibit time for UE" 1048 "1048 UE switching frequency too high" 1049 "1049 DC bus" 1050 "1050 Phase error L1" 1051 "1051 Phase error L2" 1052 "1052 Phase error L3" 1053 "1053 Phase sequence L1/L2" 1054 "1054 Phase sequence L1/L3" 1055 "1055 Phase sequence L2/L3" 1056 "1056 Mains phase sequence L1, L2 , L3" 1057 "1057 Fault +12 V" 1058 "1058 Fault -12 V" 1059 "1059 DC bus overvoltage" 1060 "1060 Regeneration fault" 1061 "1061 Braking transistor fault" 1062 "1062 System diagnostics" 1063 "1063 System diagnostics" 1064 "1064 System diagnostics" 1065 "1065 System diagnostics: QUE missing on RF activation" 1066 "1066 System diagnostics" 1067 "1067 System diagnostics: Fault DC bus" 1068 "1068 System diagnostics" 1069 "1069 System diagnostics" 1070 "1070 System diagnostics: FL not possible (timeout 20 s)" 1071 "1071 System diagnostics: Brake acknowledgment does not correspond to the expected value" 1072 "1072 System diagnostics" 1073 "1073 Cooling Air Temperature Warning" 1074 "1074 External line component temperature warning" 1075 "1075 Power supply unit temperature warning" 1076 "1076 Feed / Regeneration temperature warning" 1077 "1077 Line Voltage warning" 1078 "1078 Line undervoltage warning" 1079 "1079 System diagnostics: All square wave encoder breakage messages are displayed only with a..." 1080 "1080 Encoder line break analysis on option card, input 1 slot 1" 1081 "1081 Encoder line break analysis on option card, input 2 slot 1" 1082 "1082 Encoder line break analysis on option card, input 3 slot 1" 1083 "1083 Encoder line break analysis on option card, input 4 slot 1" 1084 "1084 Encoder line break analysis on option card, input 1 slot 2" 1085 "1085 Encoder line break analysis on option card, input 2 slot 2" 1086 "1086 Encoder line break analysis on option card, input 3 slot 2" 1087 "1087 Encoder line break analysis on option card, input 4 slot 2" 1088 "1088 Encoder line break analysis on option card, input 1 slot 3" 1089 "1089 Encoder line break analysis on option card, input 2 slot 3" 1090 "1090 Encoder line break analysis on option card, input 3 slot 3" 1091 "1091 Encoder line break analysis on option card, input 4 slot 3" 1092 "1092 Encoder line break analysis on option card, input 1 slot 4" 1093 "1093 Encoder line break analysis on option card, input 2 slot 4" 1094 "1094 Encoder line break analysis on option card, input 3 slot 4" 1095 "1095 Encoder line break analysis on option card, input 4 slot 4" 1096 "1096 Short-circuit/overload of the outputs option card, slot 1 (e.g. AZ-EA8 or AZ-EA24)" 1097 "1097 Short-circuit / overload of the outputs option card, slot 2 (e.g. AZ-EA8 or AZ-EA24)" 1098 "1098 Short-circuit/overload of the outputs option card, slot 3 (e.g. AZ-EA8 or AZ-EA24)" 1099 "1099 Short-circuit/overload of the outputs option card, slot 4 (e.g. AZ-EA8 or AZ-EA24)" 1100 "1100 System diagnostics: Short-circuit / overload digital outputs" 1101 "1101 Logic voltage error" 1102 "1102 Line voltage limit" 1103 "1103 Field bus warning" 1104 "1104 No FL with RF active" 1105 "1105 Reserved" 1106 "1106 System diagnostic" 1107 "1107 System diagnostics: Short circuit DC bus voltage" 1108 "1108 System diagnostics: Main contactor" 1109 "1109 System diagnostics: Shifting of Y-point" 1110 "1110 Warning brake transistor" 1111 "1111 Warning external component" 1112 "1112 Overload error external component" 1115 "1115 Communication monitoring" 1281 "1281 System diagnostics" 1282 "1282 ID32777, ID111, ID32769" 1283 "1283 ID111, ID32769" 1284 "1284 ID111, ID32769" 1285 "1285 ID32772 wrong" 1286 "1286 ID82 or ID83 too large" 1287 "1287 ID32890: 1, 2, 5, 10" 1288 "1288 ID110, ID111, ID32769" 1289 "1289 ID83 too small" 1290 "1290 ID82 too large" 1291 "1291 ID32774 faulty" 1292 "1292 SEEP checksum" 1293 "1293 Boot strap EEPROM" 1294 "1294 EEPROM defective" 1295 "1295 ID100 / ID101" 1296 "1296 ID211 / ID209 / ID210" 1297 "1297 ID212 / ID209 / ID210" 1298 "1298 ID100 faulty" 1299 "1299 ID32775: even" 1300 "1300 Error in Temporary Parameters" 1301 "1301 ID32778 faulty" 1302 "1302 System diagnostics: Operating mode incomplete, see 'ID32800 AMK main operating mode' et..." 1303 "1303 System diagnostics: Operating mode incomplete, see 'ID32800 AMK main operating mode' et..." 1304 "1304 System diagnostics: Operating mode incomplete, see 'ID32800 AMK main operating mode' et..." 1305 "1305 System diagnostics: Operating mode incomplete, see 'ID32800 AMK main operating mode' et..." 1306 "1306 System diagnostics: Operating mode incomplete, see 'ID32800 AMK main operating mode' et..." 1307 "1307 System diagnostics: Position resolution not realizable" 1308 "1308 System diagnostics: Resolution of the “Speed source pulses” source not realizable" 1309 "1309 System diagnostics: Speed window larger than 107372.5 rpm" 1310 "1310 System diagnostics: “Pole factor POLF” calculation out of tolerance" 1311 "1311 System diagnostics: 4 GPZ calculation inconclusive" 1312 "1312 System diagnostics: Negated direction of rotation permissible only for A and I encoders" 1313 "1313 ID82 less then ID83" 1314 "1314 System diagnostics" 1315 "1315 System diagnostics: Resolver 0 point shift inadmissible" 1316 "1316 ID32769/ID100 too large" 1317 "1317 ID32770/ID110 too large" 1318 "1318 ID32774 faulty" 1319 "1319 System diagnostics: Configuration of “Strobe” binary input wrong" 1320 "1320 System diagnostics" 1321 "1321 System diagnostics" 1322 "1322 System diagnostics" 1323 "1323 ID32769 IM < ID111 IN" 1324 "1324 ID32772 nN too large" 1325 "1325 ID32772 P1 reference" 1326 "1326 System diagnostics: Source converter/on (UE) incorrect" 1327 "1327 ID104 kv factor" 1328 "1328 System diagnostics" 1329 "1329 ID111/ID110 > 80%" 1330 "1330 ID32772 > ID113" 1331 "1331 ID209 > ID113" 1332 "1332 ID210 > ID113" 1333 "1333 System diagnostics: 'ID32780 Acceleration ramp' resp. 'ID32781 Deceleration ramp' are t..." 1334 "1334 ID38 > ID113" 1335 "1335 |ID39| > ID113" 1336 "1336 ID32778 > ID113" 1337 "1337 ID32783 > ID113" 1338 "1338 ID157 > ID113" 1339 "1339 ID125 > ID113" 1340 "1340 ID124 > ID113" 1341 "1341 AW-Imax wrong (SEEP)" 1342 "1342 System diagnostics: External error" 1343 "1343 System diagnostics: Internal fault or component failure" 1344 "1344 System diagnostics: Internal fault or component failure (AWMON)" 1345 "1345 System diagnostics: Internal fault or component failure (wrong BAV order)" 1346 "1346 System diagnostics: Internal fault or component failure (Handshake BAV/DTH)" 1347 "1347 System diagnostics: Internal fault or component failure (Handshake BAV/PEEP)" 1348 "1348 System diagnostics: Internal fault or component failure (Handshake BAV/AWMON)" 1349 "1349 System diagnostics: Internal fault or component failure" 1350 "1350 AW not present" 1351 "1351 AW not active" 1352 "1352 Can be changed only offline" 1353 "1353 Parameter Set change wrong" 1354 "1354 Im < Im1" 1355 "1355 Date ID32785" 1356 "1356 Date ID32785, ID32786" 1357 "1357 AWNR ID32787, ID32789, ID32791, ID32793" 1358 "1358 Source ID32787, ID32789, ID32791, ID32793" 1359 "1359 ID32873, ID32968, ID32977" 1360 "1360 Opt.1 ID32846, ID32855, ID32864" 1361 "1361 Opt.2 ID32846, ID32855, ID32864" 1362 "1362 Opt.3 ID32846, ID32855, ID32864" 1363 "1363 Opt.4 ID32846, ID32855, ID32864" 1364 "1364 Definition of output bits" 1365 "1365 AWNR output bit" 1366 "1366 Definition of input bits" 1367 "1367 ID32883 Option place 1" 1368 "1368 ID32884 Option place 2" 1369 "1369 ID32885 Option place 3" 1370 "1370 ID32886 Option place 4" 1371 "1371 ID32799 Standard Periphery" 1372 "1372 Option place 1 card defect" 1373 "1373 Option place 2 card defect" 1374 "1374 Option place 3 card defect" 1375 "1375 Option place 4 card defect" 1376 "1376 ID32882 Option place 1" 1377 "1377 ID32882 Option place 2" 1378 "1378 ID32882 Option place 3" 1379 "1379 ID32882 Option place 4" 1380 "1380 ID110, ID111, ID32769" 1381 "1381 LIW source calculation" 1382 "1382 System diagnostics" 1383 "1383 2PI value wrong" 1384 "1384 2PI value calculation" 1385 "1385 ID116, ID32776 ratio" 1386 "1386 Output DA1 … DA4" 1387 "1387 ID32846 wrong" 1388 "1388 ID32855 wrong" 1389 "1389 ID32864 wrong" 1390 "1390 System diagnostics: NC/LR time not integral." 1391 "1391 ID32772 wrong" 1392 "1392 ID158, ID32771, ID32772" 1393 "1393 AW not AZ-compatible" 1394 "1394 ID32892: x times 2 to the power 16" 1395 "1395 No Main Operation Mode" 1396 "1396 Operation mode not defined" 1397 "1397 Operation mode not impl." 1398 "1398 Setpoint source undefined" 1399 "1399 Setpoint Source (SQ) is Not Admissible in this Operation Mode (BA)" 1400 "1400 Option Card for Setpoint Source (SQ)" 1401 "1401 MGQ not selected" 1402 "1402 Source of Torque Limit (MGQ) inadmissible for this Operation Mode (BA)" 1403 "1403 Source of Torque Limit (MGQ) not implemented" 1404 "1404 Source of Torque Limit (MGQ) AW-analog assigned" 1405 "1405 Speed Ramp (DZLRMP) function missing" 1406 "1406 Speed Filter (DZLFLT) function missing" 1407 "1407 Selected Operation Mode (BA) not configured" 1408 "1408 Change of Operation Mode (BA) not executable" 1409 "1409 Selected AW No. not active" 1410 "1410 Selected Parameter Set" 1411 "1411 Type of Position Controller is Inadmissible" 1412 "1412 Type of External Encoder inadmissible" 1413 "1413 Missing option card" 1414 "1414 Unknown AW type" 1415 "1415 Wrong AW type" 1416 "1416 Change of Operation Mode inadmissible" 1417 "1417 System diagnostics: The chosen operation mode cannot be mapped" 1418 "1418 System diagnostics: The chosen operation mode cannot be mapped" 1419 "1419 System diagnostics: Speed filter activated but parameterised wrongly" 1420 "1420 System diagnostics: Speed ramp is activated but the ramp parameters are asymmetric or f..." 1421 "1421 System diagnostics: 'ID82 Positive torque limit' faulty" 1422 "1422 System diagnostics: Internal lists of controller configuration do not fit the operation..." 1423 "1423 Inadmissible Setpoint Source" 1424 "1424 Inadmissible Setpoint Source" 1425 "1425 Polarity" 1426 "1426 ID121/122 wrong" 1427 "1427 ID44 inadmissible" 1428 "1428 ID86 inadmissible" 1429 "1429 ID160 inadmissible" 1430 "1430 Position scaling" 1431 "1431 Velocity scaling" 1432 "1432 Velocity scaling IPO" 1433 "1433 Torque scaling" 1434 "1434 Acceleration scaling" 1435 "1435 ID76 inadmissible" 1436 "1436 Decade switch" 1438 "1438 Band width barrier" 1440 "1440 Data record changed" 1441 "1441 Clock synchronization" 1442 "1442 SEEP configuration" 1443 "1443 Test generator" 1444 "1444 PWM frequency" 1445 "1445 Current controller" 1446 "1446 EF can not be activated" 1447 "1447 Motor encoder gear" 1448 "1448 ID113 > ID34153" 1451 "1451 Configuration temperature sensor" 1453 "1453 Feed forward control" 1454 "1454 Error initialisation angle observer" 1455 "1455 Plausibility I/O" 1456 "1456 Ratio ID33194 to ID33195 incorrect" 1457 "1457 ID38 less then ID39" 1537 "1537 System diagnostics: SEEP error in the inverter" 1538 "1538 System diagnostics: Taskmaster- / taskslave combination is inadmissible" 1539 "1539 SEEP 1st checksum" 1540 "1540 SEEP 2nd checksum" 1541 "1541 Commanded AW missing" 1542 "1542 System diagnostics" 1543 "1543 System diagnostics: The manufacturer information was not written correctly in the SEEP" 1544 "1544 ID32953 no adjustment permissible" 1545 "1545 System diagnostics: Errors occurred when writing the current encoder values in the SEEP..." 1546 "1546 System diagnostics: Fault counter is missing" 1547 "1547 System diagnostics" 1548 "1548 System diagnostics" 1549 "1549 System diagnostics: Clock master / clock slave combination not permissible" 1550 "1550 System diagnostics: Clock master / clock slave combination not permissible" 1551 "1551 Encoder track failed" 1552 "1552 Encoder adjustment abort" 1553 "1553 Encoder adjustment timeout" 1554 "1554 ID32776 Sinus Encoder Period is faulty" 1555 "1555 Reference pulse" 1556 "1556 Reference Pulse - Encoder Input" 1557 "1557 Turn axis" 1558 "1558 System diagnostics: Inverter transfers faulty encoder feedback values" 1794 "1794 System diagnostics: Interpolator" 1795 "1795 System diagnostics: Interpolator" 1796 "1796 System diagnostics: Interpolator" 1797 "1797 System diagnostics: Interpolator" 1798 "1798 System diagnostics: Interpolator" 1799 "1799 System diagnostics: Interpolator" 1800 "1800 System diagnostics: Interpolator" 1801 "1801 System diagnostics: Interpolator" 1802 "1802 System diagnostics: Interpolator" 1803 "1803 System diagnostics: Interpolator" 1804 "1804 System diagnostics: Check final value (target value)" 1805 "1805 System diagnostics: Interpolator standardisation: dxifaktor with remainder ID136, ID137..." 1806 "1806 System diagnostics: Interpolator standardisation: dxifaktor = 0: increase ID136, ID137,..." 1807 "1807 System diagnostics: Permissible time between KMD commanding and BAV operation mode mana..." 1808 "1808 System diagnostics: Operation mode management acknowledges error after commanding" 1809 "1809 System diagnostics: Inadmissible commanding code in KMD-SS, check interface" 1810 "1810 System diagnostics: Inadmissible commanding function in KMD-SS, check interface" 1811 "1811 System diagnostics: Inverter can no longer be addressed" 1812 "1812 System diagnostics: Inverter can no longer be addressed" 1813 "1813 KMD user error" 1814 "1814 System diagnostics: Inadmissible commanding operation mode selected, BA may be assigned..." 1815 "1815 Controller enable missing" 1816 "1816 Not homed" 1817 "1817 System diagnostics: Synchronous running source in synchronous running inadmissible" 1818 "1818 System diagnostics" 1819 "1819 System diagnostics: Inverter address calculation impossible, operation mode incomplete" 1820 "1820 System diagnostics: Ramp down error e.g. in lifting axis function, time according to ID..." 1821 "1821 System diagnostics: IPO cannot perform direction change" 1822 "1822 System diagnostics: IPO cannot be activated" 1823 "1823 System diagnostics: IPO cannot be activated" 1824 "1824 System diagnostics: Inadmissible KMD code in KMD-SS, inadmissible timing check interface" 1825 "1825 System diagnostics: SINCOS encoder, encoder does not report within 2 sec. through RS485-SS" 1826 "1826 System diagnostics: SINCOS encoder, checksum of the encoder acknowledgement does not ag..." 1827 "1827 System diagnostics: Invalid encoder type, the SINCOS encoder type is not permitted in t..." 1828 "1828 System diagnostics: This message can occur only in connection with an abort of drive fu..." 1829 "1829 System diagnostics: 'ID55 Closed loop polarity' and 'ID43 Velocity polarity' may be onl..." 1830 "1830 System diagnostics: “Flying saw” drive function, waiting distance (ID278) is greater th..." 1831 "1831 System diagnostics: SINCOS encoder, encoder reports error (error bit set)" 1832 "1832 System diagnostics: “Absolute positioning” drive function" 1833 "1833 System diagnostics: “Lifting axis” drive function, |nactual| ≥ |1.2 x nlimit|" 1834 "1834 System diagnostics: SINCOS encoders: The difference of the double sampling of the absol..." 1835 "1835 System diagnostics: Special lift function" 1836 "1836 System diagnostics: Special Lift function" 1837 "1837 System diagnostics: Special Lift function" 1838 "1838 System diagnostics: Special Lift function" 1839 "1839 System diagnostics: Special Lift function" 1840 "1840 System diagnostics: Special Lift function" 1841 "1841 System diagnostics" 1842 "1842 System diagnostics: Special lift function" 1843 "1843 System diagnostics" 2049 "2049 System diagnostics" 2050 "2050 System diagnostics: ID address or ID property is not known" 2051 "2051 System diagnostics: Waiting time after order to logical subscriber is exceeded" 2052 "2052 System diagnostics: The ID to be edited is not contained in the database of the system" 2053 "2053 System diagnostics: Error acknowledgement in commanding the database" 2054 "2054 System diagnostics: Error acknowledgement in commanding the monitor" 2055 "2055 System diagnostics: Error acknowledgement in commanding the serial EEPROM" 2056 "2056 System diagnostics: Error acknowledgement in commanding the operation mode management" 2057 "2057 System diagnostics: Error acknowledgement in commanding the drive commanding KMD" 2058 "2058 System diagnostics: Error in LT → KMD commanding inverter, LT → KMD - logical subscribe..." 2059 "2059 System diagnostics: Error in LT→ KMD commanding AW2" 2060 "2060 System diagnostics: Error in LT → KMD commanding AW3" 2061 "2061 System diagnostics: Error in LT → KMD commanding AW4" 2062 "2062 System diagnostics: Error in LT → KMD commanding AW5" 2063 "2063 System diagnostics: Error in LT → KMD commanding AW6" 2064 "2064 System diagnostics: Error in LT → MD commanding AW7" 2065 "2065 System diagnostics: Error in LT → KMD commanding AW8" 2066 "2066 System diagnostics: Error acknowledgement in commanding a drive control" 2067 "2067 System diagnostics: Error acknowledgement in commanding the diagnostics" 2068 "2068 System diagnostics: Error acknowledgement in commanding the display function" 2069 "2069 System diagnostics: Error acknowledgement in commanding the lift function" 2070 "2070 System diagnostics: LT-SBUS, inverter not present" 2071 "2071 System diagnostics: Failure in the s-bus hardware; re-boot system or check hardware" 2072 "2072 System diagnostics: S-bus software received faulty information from connected device, c..." 2073 "2073 System diagnostics" 2074 "2074 System diagnostics: Disturbance of scope function" 2305 "2305 Phase U Short Circuit" 2306 "2306 Phase V Short Circuit" 2307 "2307 Phase W Short Circuit" 2308 "2308 Supply +12 V" 2309 "2309 Supply" 2310 "2310 Encoder communication" 2311 "2311 Encoder signal" 2312 "2312 Output Terminal Ground Fault" 2313 "2313 Synchronous running error" 2314 "2314 Master Synchronous Telegram AW" 2315 "2315 AW controller clock error" 2316 "2316 Motor direction of rotation" 2317 "2317 External encoder direction of rotation" 2318 "2318 Control deviation" 2319 "2319 n > nmax" 2320 "2320 EF inactive" 2321 "2321 System diagnostics: IGBT monitoring in PWM device detects overcurrent" 2322 "2322 System diagnostics: Inverter RAM memory error" 2323 "2323 System diagnostics: VECON watchdog" 2324 "2324 System diagnostics: Hardware significance in the AW SEEP invalid (M8030, 2 or 3 current..." 2325 "2325 System diagnostics: Error (timeout 5s) current controller adjustment" 2326 "2326 System diagnostics" 2327 "2327 Plausibility of the External Encoder" 2328 "2328 System diagnostics: Missing option card e.g. in the KU. For instance, if an AMK-A encod..." 2329 "2329 System diagnostics: Commutation error in synchronous machine with AMK-T encoder (SINCOS..." 2330 "2330 System diagnostics" 2331 "2331 System diagnostics: Ramp down error" 2332 "2332 System diagnostics" 2333 "2333 Position growth too large" 2334 "2334 System diagnostics: Output terminal overcurrent" 2335 "2335 Error reference pulse" 2336 "2336 System diagnostics: Current setpoint at the analog input of the slave AW was too large...." 2337 "2337 No clock enable acknowledgement" 2338 "2338 Magnetizing timeout" 2339 "2339 Ramp down error" 2340 "2340 Communication on AW" 2342 "2342 System diagnostics" 2343 "2343 System diagnostics" 2344 "2344 Monitoring actual position" 2345 "2345 Inverter overload error" 2346 "2346 Converter temperature error" 2347 "2347 Motor temperature error" 2348 "2348 System diagnostics" 2349 "2349 Inverter overload warning" 2350 "2350 Device temperature warning" 2351 "2351 Motor temperature warning" 2352 "2352 Motor overload warning" 2353 "2353 Motor overload error" 2354 "2354 Handshake brake" 2356 "2356 Setpoint stop active" 2357 "2357 Device overload warning" 2358 "2358 Device overload error" 2359 "2359 Motor overload warning" 2360 "2360 Motor overload error" 2361 "2361 EF Logic" 2362 "2362 Error Commutation Motor" 2365 "2365 Error angle observer" 2366 "2366 Limit switch" 2367 "2367 Error Non Dual Use" 2560 "2560 System diagnostics: EtherCAT" 2561 "2561 System diagnostics: SERCOS" 2562 "2562 System diagnostics: MDT reception error in the Comm.phase 3 or 4 Device Description Cla..." 2563 "2563 System diagnostics: SERCOS Device Description Invalid communication phase Class Error D..." 2564 "2564 System diagnostics: SERCOS" 2565 "2565 System diagnostics: Phase switchback (not on phase 0)" 2566 "2566 System diagnostics: Phase switchover without ready message" 2569 "2569 System diagnostics: Memory error (allocating)" 2570 "2570 System diagnostics: Memory error (deallocating)" 2571 "2571 System diagnostics: Timeout during communication phases switch-over (AS-PL)" 2572 "2572 System diagnostics: SERCOS" 2573 "2573 System diagnostics: SERCOS" 2574 "2574 System diagnostics: SERCOS" 2575 "2575 System diagnostics: In Kx-SC2 modules: ext. 48 V power supply is not available or has b..." 2576 "2576 System diagnostics" 2577 "2577 System diagnostics: Allocation of the real time control or real time status bit" 2578 "2578 System diagnostics: Test function active message (continuous light, zero bit stream)" 2579 "2579 System diagnostics: Error on initialization of the SERCOS option card" 2581 "2581 System diagnostics: SERCOS master driver initialization" 2582 "2582 System diagnostics: SERCOS master driver initialization" 2583 "2583 System diagnostics: SERCOS master configuration 'ID34036 CCB File'" 2584 "2584 System diagnostics: SERCOS master phase switchover" 2585 "2585 System diagnostics: SERCOS master time slot calculation" 2586 "2586 System diagnostics: SERCOS master service channel" 2587 "2587 System diagnostics: SERCOS master incorrect data in the service channel" 2588 "2588 System diagnostics: SERCOS master error in command execution" 2589 "2589 System diagnostics: SERCOS master has detected ring interruption" 2590 "2590 System diagnostics: SERCOS master has detected AT failure" 2591 "2591 System diagnostics: SERCOS master software error" 2592 "2592 System diagnostics: SERCOS master has detected MST failure" 2593 "2593 System diagnostics: SERCOS master real time error" 2594 "2594 System diagnostics: SERCOS master software error" 2595 "2595 System diagnostics: SERCOS" 2596 "2596 System diagnostics: SERCOS master has received the “error” acknowledgment to a command" 2597 "2597 System diagnostics: SERCOS master has received an error message from a remote node" 2598 "2598 System diagnostics: SERCOS has indicated a bad signal quality on the OWG receiver (exce..." 2599 "2599 System diagnostics: Error while activating the advanced operating mode" 2600 "2600 System diagnostics: Error memory space" 2601 "2601 System diagnostics: Adapter cannot be initialized" 2602 "2602 System diagnostics: Cable is interrupted (reaction according to 'ID 34027 BUS failure c..." 2603 "2603 System diagnostics: Data exchange mode is exited (e.g. after watchdog error; reaction a..." 2604 "2604 System diagnostics: Inadmissible field bus handshake code (e.g. SERVERERROR, SERVERWARN..." 2605 "2605 System diagnostics: PROFIBUS Initialization/ Error state" 2606 "2606 System diagnostics: PROFIBUS MSAC-C1 error (Master-Slave Acyclic Communication-Class1)" 2607 "2607 System diagnostics: PROFIBUS MSAC-C2 error (Master-Slave Acyclic Communication-Class2)" 2608 "2608 System diagnostics: PROFIBUS initialisation error" 2609 "2609 System diagnostics: PROFIBUS Warning – wrong parameter initialization" 2610 "2610 System diagnostics: PROFIBUS error bus configuration" 2611 "2611 System diagnostics: PROFIBUS error bus configuration" 2612 "2612 System diagnostics: PROFIBUS error bus configuration" 2613 "2613 System diagnostics: PROFIBUS error bus configuration" 2614 "2614 System diagnostics: PROFIBUS error bus configuration" 2615 "2615 System diagnostics: PROFIBUS error bus configuration" 2620 "2620 System diagnostics: Subscriber not connected with network" 2621 "2621 System diagnostics: Network error" 2622 "2622 System diagnostics: Transfer error/transmission error" 2623 "2623 System diagnostics: Adapter is constantly reconfigured" 2624 "2624 System diagnostics: ID34023=0, BUS subscriber address must be unequal to 0" 2625 "2625 System diagnostics: ARCNET telegram too long" 2626 "2626 System diagnostics: Node ID is already present" 2628 "2628 System diagnostics: Init. state error" 2640 "2640 LON failure" 2641 "2641 LON timeout IN" 2642 "2642 LON timeout OUT" 2643 "2643 LON timeout application" 2644 "2644 System diagnostics: Device reports within 2 s in the ramp up" 2645 "2645 System diagnostics: DPRAM writing error" 2660 "2660 System diagnostics: The required RAM memory for the system data is not present" 2661 "2661 System diagnostics: Unknown bus mode entry in 'ID34025 BUS mode'" 2663 "2663 System diagnostics: Interbus is inactive" 2664 "2664 System diagnostics: Interbus reset" 2665 "2665 System diagnostics: At least 20 invalid data cycles detected" 2680 "2680 System diagnostics: CAN AFP error during initialization" 2681 "2681 System diagnostics: Object Dictionary error" 2682 "2682 System diagnostics: Too much Receive PDOs and SDOs configured" 2683 "2683 System diagnostics: Software error (Reason could be false configuration data)" 2684 "2684 System diagnostics: Communication error" 2685 "2685 System diagnostics: Communication error" 2686 "2686 System diagnostics: AFP error" 2687 "2687 System diagnostics: Invalid Node address" 2688 "2688 System diagnostics: 'ID34025 Bus mode':AFP bit not valid" 2689 "2689 System diagnostics: Errors on configuring" 2690 "2690 System diagnostics: Error in Slave configuration (Data size in CCF element too big)" 2691 "2691 System diagnostics" 2692 "2692 System diagnostics: Software warning" 2693 "2693 System diagnostics: Slave Node State error" 2694 "2694 System diagnostics: Slave Node Guarding error" 2695 "2695 System diagnostics: Emergency received" 2696 "2696 System diagnostics: DSDO Router error" 2697 "2697 System diagnostics: Mandatory slave node missing" 2698 "2698 System diagnostics: SDO error during network configuration" 2699 "2699 System diagnostics: System error" 2721 "2721 System diagnostics: Slave defective or no longer on the bus" 2722 "2722 System diagnostics: Cable breakage" 2723 "2723 System Diagnostics" 2724 "2724 System diagnostics: Error during the initialisation for the EtherCAT option" 2725 "2725 System diagnostics" 2726 "2726 System diagnostics: Error in the EtherCAT master booting process" 2727 "2727 System diagnostics: Error EtherCAT configuration" 2728 "2728 System diagnostics: Error EtherCAT protocol during ID access" 2729 "2729 System diagnostics: Error EtherCAT service channel / mailbox" 2730 "2730 System diagnostics: Error EtherCAT datagram sending procedure, communication error" 2731 "2731 System diagnostics: Error EtherCAT sequence slave configuration" 2732 "2732 System diagnostics" 2741 "2741 Modbus configuration" 2742 "2742 MODBUS communication" 2743 "2743 MODBUS protocol" 2744 "2744 MODBUS command" 2760 "2760 System diagnostics: Missing DC bus voltage at state 'SWITCHED ON' or when switching to..." 2761 "2761 System diagnostics: Error when changing the operating mode" 2762 "2762 System diagnostics: Error in function 'Touch Probe'" 2763 "2763 System diagnostics: Error in scaling configuration" 2764 "2764 System diagnostics: Error in Brake function" 2816 "2816 PS option" 3072 "3072 Error option SERCOS" 3328 "3328 NC option error" 3584 "3584 Special SW msg: Fault overload protection connectbox (n)" 3585 "3585 FSE: CAN/config error during init (voltage limit / torque reduction limits)" 3586 "3586 FSE CAN: Error during initialization (config mode, index, signal, length, baud)" 3587 "3587 FSE CAN: Error during operation (setpoint telegram failure, checksum, counter)" 3588 "3588 Special SW msg: Frequency too low" 3589 "3589 Special SW msg: Frequency too high" 3590 "3590 Special SW msg: Voltage too low" 3591 "3591 Special SW msg: Voltage too high" 3592 "3592 Special SW msg: Fault voltage (switch on)" 3593 "3593 Special SW msg: Fault frequency (switch on)" 3594 "3594 Special SW msg: Warning string monitoring connectbox (n)..." 3595 "3595 Special SW msg: Fault init bus" 3596 "3596 Special SW msg: Fault check DC" 3597 "3597 Special SW msg: Fault check AC / DC" 3598 "3598 Special SW msg: See special descriptions corresponding to..." 3599 "3599 Special SW msg: See special descriptions corresponding to..." 3600 "3600 Special SW msg: See special descriptions corresponding to..." 3601 "3601 Special SW msg: See special descriptions corresponding to..." 3602 "3602 Special SW msg: See special descriptions corresponding to..." 3603 "3603 System diagnostics: AFP-PLC error" 3605 "3605 Safety - Invalid parameterisation" 3606 "3606 Safety - Error during operation" 3607 "3607 Safety - Internal system error" 3609 "3609 Safety - Faulty parameter transfer" 3610 "3610 Safety - Warning during operation" 3840 "3840 File access" 3841 "3841 System diagnostics: Internal communication: Error message returned from end device" 3842 "3842 System diagnostics: Internal communication: No heap memory could be addressed." 3843 "3843 System diagnostics: Internal communication: Source module does not exist (not logged in?)" 3844 "3844 System diagnostics: Internal communication: The addressed target does not exist" 3845 "3845 System diagnostics" 3846 "3846 System diagnostics: Internal communication: A module has logged on that already exists..." 3847 "3847 System diagnostics: Internal communication: The element code is unknown" 3848 "3848 System diagnostics: Internal communication: Too many modules have logged in or" 3849 "3849 System diagnostics: Internal communication: Protocol or command order is incorrect" 3850 "3850 System diagnostics: A bus connected to the internal communication is not in standby mod..." 3851 "3851 System diagnostics: An internal communication path has been occupied by a module by wri..." 3852 "3852 System diagnostics: An internal communication path specified by a module is not valid o..." 3853 "3853 System diagnostics: Router error in module setting" 3854 "3854 System diagnostics: Router memory overflow of the inernal buffer" 3855 "3855 System diagnostics: Router memory overflow at access to the internal database" 3860 "3860 ADB-File access" 3861 "3861 System start / update" 3862 "3862 System diagnostics: System exception, CPU error" 3863 "3863 System diagnostics: Router memory overflow internal buffer" 3864 "3864 Bus configuration" 3865 "3865 Software version option" 3867 "3867 System diagnostics: Error in updating device data record" 3868 "3868 System diagnostics: Error during initialisation of system" 3869 "3869 I/O Optional Card" 3871 "3871 System diagnostics: Communication" ;
VAL_ 647 AMK_ErrorInfo 0 "0 No diagnostic" 257 "257 System diagnostics: SBM withdrawal" 258 "258 Leave RF active" 259 "259 System diagnostics: SBM withdrawal" 514 "514 System diagnostics: Check parallel EEPROM on the control board" 515 "515 System diagnostics: Check parallel EEPROM on the control board" 516 "516 System diagnostics: Check AZ(X27)-AW(X57)-BUS" 517 "517 System diagnostics: Check AZ(X27)-AW(X57)-BUS" 518 "518 System diagnostics" 519 "519 System diagnostics: SEEP in the inverter cannot be addressed" 520 "520 System diagnostics: SEEP in the inverter cannot be addressed" 521 "521 System diagnostics" 770 "770 System diagnostics" 771 "771 System diagnostics: Check parallel EEPROM on the control board" 772 "772 System diagnostics: Check parallel EEPROM on the control board" 773 "773 System diagnostics: Inadmissible database order" 774 "774 System diagnostics" 775 "775 System diagnostics: ID not supported" 776 "776 System diagnostics: It was attempted to use a parameter set which was not reserved for..." 777 "777 System diagnostics: Check parallel EEPROM on the control board" 778 "778 System diagnostics: The attribute of the selected data block is wrong" 779 "779 System diagnostics: The maximum value of the last changed parameter was exceeded" 780 "780 System diagnostics: The minimum value of the last changed parameter was not reached" 781 "781 System diagnostics: It was attempted to write a list which can only be read" 783 "783 System diagnostics: Error at distributing parameters during internal system update" 1024 "1024 System diagnostics: System fault in the control board area" 1025 "1025 System diagnostics" 1026 "1026 System diagnostics: Error on writing the serial EEPROM" 1027 "1027 System diagnostics: Data error in the EPROM" 1028 "1028 System diagnostics: RAM memory error, is checked during system initialization" 1029 "1029 System diagnostics: Data error in the parallel EEPROM" 1030 "1030 System diagnostics: Error on writing the parallel EEPROM" 1031 "1031 System diagnostics: Control panel does not report on initialization" 1032 "1032 System diagnostics: Reception error from the serial interface 1" 1033 "1033 System diagnostics: Reception error from the serial interface 2" 1034 "1034 System diagnostics: Time level overflow" 1035 "1035 System diagnostics: Faulty system initialization, possible external fault" 1036 "1036 System diagnostics: Fault" 1037 "1037 System diagnostics: Fault" 1038 "1038 System diagnostics: Fault" 1039 "1039 System diagnostics: Faulty memory access of the processor. Software reset is triggered...." 1040 "1040 Tripzone" 1041 "1041 Overtemperature external component mains" 1042 "1042 Mains phase fault" 1043 "1043 Line Voltage Error" 1044 "1044 No SBM" 1045 "1045 Mains overvoltage" 1046 "1046 Mains undervoltage" 1047 "1047 Inhibit time for UE" 1048 "1048 UE switching frequency too high" 1049 "1049 DC bus" 1050 "1050 Phase error L1" 1051 "1051 Phase error L2" 1052 "1052 Phase error L3" 1053 "1053 Phase sequence L1/L2" 1054 "1054 Phase sequence L1/L3" 1055 "1055 Phase sequence L2/L3" 1056 "1056 Mains phase sequence L1, L2 , L3" 1057 "1057 Fault +12 V" 1058 "1058 Fault -12 V" 1059 "1059 DC bus overvoltage" 1060 "1060 Regeneration fault" 1061 "1061 Braking transistor fault" 1062 "1062 System diagnostics" 1063 "1063 System diagnostics" 1064 "1064 System diagnostics" 1065 "1065 System diagnostics: QUE missing on RF activation" 1066 "1066 System diagnostics" 1067 "1067 System diagnostics: Fault DC bus" 1068 "1068 System diagnostics" 1069 "1069 System diagnostics" 1070 "1070 System diagnostics: FL not possible (timeout 20 s)" 1071 "1071 System diagnostics: Brake acknowledgment does not correspond to the expected value" 1072 "1072 System diagnostics" 1073 "1073 Cooling Air Temperature Warning" 1074 "1074 External line component temperature warning" 1075 "1075 Power supply unit temperature warning" 1076 "1076 Feed / Regeneration temperature warning" 1077 "1077 Line Voltage warning" 1078 "1078 Line undervoltage warning" 1079 "1079 System diagnostics: All square wave encoder breakage messages are displayed only with a..." 1080 "1080 Encoder line break analysis on option card, input 1 slot 1" 1081 "1081 Encoder line break analysis on option card, input 2 slot 1" 1082 "1082 Encoder line break analysis on option card, input 3 slot 1" 1083 "1083 Encoder line break analysis on option card, input 4 slot 1" 1084 "1084 Encoder line break analysis on option card, input 1 slot 2" 1085 "1085 Encoder line break analysis on option card, input 2 slot 2" 1086 "1086 Encoder line break analysis on option card, input 3 slot 2" 1087 "1087 Encoder line break analysis on option card, input 4 slot 2" 1088 "1088 Encoder line break analysis on option card, input 1 slot 3" 1089 "1089 Encoder line break analysis on option card, input 2 slot 3" 1090 "1090 Encoder line break analysis on option card, input 3 slot 3" 1091 "1091 Encoder line break analysis on option card, input 4 slot 3" 1092 "1092 Encoder line break analysis on option card, input 1 slot 4" 1093 "1093 Encoder line break analysis on option card, input 2 slot 4" 1094 "1094 Encoder line break analysis on option card, input 3 slot 4" 1095 "1095 Encoder line break analysis on option card, input 4 slot 4" 1096 "1096 Short-circuit/overload of the outputs option card, slot 1 (e.g. AZ-EA8 or AZ-EA24)" 1097 "1097 Short-circuit / overload of the outputs option card, slot 2 (e.g. AZ-EA8 or AZ-EA24)" 1098 "1098 Short-circuit/overload of the outputs option card, slot 3 (e.g. AZ-EA8 or AZ-EA24)" 1099 "1099 Short-circuit/overload of the outputs option card, slot 4 (e.g. AZ-EA8 or AZ-EA24)" 1100 "1100 System diagnostics: Short-circuit / overload digital outputs" 1101 "1101 Logic voltage error" 1102 "1102 Line voltage limit" 1103 "1103 Field bus warning" 1104 "1104 No FL with RF active" 1105 "1105 Reserved" 1106 "1106 System diagnostic" 1107 "1107 System diagnostics: Short circuit DC bus voltage" 1108 "1108 System diagnostics: Main contactor" 1109 "1109 System diagnostics: Shifting of Y-point" 1110 "1110 Warning brake transistor" 1111 "1111 Warning external component" 1112 "1112 Overload error external component" 1115 "1115 Communication monitoring" 1281 "1281 System diagnostics" 1282 "1282 ID32777, ID111, ID32769" 1283 "1283 ID111, ID32769" 1284 "1284 ID111, ID32769" 1285 "1285 ID32772 wrong" 1286 "1286 ID82 or ID83 too large" 1287 "1287 ID32890: 1, 2, 5, 10" 1288 "1288 ID110, ID111, ID32769" 1289 "1289 ID83 too small" 1290 "1290 ID82 too large" 1291 "1291 ID32774 faulty" 1292 "1292 SEEP checksum" 1293 "1293 Boot strap EEPROM" 1294 "1294 EEPROM defective" 1295 "1295 ID100 / ID101" 1296 "1296 ID211 / ID209 / ID210" 1297 "1297 ID212 / ID209 / ID210" 1298 "1298 ID100 faulty" 1299 "1299 ID32775: even" 1300 "1300 Error in Temporary Parameters" 1301 "1301 ID32778 faulty" 1302 "1302 System diagnostics: Operating mode incomplete, see 'ID32800 AMK main operating mode' et..." 1303 "1303 System diagnostics: Operating mode incomplete, see 'ID32800 AMK main operating mode' et..." 1304 "1304 System diagnostics: Operating mode incomplete, see 'ID32800 AMK main operating mode' et..." 1305 "1305 System diagnostics: Operating mode incomplete, see 'ID32800 AMK main operating mode' et..." 1306 "1306 System diagnostics: Operating mode incomplete, see 'ID32800 AMK main operating mode' et..." 1307 "1307 System diagnostics: Position resolution not realizable" 1308 "1308 System diagnostics: Resolution of the “Speed source pulses” source not realizable" 1309 "1309 System diagnostics: Speed window larger than 107372.5 rpm" 1310 "1310 System diagnostics: “Pole factor POLF” calculation out of tolerance" 1311 "1311 System diagnostics: 4 GPZ calculation inconclusive" 1312 "1312 System diagnostics: Negated direction of rotation permissible only for A and I encoders" 1313 "1313 ID82 less then ID83" 1314 "1314 System diagnostics" 1315 "1315 System diagnostics: Resolver 0 point shift inadmissible" 1316 "1316 ID32769/ID100 too large" 1317 "1317 ID32770/ID110 too large" 1318 "1318 ID32774 faulty" 1319 "1319 System diagnostics: Configuration of “Strobe” binary input wrong" 1320 "1320 System diagnostics" 1321 "1321 System diagnostics" 1322 "1322 System diagnostics" 1323 "1323 ID32769 IM < ID111 IN" 1324 "1324 ID32772 nN too large" 1325 "1325 ID32772 P1 reference" 1326 "1326 System diagnostics: Source converter/on (UE) incorrect" 1327 "1327 ID104 kv factor" 1328 "1328 System diagnostics" 1329 "1329 ID111/ID110 > 80%" 1330 "1330 ID32772 > ID113" 1331 "1331 ID209 > ID113" 1332 "1332 ID210 > ID113" 1333 "1333 System diagnostics: 'ID32780 Acceleration ramp' resp. 'ID32781 Deceleration ramp' are t..." 1334 "1334 ID38 > ID113" 1335 "1335 |ID39| > ID113" 1336 "1336 ID32778 > ID113" 1337 "1337 ID32783 > ID113" 1338 "1338 ID157 > ID113" 1339 "1339 ID125 > ID113" 1340 "1340 ID124 > ID113" 1341 "1341 AW-Imax wrong (SEEP)" 1342 "1342 System diagnostics: External error" 1343 "1343 System diagnostics: Internal fault or component failure" 1344 "1344 System diagnostics: Internal fault or component failure (AWMON)" 1345 "1345 System diagnostics: Internal fault or component failure (wrong BAV order)" 1346 "1346 System diagnostics: Internal fault or component failure (Handshake BAV/DTH)" 1347 "1347 System diagnostics: Internal fault or component failure (Handshake BAV/PEEP)" 1348 "1348 System diagnostics: Internal fault or component failure (Handshake BAV/AWMON)" 1349 "1349 System diagnostics: Internal fault or component failure" 1350 "1350 AW not present" 1351 "1351 AW not active" 1352 "1352 Can be changed only offline" 1353 "1353 Parameter Set change wrong" 1354 "1354 Im < Im1" 1355 "1355 Date ID32785" 1356 "1356 Date ID32785, ID32786" 1357 "1357 AWNR ID32787, ID32789, ID32791, ID32793" 1358 "1358 Source ID32787, ID32789, ID32791, ID32793" 1359 "1359 ID32873, ID32968, ID32977" 1360 "1360 Opt.1 ID32846, ID32855, ID32864" 1361 "1361 Opt.2 ID32846, ID32855, ID32864" 1362 "1362 Opt.3 ID32846, ID32855, ID32864" 1363 "1363 Opt.4 ID32846, ID32855, ID32864" 1364 "1364 Definition of output bits" 1365 "1365 AWNR output bit" 1366 "1366 Definition of input bits" 1367 "1367 ID32883 Option place 1" 1368 "1368 ID32884 Option place 2" 1369 "1369 ID32885 Option place 3" 1370 "1370 ID32886 Option place 4" 1371 "1371 ID32799 Standard Periphery" 1372 "1372 Option place 1 card defect" 1373 "1373 Option place 2 card defect" 1374 "1374 Option place 3 card defect" 1375 "1375 Option place 4 card defect" 1376 "1376 ID32882 Option place 1" 1377 "1377 ID32882 Option place 2" 1378 "1378 ID32882 Option place 3" 1379 "1379 ID32882 Option place 4" 1380 "1380 ID110, ID111, ID32769" 1381 "1381 LIW source calculation" 1382 "1382 System diagnostics" 1383 "1383 2PI value wrong" 1384 "1384 2PI value calculation" 1385 "1385 ID116, ID32776 ratio" 1386 "1386 Output DA1 … DA4" 1387 "1387 ID32846 wrong" 1388 "1388 ID32855 wrong" 1389 "1389 ID32864 wrong" 1390 "1390 System diagnostics: NC/LR time not integral." 1391 "1391 ID32772 wrong" 1392 "1392 ID158, ID32771, ID32772" 1393 "1393 AW not AZ-compatible" 1394 "1394 ID32892: x times 2 to the power 16" 1395 "1395 No Main Operation Mode" 1396 "1396 Operation mode not defined" 1397 "1397 Operation mode not impl." 1398 "1398 Setpoint source undefined" 1399 "1399 Setpoint Source (SQ) is Not Admissible in this Operation Mode (BA)" 1400 "1400 Option Card for Setpoint Source (SQ)" 1401 "1401 MGQ not selected" 1402 "1402 Source of Torque Limit (MGQ) inadmissible for this Operation Mode (BA)" 1403 "1403 Source of Torque Limit (MGQ) not implemented" 1404 "1404 Source of Torque Limit (MGQ) AW-analog assigned" 1405 "1405 Speed Ramp (DZLRMP) function missing" 1406 "1406 Speed Filter (DZLFLT) function missing" 1407 "1407 Selected Operation Mode (BA) not configured" 1408 "1408 Change of Operation Mode (BA) not executable" 1409 "1409 Selected AW No. not active" 1410 "1410 Selected Parameter Set" 1411 "1411 Type of Position Controller is Inadmissible" 1412 "1412 Type of External Encoder inadmissible" 1413 "1413 Missing option card" 1414 "1414 Unknown AW type" 1415 "1415 Wrong AW type" 1416 "1416 Change of Operation Mode inadmissible" 1417 "1417 System diagnostics: The chosen operation mode cannot be mapped" 1418 "1418 System diagnostics: The chosen operation mode cannot be mapped" 1419 "1419 System diagnostics: Speed filter activated but parameterised wrongly" 1420 "1420 System diagnostics: Speed ramp is activated but the ramp parameters are asymmetric or f..." 1421 "1421 System diagnostics: 'ID82 Positive torque limit' faulty" 1422 "1422 System diagnostics: Internal lists of controller configuration do not fit the operation..." 1423 "1423 Inadmissible Setpoint Source" 1424 "1424 Inadmissible Setpoint Source" 1425 "1425 Polarity" 1426 "1426 ID121/122 wrong" 1427 "1427 ID44 inadmissible" 1428 "1428 ID86 inadmissible" 1429 "1429 ID160 inadmissible" 1430 "1430 Position scaling" 1431 "1431 Velocity scaling" 1432 "1432 Velocity scaling IPO" 1433 "1433 Torque scaling" 1434 "1434 Acceleration scaling" 1435 "1435 ID76 inadmissible" 1436 "1436 Decade switch" 1438 "1438 Band width barrier" 1440 "1440 Data record changed" 1441 "1441 Clock synchronization" 1442 "1442 SEEP configuration" 1443 "1443 Test generator" 1444 "1444 PWM frequency" 1445 "1445 Current controller" 1446 "1446 EF can not be activated" 1447 "1447 Motor encoder gear" 1448 "1448 ID113 > ID34153" 1451 "1451 Configuration temperature sensor" 1453 "1453 Feed forward control" 1454 "1454 Error initialisation angle observer" 1455 "1455 Plausibility I/O" 1456 "1456 Ratio ID33194 to ID33195 incorrect" 1457 "1457 ID38 less then ID39" 1537 "1537 System diagnostics: SEEP error in the inverter" 1538 "1538 System diagnostics: Taskmaster- / taskslave combination is inadmissible" 1539 "1539 SEEP 1st checksum" 1540 "1540 SEEP 2nd checksum" 1541 "1541 Commanded AW missing" 1542 "1542 System diagnostics" 1543 "1543 System diagnostics: The manufacturer information was not written correctly in the SEEP" 1544 "1544 ID32953 no adjustment permissible" 1545 "1545 System diagnostics: Errors occurred when writing the current encoder values in the SEEP..." 1546 "1546 System diagnostics: Fault counter is missing" 1547 "1547 System diagnostics" 1548 "1548 System diagnostics" 1549 "1549 System diagnostics: Clock master / clock slave combination not permissible" 1550 "1550 System diagnostics: Clock master / clock slave combination not permissible" 1551 "1551 Encoder track failed" 1552 "1552 Encoder adjustment abort" 1553 "1553 Encoder adjustment timeout" 1554 "1554 ID32776 Sinus Encoder Period is faulty" 1555 "1555 Reference pulse" 1556 "1556 Reference Pulse - Encoder Input" 1557 "1557 Turn axis" 1558 "1558 System diagnostics: Inverter transfers faulty encoder feedback values" 1794 "1794 System diagnostics: Interpolator" 1795 "1795 System diagnostics: Interpolator" 1796 "1796 System diagnostics: Interpolator" 1797 "1797 System diagnostics: Interpolator" 1798 "1798 System diagnostics: Interpolator" 1799 "1799 System diagnostics: Interpolator" 1800 "1800 System diagnostics: Interpolator" 1801 "1801 System diagnostics: Interpolator" 1802 "1802 System diagnostics: Interpolator" 1803 "1803 System diagnostics: Interpolator" 1804 "1804 System diagnostics: Check final value (target value)" 1805 "1805 System diagnostics: Interpolator standardisation: dxifaktor with remainder ID136, ID137..." 1806 "1806 System diagnostics: Interpolator standardisation: dxifaktor = 0: increase ID136, ID137,..." 1807 "1807 System diagnostics: Permissible time between KMD commanding and BAV operation mode mana..." 1808 "1808 System diagnostics: Operation mode management acknowledges error after commanding" 1809 "1809 System diagnostics: Inadmissible commanding code in KMD-SS, check interface" 1810 "1810 System diagnostics: Inadmissible commanding function in KMD-SS, check interface" 1811 "1811 System diagnostics: Inverter can no longer be addressed" 1812 "1812 System diagnostics: Inverter can no longer be addressed" 1813 "1813 KMD user error" 1814 "1814 System diagnostics: Inadmissible commanding operation mode selected, BA may be assigned..." 1815 "1815 Controller enable missing" 1816 "1816 Not homed" 1817 "1817 System diagnostics: Synchronous running source in synchronous running inadmissible" 1818 "1818 System diagnostics" 1819 "1819 System diagnostics: Inverter address calculation impossible, operation mode incomplete" 1820 "1820 System diagnostics: Ramp down error e.g. in lifting axis function, time according to ID..." 1821 "1821 System diagnostics: IPO cannot perform direction change" 1822 "1822 System diagnostics: IPO cannot be activated" 1823 "1823 System diagnostics: IPO cannot be activated" 1824 "1824 System diagnostics: Inadmissible KMD code in KMD-SS, inadmissible timing check interface" 1825 "1825 System diagnostics: SINCOS encoder, encoder does not report within 2 sec. through RS485-SS" 1826 "1826 System diagnostics: SINCOS encoder, checksum of the encoder acknowledgement does not ag..." 1827 "1827 System diagnostics: Invalid encoder type, the SINCOS encoder type is not permitted in t..." 1828 "1828 System diagnostics: This message can occur only in connection with an abort of drive fu..." 1829 "1829 System diagnostics: 'ID55 Closed loop polarity' and 'ID43 Velocity polarity' may be onl..." 1830 "1830 System diagnostics: “Flying saw” drive function, waiting distance (ID278) is greater th..." 1831 "1831 System diagnostics: SINCOS encoder, encoder reports error (error bit set)" 1832 "1832 System diagnostics: “Absolute positioning” drive function" 1833 "1833 System diagnostics: “Lifting axis” drive function, |nactual| ≥ |1.2 x nlimit|" 1834 "1834 System diagnostics: SINCOS encoders: The difference of the double sampling of the absol..." 1835 "1835 System diagnostics: Special lift function" 1836 "1836 System diagnostics: Special Lift function" 1837 "1837 System diagnostics: Special Lift function" 1838 "1838 System diagnostics: Special Lift function" 1839 "1839 System diagnostics: Special Lift function" 1840 "1840 System diagnostics: Special Lift function" 1841 "1841 System diagnostics" 1842 "1842 System diagnostics: Special lift function" 1843 "1843 System diagnostics" 2049 "2049 System diagnostics" 2050 "2050 System diagnostics: ID address or ID property is not known" 2051 "2051 System diagnostics: Waiting time after order to logical subscriber is exceeded" 2052 "2052 System diagnostics: The ID to be edited is not contained in the database of the system" 2053 "2053 System diagnostics: Error acknowledgement in commanding the database" 2054 "2054 System diagnostics: Error acknowledgement in commanding the monitor" 2055 "2055 System diagnostics: Error acknowledgement in commanding the serial EEPROM" 2056 "2056 System diagnostics: Error acknowledgement in commanding the operation mode management" 2057 "2057 System diagnostics: Error acknowledgement in commanding the drive commanding KMD" 2058 "2058 System diagnostics: Error in LT → KMD commanding inverter, LT → KMD - logical subscribe..." 2059 "2059 System diagnostics: Error in LT→ KMD commanding AW2" 2060 "2060 System diagnostics: Error in LT → KMD commanding AW3" 2061 "2061 System diagnostics: Error in LT → KMD commanding AW4" 2062 "2062 System diagnostics: Error in LT → KMD commanding AW5" 2063 "2063 System diagnostics: Error in LT → KMD commanding AW6" 2064 "2064 System diagnostics: Error in LT → MD commanding AW7" 2065 "2065 System diagnostics: Error in LT → KMD commanding AW8" 2066 "2066 System diagnostics: Error acknowledgement in commanding a drive control" 2067 "2067 System diagnostics: Error acknowledgement in commanding the diagnostics" 2068 "2068 System diagnostics: Error acknowledgement in commanding the display function" 2069 "2069 System diagnostics: Error acknowledgement in commanding the lift function" 2070 "2070 System diagnostics: LT-SBUS, inverter not present" 2071 "2071 System diagnostics: Failure in the s-bus hardware; re-boot system or check hardware" 2072 "2072 System diagnostics: S-bus software received faulty information from connected device, c..." 2073 "2073 System diagnostics" 2074 "2074 System diagnostics: Disturbance of scope function" 2305 "2305 Phase U Short Circuit" 2306 "2306 Phase V Short Circuit" 2307 "2307 Phase W Short Circuit" 2308 "2308 Supply +12 V" 2309 "2309 Supply" 2310 "2310 Encoder communication" 2311 "2311 Encoder signal" 2312 "2312 Output Terminal Ground Fault" 2313 "2313 Synchronous running error" 2314 "2314 Master Synchronous Telegram AW" 2315 "2315 AW controller clock error" 2316 "2316 Motor direction of rotation" 2317 "2317 External encoder direction of rotation" 2318 "2318 Control deviation" 2319 "2319 n > nmax" 2320 "2320 EF inactive" 2321 "2321 System diagnostics: IGBT monitoring in PWM device detects overcurrent" 2322 "2322 System diagnostics: Inverter RAM memory error" 2323 "2323 System diagnostics: VECON watchdog" 2324 "2324 System diagnostics: Hardware significance in the AW SEEP invalid (M8030, 2 or 3 current..." 2325 "2325 System diagnostics: Error (timeout 5s) current controller adjustment" 2326 "2326 System diagnostics" 2327 "2327 Plausibility of the External Encoder" 2328 "2328 System diagnostics: Missing option card e.g. in the KU. For instance, if an AMK-A encod..." 2329 "2329 System diagnostics: Commutation error in synchronous machine with AMK-T encoder (SINCOS..." 2330 "2330 System diagnostics" 2331 "2331 System diagnostics: Ramp down error" 2332 "2332 System diagnostics" 2333 "2333 Position growth too large" 2334 "2334 System diagnostics: Output terminal overcurrent" 2335 "2335 Error reference pulse" 2336 "2336 System diagnostics: Current setpoint at the analog input of the slave AW was too large...." 2337 "2337 No clock enable acknowledgement" 2338 "2338 Magnetizing timeout" 2339 "2339 Ramp down error" 2340 "2340 Communication on AW" 2342 "2342 System diagnostics" 2343 "2343 System diagnostics" 2344 "2344 Monitoring actual position" 2345 "2345 Inverter overload error" 2346 "2346 Converter temperature error" 2347 "2347 Motor temperature error" 2348 "2348 System diagnostics" 2349 "2349 Inverter overload warning" 2350 "2350 Device temperature warning" 2351 "2351 Motor temperature warning" 2352 "2352 Motor overload warning" 2353 "2353 Motor overload error" 2354 "2354 Handshake brake" 2356 "2356 Setpoint stop active" 2357 "2357 Device overload warning" 2358 "2358 Device overload error" 2359 "2359 Motor overload warning" 2360 "2360 Motor overload error" 2361 "2361 EF Logic" 2362 "2362 Error Commutation Motor" 2365 "2365 Error angle observer" 2366 "2366 Limit switch" 2367 "2367 Error Non Dual Use" 2560 "2560 System diagnostics: EtherCAT" 2561 "2561 System diagnostics: SERCOS" 2562 "2562 System diagnostics: MDT reception error in the Comm.phase 3 or 4 Device Description Cla..." 2563 "2563 System diagnostics: SERCOS Device Description Invalid communication phase Class Error D..." 2564 "2564 System diagnostics: SERCOS" 2565 "2565 System diagnostics: Phase switchback (not on phase 0)" 2566 "2566 System diagnostics: Phase switchover without ready message" 2569 "2569 System diagnostics: Memory error (allocating)" 2570 "2570 System diagnostics: Memory error (deallocating)" 2571 "2571 System diagnostics: Timeout during communication phases switch-over (AS-PL)" 2572 "2572 System diagnostics: SERCOS" 2573 "2573 System diagnostics: SERCOS" 2574 "2574 System diagnostics: SERCOS" 2575 "2575 System diagnostics: In Kx-SC2 modules: ext. 48 V power supply is not available or has b..." 2576 "2576 System diagnostics" 2577 "2577 System diagnostics: Allocation of the real time control or real time status bit" 2578 "2578 System diagnostics: Test function active message (continuous light, zero bit stream)" 2579 "2579 System diagnostics: Error on initialization of the SERCOS option card" 2581 "2581 System diagnostics: SERCOS master driver initialization" 2582 "2582 System diagnostics: SERCOS master driver initialization" 2583 "2583 System diagnostics: SERCOS master configuration 'ID34036 CCB File'" 2584 "2584 System diagnostics: SERCOS master phase switchover" 2585 "2585 System diagnostics: SERCOS master time slot calculation" 2586 "2586 System diagnostics: SERCOS master service channel" 2587 "2587 System diagnostics: SERCOS master incorrect data in the service channel" 2588 "2588 System diagnostics: SERCOS master error in command execution" 2589 "2589 System diagnostics: SERCOS master has detected ring interruption" 2590 "2590 System diagnostics: SERCOS master has detected AT failure" 2591 "2591 System diagnostics: SERCOS master software error" 2592 "2592 System diagnostics: SERCOS master has detected MST failure" 2593 "2593 System diagnostics: SERCOS master real time error" 2594 "2594 System diagnostics: SERCOS master software error" 2595 "2595 System diagnostics: SERCOS" 2596 "2596 System diagnostics: SERCOS master has received the “error” acknowledgment to a command" 2597 "2597 System diagnostics: SERCOS master has received an error message from a remote node" 2598 "2598 System diagnostics: SERCOS has indicated a bad signal quality on the OWG receiver (exce..." 2599 "2599 System diagnostics: Error while activating the advanced operating mode" 2600 "2600 System diagnostics: Error memory space" 2601 "2601 System diagnostics: Adapter cannot be initialized" 2602 "2602 System diagnostics: Cable is interrupted (reaction according to 'ID 34027 BUS failure c..." 2603 "2603 System diagnostics: Data exchange mode is exited (e.g. after watchdog error; reaction a..." 2604 "2604 System diagnostics: Inadmissible field bus handshake code (e.g. SERVERERROR, SERVERWARN..." 2605 "2605 System diagnostics: PROFIBUS Initialization/ Error state" 2606 "2606 System diagnostics: PROFIBUS MSAC-C1 error (Master-Slave Acyclic Communication-Class1)" 2607 "2607 System diagnostics: PROFIBUS MSAC-C2 error (Master-Slave Acyclic Communication-Class2)" 2608 "2608 System diagnostics: PROFIBUS initialisation error" 2609 "2609 System diagnostics: PROFIBUS Warning – wrong parameter initialization" 2610 "2610 System diagnostics: PROFIBUS error bus configuration" 2611 "2611 System diagnostics: PROFIBUS error bus configuration" 2612 "2612 System diagnostics: PROFIBUS error bus configuration" 2613 "2613 System diagnostics: PROFIBUS error bus configuration" 2614 "2614 System diagnostics: PROFIBUS error bus configuration" 2615 "2615 System diagnostics: PROFIBUS error bus configuration" 2620 "2620 System diagnostics: Subscriber not connected with network" 2621 "2621 System diagnostics: Network error" 2622 "2622 System diagnostics: Transfer error/transmission error" 2623 "2623 System diagnostics: Adapter is constantly reconfigured" 2624 "2624 System diagnostics: ID34023=0, BUS subscriber address must be unequal to 0" 2625 "2625 System diagnostics: ARCNET telegram too long" 2626 "2626 System diagnostics: Node ID is already present" 2628 "2628 System diagnostics: Init. state error" 2640 "2640 LON failure" 2641 "2641 LON timeout IN" 2642 "2642 LON timeout OUT" 2643 "2643 LON timeout application" 2644 "2644 System diagnostics: Device reports within 2 s in the ramp up" 2645 "2645 System diagnostics: DPRAM writing error" 2660 "2660 System diagnostics: The required RAM memory for the system data is not present" 2661 "2661 System diagnostics: Unknown bus mode entry in 'ID34025 BUS mode'" 2663 "2663 System diagnostics: Interbus is inactive" 2664 "2664 System diagnostics: Interbus reset" 2665 "2665 System diagnostics: At least 20 invalid data cycles detected" 2680 "2680 System diagnostics: CAN AFP error during initialization" 2681 "2681 System diagnostics: Object Dictionary error" 2682 "2682 System diagnostics: Too much Receive PDOs and SDOs configured" 2683 "2683 System diagnostics: Software error (Reason could be false configuration data)" 2684 "2684 System diagnostics: Communication error" 2685 "2685 System diagnostics: Communication error" 2686 "2686 System diagnostics: AFP error" 2687 "2687 System diagnostics: Invalid Node address" 2688 "2688 System diagnostics: 'ID34025 Bus mode':AFP bit not valid" 2689 "2689 System diagnostics: Errors on configuring" 2690 "2690 System diagnostics: Error in Slave configuration (Data size in CCF element too big)" 2691 "2691 System diagnostics" 2692 "2692 System diagnostics: Software warning" 2693 "2693 System diagnostics: Slave Node State error" 2694 "2694 System diagnostics: Slave Node Guarding error" 2695 "2695 System diagnostics: Emergency received" 2696 "2696 System diagnostics: DSDO Router error" 2697 "2697 System diagnostics: Mandatory slave node missing" 2698 "2698 System diagnostics: SDO error during network configuration" 2699 "2699 System diagnostics: System error" 2721 "2721 System diagnostics: Slave defective or no longer on the bus" 2722 "2722 System diagnostics: Cable breakage" 2723 "2723 System Diagnostics" 2724 "2724 System diagnostics: Error during the initialisation for the EtherCAT option" 2725 "2725 System diagnostics" 2726 "2726 System diagnostics: Error in the EtherCAT master booting process" 2727 "2727 System diagnostics: Error EtherCAT configuration" 2728 "2728 System diagnostics: Error EtherCAT protocol during ID access" 2729 "2729 System diagnostics: Error EtherCAT service channel / mailbox" 2730 "2730 System diagnostics: Error EtherCAT datagram sending procedure, communication error" 2731 "2731 System diagnostics: Error EtherCAT sequence slave configuration" 2732 "2732 System diagnostics" 2741 "2741 Modbus configuration" 2742 "2742 MODBUS communication" 2743 "2743 MODBUS protocol" 2744 "2744 MODBUS command" 2760 "2760 System diagnostics: Missing DC bus voltage at state 'SWITCHED ON' or when switching to..." 2761 "2761 System diagnostics: Error when changing the operating mode" 2762 "2762 System diagnostics: Error in function 'Touch Probe'" 2763 "2763 System diagnostics: Error in scaling configuration" 2764 "2764 System diagnostics: Error in Brake function" 2816 "2816 PS option" 3072 "3072 Error option SERCOS" 3328 "3328 NC option error" 3584 "3584 Special SW msg: Fault overload protection connectbox (n)" 3585 "3585 FSE: CAN/config error during init (voltage limit / torque reduction limits)" 3586 "3586 FSE CAN: Error during initialization (config mode, index, signal, length, baud)" 3587 "3587 FSE CAN: Error during operation (setpoint telegram failure, checksum, counter)" 3588 "3588 Special SW msg: Frequency too low" 3589 "3589 Special SW msg: Frequency too high" 3590 "3590 Special SW msg: Voltage too low" 3591 "3591 Special SW msg: Voltage too high" 3592 "3592 Special SW msg: Fault voltage (switch on)" 3593 "3593 Special SW msg: Fault frequency (switch on)" 3594 "3594 Special SW msg: Warning string monitoring connectbox (n)..." 3595 "3595 Special SW msg: Fault init bus" 3596 "3596 Special SW msg: Fault check DC" 3597 "3597 Special SW msg: Fault check AC / DC" 3598 "3598 Special SW msg: See special descriptions corresponding to..." 3599 "3599 Special SW msg: See special descriptions corresponding to..." 3600 "3600 Special SW msg: See special descriptions corresponding to..." 3601 "3601 Special SW msg: See special descriptions corresponding to..." 3602 "3602 Special SW msg: See special descriptions corresponding to..." 3603 "3603 System diagnostics: AFP-PLC error" 3605 "3605 Safety - Invalid parameterisation" 3606 "3606 Safety - Error during operation" 3607 "3607 Safety - Internal system error" 3609 "3609 Safety - Faulty parameter transfer" 3610 "3610 Safety - Warning during operation" 3840 "3840 File access" 3841 "3841 System diagnostics: Internal communication: Error message returned from end device" 3842 "3842 System diagnostics: Internal communication: No heap memory could be addressed." 3843 "3843 System diagnostics: Internal communication: Source module does not exist (not logged in?)" 3844 "3844 System diagnostics: Internal communication: The addressed target does not exist" 3845 "3845 System diagnostics" 3846 "3846 System diagnostics: Internal communication: A module has logged on that already exists..." 3847 "3847 System diagnostics: Internal communication: The element code is unknown" 3848 "3848 System diagnostics: Internal communication: Too many modules have logged in or" 3849 "3849 System diagnostics: Internal communication: Protocol or command order is incorrect" 3850 "3850 System diagnostics: A bus connected to the internal communication is not in standby mod..." 3851 "3851 System diagnostics: An internal communication path has been occupied by a module by wri..." 3852 "3852 System diagnostics: An internal communication path specified by a module is not valid o..." 3853 "3853 System diagnostics: Router error in module setting" 3854 "3854 System diagnostics: Router memory overflow of the inernal buffer" 3855 "3855 System diagnostics: Router memory overflow at access to the internal database" 3860 "3860 ADB-File access" 3861 "3861 System start / update" 3862 "3862 System diagnostics: System exception, CPU error" 3863 "3863 System diagnostics: Router memory overflow internal buffer" 3864 "3864 Bus configuration" 3865 "3865 Software version option" 3867 "3867 System diagnostics: Error in updating device data record" 3868 "3868 System diagnostics: Error during initialisation of system" 3869 "3869 I/O Optional Card" 3871 "3871 System diagnostics: Communication" ;
VAL_ 649 AMK_ErrorInfo 0 "0 No diagnostic" 257 "257 System diagnostics: SBM withdrawal" 258 "258 Leave RF active" 259 "259 System diagnostics: SBM withdrawal" 514 "514 System diagnostics: Check parallel EEPROM on the control board" 515 "515 System diagnostics: Check parallel EEPROM on the control board" 516 "516 System diagnostics: Check AZ(X27)-AW(X57)-BUS" 517 "517 System diagnostics: Check AZ(X27)-AW(X57)-BUS" 518 "518 System diagnostics" 519 "519 System diagnostics: SEEP in the inverter cannot be addressed" 520 "520 System diagnostics: SEEP in the inverter cannot be addressed" 521 "521 System diagnostics" 770 "770 System diagnostics" 771 "771 System diagnostics: Check parallel EEPROM on the control board" 772 "772 System diagnostics: Check parallel EEPROM on the control board" 773 "773 System diagnostics: Inadmissible database order" 774 "774 System diagnostics" 775 "775 System diagnostics: ID not supported" 776 "776 System diagnostics: It was attempted to use a parameter set which was not reserved for..." 777 "777 System diagnostics: Check parallel EEPROM on the control board" 778 "778 System diagnostics: The attribute of the selected data block is wrong" 779 "779 System diagnostics: The maximum value of the last changed parameter was exceeded" 780 "780 System diagnostics: The minimum value of the last changed parameter was not reached" 781 "781 System diagnostics: It was attempted to write a list which can only be read" 783 "783 System diagnostics: Error at distributing parameters during internal system update" 1024 "1024 System diagnostics: System fault in the control board area" 1025 "1025 System diagnostics" 1026 "1026 System diagnostics: Error on writing the serial EEPROM" 1027 "1027 System diagnostics: Data error in the EPROM" 1028 "1028 System diagnostics: RAM memory error, is checked during system initialization" 1029 "1029 System diagnostics: Data error in the parallel EEPROM" 1030 "1030 System diagnostics: Error on writing the parallel EEPROM" 1031 "1031 System diagnostics: Control panel does not report on initialization" 1032 "1032 System diagnostics: Reception error from the serial interface 1" 1033 "1033 System diagnostics: Reception error from the serial interface 2" 1034 "1034 System diagnostics: Time level overflow" 1035 "1035 System diagnostics: Faulty system initialization, possible external fault" 1036 "1036 System diagnostics: Fault" 1037 "1037 System diagnostics: Fault" 1038 "1038 System diagnostics: Fault" 1039 "1039 System diagnostics: Faulty memory access of the processor. Software reset is triggered...." 1040 "1040 Tripzone" 1041 "1041 Overtemperature external component mains" 1042 "1042 Mains phase fault" 1043 "1043 Line Voltage Error" 1044 "1044 No SBM" 1045 "1045 Mains overvoltage" 1046 "1046 Mains undervoltage" 1047 "1047 Inhibit time for UE" 1048 "1048 UE switching frequency too high" 1049 "1049 DC bus" 1050 "1050 Phase error L1" 1051 "1051 Phase error L2" 1052 "1052 Phase error L3" 1053 "1053 Phase sequence L1/L2" 1054 "1054 Phase sequence L1/L3" 1055 "1055 Phase sequence L2/L3" 1056 "1056 Mains phase sequence L1, L2 , L3" 1057 "1057 Fault +12 V" 1058 "1058 Fault -12 V" 1059 "1059 DC bus overvoltage" 1060 "1060 Regeneration fault" 1061 "1061 Braking transistor fault" 1062 "1062 System diagnostics" 1063 "1063 System diagnostics" 1064 "1064 System diagnostics" 1065 "1065 System diagnostics: QUE missing on RF activation" 1066 "1066 System diagnostics" 1067 "1067 System diagnostics: Fault DC bus" 1068 "1068 System diagnostics" 1069 "1069 System diagnostics" 1070 "1070 System diagnostics: FL not possible (timeout 20 s)" 1071 "1071 System diagnostics: Brake acknowledgment does not correspond to the expected value" 1072 "1072 System diagnostics" 1073 "1073 Cooling Air Temperature Warning" 1074 "1074 External line component temperature warning" 1075 "1075 Power supply unit temperature warning" 1076 "1076 Feed / Regeneration temperature warning" 1077 "1077 Line Voltage warning" 1078 "1078 Line undervoltage warning" 1079 "1079 System diagnostics: All square wave encoder breakage messages are displayed only with a..." 1080 "1080 Encoder line break analysis on option card, input 1 slot 1" 1081 "1081 Encoder line break analysis on option card, input 2 slot 1" 1082 "1082 Encoder line break analysis on option card, input 3 slot 1" 1083 "1083 Encoder line break analysis on option card, input 4 slot 1" 1084 "1084 Encoder line break analysis on option card, input 1 slot 2" 1085 "1085 Encoder line break analysis on option card, input 2 slot 2" 1086 "1086 Encoder line break analysis on option card, input 3 slot 2" 1087 "1087 Encoder line break analysis on option card, input 4 slot 2" 1088 "1088 Encoder line break analysis on option card, input 1 slot 3" 1089 "1089 Encoder line break analysis on option card, input 2 slot 3" 1090 "1090 Encoder line break analysis on option card, input 3 slot 3" 1091 "1091 Encoder line break analysis on option card, input 4 slot 3" 1092 "1092 Encoder line break analysis on option card, input 1 slot 4" 1093 "1093 Encoder line break analysis on option card, input 2 slot 4" 1094 "1094 Encoder line break analysis on option card, input 3 slot 4" 1095 "1095 Encoder line break analysis on option card, input 4 slot 4" 1096 "1096 Short-circuit/overload of the outputs option card, slot 1 (e.g. AZ-EA8 or AZ-EA24)" 1097 "1097 Short-circuit / overload of the outputs option card, slot 2 (e.g. AZ-EA8 or AZ-EA24)" 1098 "1098 Short-circuit/overload of the outputs option card, slot 3 (e.g. AZ-EA8 or AZ-EA24)" 1099 "1099 Short-circuit/overload of the outputs option card, slot 4 (e.g. AZ-EA8 or AZ-EA24)" 1100 "1100 System diagnostics: Short-circuit / overload digital outputs" 1101 "1101 Logic voltage error" 1102 "1102 Line voltage limit" 1103 "1103 Field bus warning" 1104 "1104 No FL with RF active" 1105 "1105 Reserved" 1106 "1106 System diagnostic" 1107 "1107 System diagnostics: Short circuit DC bus voltage" 1108 "1108 System diagnostics: Main contactor" 1109 "1109 System diagnostics: Shifting of Y-point" 1110 "1110 Warning brake transistor" 1111 "1111 Warning external component" 1112 "1112 Overload error external component" 1115 "1115 Communication monitoring" 1281 "1281 System diagnostics" 1282 "1282 ID32777, ID111, ID32769" 1283 "1283 ID111, ID32769" 1284 "1284 ID111, ID32769" 1285 "1285 ID32772 wrong" 1286 "1286 ID82 or ID83 too large" 1287 "1287 ID32890: 1, 2, 5, 10" 1288 "1288 ID110, ID111, ID32769" 1289 "1289 ID83 too small" 1290 "1290 ID82 too large" 1291 "1291 ID32774 faulty" 1292 "1292 SEEP checksum" 1293 "1293 Boot strap EEPROM" 1294 "1294 EEPROM defective" 1295 "1295 ID100 / ID101" 1296 "1296 ID211 / ID209 / ID210" 1297 "1297 ID212 / ID209 / ID210" 1298 "1298 ID100 faulty" 1299 "1299 ID32775: even" 1300 "1300 Error in Temporary Parameters" 1301 "1301 ID32778 faulty" 1302 "1302 System diagnostics: Operating mode incomplete, see 'ID32800 AMK main operating mode' et..." 1303 "1303 System diagnostics: Operating mode incomplete, see 'ID32800 AMK main operating mode' et..." 1304 "1304 System diagnostics: Operating mode incomplete, see 'ID32800 AMK main operating mode' et..." 1305 "1305 System diagnostics: Operating mode incomplete, see 'ID32800 AMK main operating mode' et..." 1306 "1306 System diagnostics: Operating mode incomplete, see 'ID32800 AMK main operating mode' et..." 1307 "1307 System diagnostics: Position resolution not realizable" 1308 "1308 System diagnostics: Resolution of the “Speed source pulses” source not realizable" 1309 "1309 System diagnostics: Speed window larger than 107372.5 rpm" 1310 "1310 System diagnostics: “Pole factor POLF” calculation out of tolerance" 1311 "1311 System diagnostics: 4 GPZ calculation inconclusive" 1312 "1312 System diagnostics: Negated direction of rotation permissible only for A and I encoders" 1313 "1313 ID82 less then ID83" 1314 "1314 System diagnostics" 1315 "1315 System diagnostics: Resolver 0 point shift inadmissible" 1316 "1316 ID32769/ID100 too large" 1317 "1317 ID32770/ID110 too large" 1318 "1318 ID32774 faulty" 1319 "1319 System diagnostics: Configuration of “Strobe” binary input wrong" 1320 "1320 System diagnostics" 1321 "1321 System diagnostics" 1322 "1322 System diagnostics" 1323 "1323 ID32769 IM < ID111 IN" 1324 "1324 ID32772 nN too large" 1325 "1325 ID32772 P1 reference" 1326 "1326 System diagnostics: Source converter/on (UE) incorrect" 1327 "1327 ID104 kv factor" 1328 "1328 System diagnostics" 1329 "1329 ID111/ID110 > 80%" 1330 "1330 ID32772 > ID113" 1331 "1331 ID209 > ID113" 1332 "1332 ID210 > ID113" 1333 "1333 System diagnostics: 'ID32780 Acceleration ramp' resp. 'ID32781 Deceleration ramp' are t..." 1334 "1334 ID38 > ID113" 1335 "1335 |ID39| > ID113" 1336 "1336 ID32778 > ID113" 1337 "1337 ID32783 > ID113" 1338 "1338 ID157 > ID113" 1339 "1339 ID125 > ID113" 1340 "1340 ID124 > ID113" 1341 "1341 AW-Imax wrong (SEEP)" 1342 "1342 System diagnostics: External error" 1343 "1343 System diagnostics: Internal fault or component failure" 1344 "1344 System diagnostics: Internal fault or component failure (AWMON)" 1345 "1345 System diagnostics: Internal fault or component failure (wrong BAV order)" 1346 "1346 System diagnostics: Internal fault or component failure (Handshake BAV/DTH)" 1347 "1347 System diagnostics: Internal fault or component failure (Handshake BAV/PEEP)" 1348 "1348 System diagnostics: Internal fault or component failure (Handshake BAV/AWMON)" 1349 "1349 System diagnostics: Internal fault or component failure" 1350 "1350 AW not present" 1351 "1351 AW not active" 1352 "1352 Can be changed only offline" 1353 "1353 Parameter Set change wrong" 1354 "1354 Im < Im1" 1355 "1355 Date ID32785" 1356 "1356 Date ID32785, ID32786" 1357 "1357 AWNR ID32787, ID32789, ID32791, ID32793" 1358 "1358 Source ID32787, ID32789, ID32791, ID32793" 1359 "1359 ID32873, ID32968, ID32977" 1360 "1360 Opt.1 ID32846, ID32855, ID32864" 1361 "1361 Opt.2 ID32846, ID32855, ID32864" 1362 "1362 Opt.3 ID32846, ID32855, ID32864" 1363 "1363 Opt.4 ID32846, ID32855, ID32864" 1364 "1364 Definition of output bits" 1365 "1365 AWNR output bit" 1366 "1366 Definition of input bits" 1367 "1367 ID32883 Option place 1" 1368 "1368 ID32884 Option place 2" 1369 "1369 ID32885 Option place 3" 1370 "1370 ID32886 Option place 4" 1371 "1371 ID32799 Standard Periphery" 1372 "1372 Option place 1 card defect" 1373 "1373 Option place 2 card defect" 1374 "1374 Option place 3 card defect" 1375 "1375 Option place 4 card defect" 1376 "1376 ID32882 Option place 1" 1377 "1377 ID32882 Option place 2" 1378 "1378 ID32882 Option place 3" 1379 "1379 ID32882 Option place 4" 1380 "1380 ID110, ID111, ID32769" 1381 "1381 LIW source calculation" 1382 "1382 System diagnostics" 1383 "1383 2PI value wrong" 1384 "1384 2PI value calculation" 1385 "1385 ID116, ID32776 ratio" 1386 "1386 Output DA1 … DA4" 1387 "1387 ID32846 wrong" 1388 "1388 ID32855 wrong" 1389 "1389 ID32864 wrong" 1390 "1390 System diagnostics: NC/LR time not integral." 1391 "1391 ID32772 wrong" 1392 "1392 ID158, ID32771, ID32772" 1393 "1393 AW not AZ-compatible" 1394 "1394 ID32892: x times 2 to the power 16" 1395 "1395 No Main Operation Mode" 1396 "1396 Operation mode not defined" 1397 "1397 Operation mode not impl." 1398 "1398 Setpoint source undefined" 1399 "1399 Setpoint Source (SQ) is Not Admissible in this Operation Mode (BA)" 1400 "1400 Option Card for Setpoint Source (SQ)" 1401 "1401 MGQ not selected" 1402 "1402 Source of Torque Limit (MGQ) inadmissible for this Operation Mode (BA)" 1403 "1403 Source of Torque Limit (MGQ) not implemented" 1404 "1404 Source of Torque Limit (MGQ) AW-analog assigned" 1405 "1405 Speed Ramp (DZLRMP) function missing" 1406 "1406 Speed Filter (DZLFLT) function missing" 1407 "1407 Selected Operation Mode (BA) not configured" 1408 "1408 Change of Operation Mode (BA) not executable" 1409 "1409 Selected AW No. not active" 1410 "1410 Selected Parameter Set" 1411 "1411 Type of Position Controller is Inadmissible" 1412 "1412 Type of External Encoder inadmissible" 1413 "1413 Missing option card" 1414 "1414 Unknown AW type" 1415 "1415 Wrong AW type" 1416 "1416 Change of Operation Mode inadmissible" 1417 "1417 System diagnostics: The chosen operation mode cannot be mapped" 1418 "1418 System diagnostics: The chosen operation mode cannot be mapped" 1419 "1419 System diagnostics: Speed filter activated but parameterised wrongly" 1420 "1420 System diagnostics: Speed ramp is activated but the ramp parameters are asymmetric or f..." 1421 "1421 System diagnostics: 'ID82 Positive torque limit' faulty" 1422 "1422 System diagnostics: Internal lists of controller configuration do not fit the operation..." 1423 "1423 Inadmissible Setpoint Source" 1424 "1424 Inadmissible Setpoint Source" 1425 "1425 Polarity" 1426 "1426 ID121/122 wrong" 1427 "1427 ID44 inadmissible" 1428 "1428 ID86 inadmissible" 1429 "1429 ID160 inadmissible" 1430 "1430 Position scaling" 1431 "1431 Velocity scaling" 1432 "1432 Velocity scaling IPO" 1433 "1433 Torque scaling" 1434 "1434 Acceleration scaling" 1435 "1435 ID76 inadmissible" 1436 "1436 Decade switch" 1438 "1438 Band width barrier" 1440 "1440 Data record changed" 1441 "1441 Clock synchronization" 1442 "1442 SEEP configuration" 1443 "1443 Test generator" 1444 "1444 PWM frequency" 1445 "1445 Current controller" 1446 "1446 EF can not be activated" 1447 "1447 Motor encoder gear" 1448 "1448 ID113 > ID34153" 1451 "1451 Configuration temperature sensor" 1453 "1453 Feed forward control" 1454 "1454 Error initialisation angle observer" 1455 "1455 Plausibility I/O" 1456 "1456 Ratio ID33194 to ID33195 incorrect" 1457 "1457 ID38 less then ID39" 1537 "1537 System diagnostics: SEEP error in the inverter" 1538 "1538 System diagnostics: Taskmaster- / taskslave combination is inadmissible" 1539 "1539 SEEP 1st checksum" 1540 "1540 SEEP 2nd checksum" 1541 "1541 Commanded AW missing" 1542 "1542 System diagnostics" 1543 "1543 System diagnostics: The manufacturer information was not written correctly in the SEEP" 1544 "1544 ID32953 no adjustment permissible" 1545 "1545 System diagnostics: Errors occurred when writing the current encoder values in the SEEP..." 1546 "1546 System diagnostics: Fault counter is missing" 1547 "1547 System diagnostics" 1548 "1548 System diagnostics" 1549 "1549 System diagnostics: Clock master / clock slave combination not permissible" 1550 "1550 System diagnostics: Clock master / clock slave combination not permissible" 1551 "1551 Encoder track failed" 1552 "1552 Encoder adjustment abort" 1553 "1553 Encoder adjustment timeout" 1554 "1554 ID32776 Sinus Encoder Period is faulty" 1555 "1555 Reference pulse" 1556 "1556 Reference Pulse - Encoder Input" 1557 "1557 Turn axis" 1558 "1558 System diagnostics: Inverter transfers faulty encoder feedback values" 1794 "1794 System diagnostics: Interpolator" 1795 "1795 System diagnostics: Interpolator" 1796 "1796 System diagnostics: Interpolator" 1797 "1797 System diagnostics: Interpolator" 1798 "1798 System diagnostics: Interpolator" 1799 "1799 System diagnostics: Interpolator" 1800 "1800 System diagnostics: Interpolator" 1801 "1801 System diagnostics: Interpolator" 1802 "1802 System diagnostics: Interpolator" 1803 "1803 System diagnostics: Interpolator" 1804 "1804 System diagnostics: Check final value (target value)" 1805 "1805 System diagnostics: Interpolator standardisation: dxifaktor with remainder ID136, ID137..." 1806 "1806 System diagnostics: Interpolator standardisation: dxifaktor = 0: increase ID136, ID137,..." 1807 "1807 System diagnostics: Permissible time between KMD commanding and BAV operation mode mana..." 1808 "1808 System diagnostics: Operation mode management acknowledges error after commanding" 1809 "1809 System diagnostics: Inadmissible commanding code in KMD-SS, check interface" 1810 "1810 System diagnostics: Inadmissible commanding function in KMD-SS, check interface" 1811 "1811 System diagnostics: Inverter can no longer be addressed" 1812 "1812 System diagnostics: Inverter can no longer be addressed" 1813 "1813 KMD user error" 1814 "1814 System diagnostics: Inadmissible commanding operation mode selected, BA may be assigned..." 1815 "1815 Controller enable missing" 1816 "1816 Not homed" 1817 "1817 System diagnostics: Synchronous running source in synchronous running inadmissible" 1818 "1818 System diagnostics" 1819 "1819 System diagnostics: Inverter address calculation impossible, operation mode incomplete" 1820 "1820 System diagnostics: Ramp down error e.g. in lifting axis function, time according to ID..." 1821 "1821 System diagnostics: IPO cannot perform direction change" 1822 "1822 System diagnostics: IPO cannot be activated" 1823 "1823 System diagnostics: IPO cannot be activated" 1824 "1824 System diagnostics: Inadmissible KMD code in KMD-SS, inadmissible timing check interface" 1825 "1825 System diagnostics: SINCOS encoder, encoder does not report within 2 sec. through RS485-SS" 1826 "1826 System diagnostics: SINCOS encoder, checksum of the encoder acknowledgement does not ag..." 1827 "1827 System diagnostics: Invalid encoder type, the SINCOS encoder type is not permitted in t..." 1828 "1828 System diagnostics: This message can occur only in connection with an abort of drive fu..." 1829 "1829 System diagnostics: 'ID55 Closed loop polarity' and 'ID43 Velocity polarity' may be onl..." 1830 "1830 System diagnostics: “Flying saw” drive function, waiting distance (ID278) is greater th..." 1831 "1831 System diagnostics: SINCOS encoder, encoder reports error (error bit set)" 1832 "1832 System diagnostics: “Absolute positioning” drive function" 1833 "1833 System diagnostics: “Lifting axis” drive function, |nactual| ≥ |1.2 x nlimit|" 1834 "1834 System diagnostics: SINCOS encoders: The difference of the double sampling of the absol..." 1835 "1835 System diagnostics: Special lift function" 1836 "1836 System diagnostics: Special Lift function" 1837 "1837 System diagnostics: Special Lift function" 1838 "1838 System diagnostics: Special Lift function" 1839 "1839 System diagnostics: Special Lift function" 1840 "1840 System diagnostics: Special Lift function" 1841 "1841 System diagnostics" 1842 "1842 System diagnostics: Special lift function" 1843 "1843 System diagnostics" 2049 "2049 System diagnostics" 2050 "2050 System diagnostics: ID address or ID property is not known" 2051 "2051 System diagnostics: Waiting time after order to logical subscriber is exceeded" 2052 "2052 System diagnostics: The ID to be edited is not contained in the database of the system" 2053 "2053 System diagnostics: Error acknowledgement in commanding the database" 2054 "2054 System diagnostics: Error acknowledgement in commanding the monitor" 2055 "2055 System diagnostics: Error acknowledgement in commanding the serial EEPROM" 2056 "2056 System diagnostics: Error acknowledgement in commanding the operation mode management" 2057 "2057 System diagnostics: Error acknowledgement in commanding the drive commanding KMD" 2058 "2058 System diagnostics: Error in LT → KMD commanding inverter, LT → KMD - logical subscribe..." 2059 "2059 System diagnostics: Error in LT→ KMD commanding AW2" 2060 "2060 System diagnostics: Error in LT → KMD commanding AW3" 2061 "2061 System diagnostics: Error in LT → KMD commanding AW4" 2062 "2062 System diagnostics: Error in LT → KMD commanding AW5" 2063 "2063 System diagnostics: Error in LT → KMD commanding AW6" 2064 "2064 System diagnostics: Error in LT → MD commanding AW7" 2065 "2065 System diagnostics: Error in LT → KMD commanding AW8" 2066 "2066 System diagnostics: Error acknowledgement in commanding a drive control" 2067 "2067 System diagnostics: Error acknowledgement in commanding the diagnostics" 2068 "2068 System diagnostics: Error acknowledgement in commanding the display function" 2069 "2069 System diagnostics: Error acknowledgement in commanding the lift function" 2070 "2070 System diagnostics: LT-SBUS, inverter not present" 2071 "2071 System diagnostics: Failure in the s-bus hardware; re-boot system or check hardware" 2072 "2072 System diagnostics: S-bus software received faulty information from connected device, c..." 2073 "2073 System diagnostics" 2074 "2074 System diagnostics: Disturbance of scope function" 2305 "2305 Phase U Short Circuit" 2306 "2306 Phase V Short Circuit" 2307 "2307 Phase W Short Circuit" 2308 "2308 Supply +12 V" 2309 "2309 Supply" 2310 "2310 Encoder communication" 2311 "2311 Encoder signal" 2312 "2312 Output Terminal Ground Fault" 2313 "2313 Synchronous running error" 2314 "2314 Master Synchronous Telegram AW" 2315 "2315 AW controller clock error" 2316 "2316 Motor direction of rotation" 2317 "2317 External encoder direction of rotation" 2318 "2318 Control deviation" 2319 "2319 n > nmax" 2320 "2320 EF inactive" 2321 "2321 System diagnostics: IGBT monitoring in PWM device detects overcurrent" 2322 "2322 System diagnostics: Inverter RAM memory error" 2323 "2323 System diagnostics: VECON watchdog" 2324 "2324 System diagnostics: Hardware significance in the AW SEEP invalid (M8030, 2 or 3 current..." 2325 "2325 System diagnostics: Error (timeout 5s) current controller adjustment" 2326 "2326 System diagnostics" 2327 "2327 Plausibility of the External Encoder" 2328 "2328 System diagnostics: Missing option card e.g. in the KU. For instance, if an AMK-A encod..." 2329 "2329 System diagnostics: Commutation error in synchronous machine with AMK-T encoder (SINCOS..." 2330 "2330 System diagnostics" 2331 "2331 System diagnostics: Ramp down error" 2332 "2332 System diagnostics" 2333 "2333 Position growth too large" 2334 "2334 System diagnostics: Output terminal overcurrent" 2335 "2335 Error reference pulse" 2336 "2336 System diagnostics: Current setpoint at the analog input of the slave AW was too large...." 2337 "2337 No clock enable acknowledgement" 2338 "2338 Magnetizing timeout" 2339 "2339 Ramp down error" 2340 "2340 Communication on AW" 2342 "2342 System diagnostics" 2343 "2343 System diagnostics" 2344 "2344 Monitoring actual position" 2345 "2345 Inverter overload error" 2346 "2346 Converter temperature error" 2347 "2347 Motor temperature error" 2348 "2348 System diagnostics" 2349 "2349 Inverter overload warning" 2350 "2350 Device temperature warning" 2351 "2351 Motor temperature warning" 2352 "2352 Motor overload warning" 2353 "2353 Motor overload error" 2354 "2354 Handshake brake" 2356 "2356 Setpoint stop active" 2357 "2357 Device overload warning" 2358 "2358 Device overload error" 2359 "2359 Motor overload warning" 2360 "2360 Motor overload error" 2361 "2361 EF Logic" 2362 "2362 Error Commutation Motor" 2365 "2365 Error angle observer" 2366 "2366 Limit switch" 2367 "2367 Error Non Dual Use" 2560 "2560 System diagnostics: EtherCAT" 2561 "2561 System diagnostics: SERCOS" 2562 "2562 System diagnostics: MDT reception error in the Comm.phase 3 or 4 Device Description Cla..." 2563 "2563 System diagnostics: SERCOS Device Description Invalid communication phase Class Error D..." 2564 "2564 System diagnostics: SERCOS" 2565 "2565 System diagnostics: Phase switchback (not on phase 0)" 2566 "2566 System diagnostics: Phase switchover without ready message" 2569 "2569 System diagnostics: Memory error (allocating)" 2570 "2570 System diagnostics: Memory error (deallocating)" 2571 "2571 System diagnostics: Timeout during communication phases switch-over (AS-PL)" 2572 "2572 System diagnostics: SERCOS" 2573 "2573 System diagnostics: SERCOS" 2574 "2574 System diagnostics: SERCOS" 2575 "2575 System diagnostics: In Kx-SC2 modules: ext. 48 V power supply is not available or has b..." 2576 "2576 System diagnostics" 2577 "2577 System diagnostics: Allocation of the real time control or real time status bit" 2578 "2578 System diagnostics: Test function active message (continuous light, zero bit stream)" 2579 "2579 System diagnostics: Error on initialization of the SERCOS option card" 2581 "2581 System diagnostics: SERCOS master driver initialization" 2582 "2582 System diagnostics: SERCOS master driver initialization" 2583 "2583 System diagnostics: SERCOS master configuration 'ID34036 CCB File'" 2584 "2584 System diagnostics: SERCOS master phase switchover" 2585 "2585 System diagnostics: SERCOS master time slot calculation" 2586 "2586 System diagnostics: SERCOS master service channel" 2587 "2587 System diagnostics: SERCOS master incorrect data in the service channel" 2588 "2588 System diagnostics: SERCOS master error in command execution" 2589 "2589 System diagnostics: SERCOS master has detected ring interruption" 2590 "2590 System diagnostics: SERCOS master has detected AT failure" 2591 "2591 System diagnostics: SERCOS master software error" 2592 "2592 System diagnostics: SERCOS master has detected MST failure" 2593 "2593 System diagnostics: SERCOS master real time error" 2594 "2594 System diagnostics: SERCOS master software error" 2595 "2595 System diagnostics: SERCOS" 2596 "2596 System diagnostics: SERCOS master has received the “error” acknowledgment to a command" 2597 "2597 System diagnostics: SERCOS master has received an error message from a remote node" 2598 "2598 System diagnostics: SERCOS has indicated a bad signal quality on the OWG receiver (exce..." 2599 "2599 System diagnostics: Error while activating the advanced operating mode" 2600 "2600 System diagnostics: Error memory space" 2601 "2601 System diagnostics: Adapter cannot be initialized" 2602 "2602 System diagnostics: Cable is interrupted (reaction according to 'ID 34027 BUS failure c..." 2603 "2603 System diagnostics: Data exchange mode is exited (e.g. after watchdog error; reaction a..." 2604 "2604 System diagnostics: Inadmissible field bus handshake code (e.g. SERVERERROR, SERVERWARN..." 2605 "2605 System diagnostics: PROFIBUS Initialization/ Error state" 2606 "2606 System diagnostics: PROFIBUS MSAC-C1 error (Master-Slave Acyclic Communication-Class1)" 2607 "2607 System diagnostics: PROFIBUS MSAC-C2 error (Master-Slave Acyclic Communication-Class2)" 2608 "2608 System diagnostics: PROFIBUS initialisation error" 2609 "2609 System diagnostics: PROFIBUS Warning – wrong parameter initialization" 2610 "2610 System diagnostics: PROFIBUS error bus configuration" 2611 "2611 System diagnostics: PROFIBUS error bus configuration" 2612 "2612 System diagnostics: PROFIBUS error bus configuration" 2613 "2613 System diagnostics: PROFIBUS error bus configuration" 2614 "2614 System diagnostics: PROFIBUS error bus configuration" 2615 "2615 System diagnostics: PROFIBUS error bus configuration" 2620 "2620 System diagnostics: Subscriber not connected with network" 2621 "2621 System diagnostics: Network error" 2622 "2622 System diagnostics: Transfer error/transmission error" 2623 "2623 System diagnostics: Adapter is constantly reconfigured" 2624 "2624 System diagnostics: ID34023=0, BUS subscriber address must be unequal to 0" 2625 "2625 System diagnostics: ARCNET telegram too long" 2626 "2626 System diagnostics: Node ID is already present" 2628 "2628 System diagnostics: Init. state error" 2640 "2640 LON failure" 2641 "2641 LON timeout IN" 2642 "2642 LON timeout OUT" 2643 "2643 LON timeout application" 2644 "2644 System diagnostics: Device reports within 2 s in the ramp up" 2645 "2645 System diagnostics: DPRAM writing error" 2660 "2660 System diagnostics: The required RAM memory for the system data is not present" 2661 "2661 System diagnostics: Unknown bus mode entry in 'ID34025 BUS mode'" 2663 "2663 System diagnostics: Interbus is inactive" 2664 "2664 System diagnostics: Interbus reset" 2665 "2665 System diagnostics: At least 20 invalid data cycles detected" 2680 "2680 System diagnostics: CAN AFP error during initialization" 2681 "2681 System diagnostics: Object Dictionary error" 2682 "2682 System diagnostics: Too much Receive PDOs and SDOs configured" 2683 "2683 System diagnostics: Software error (Reason could be false configuration data)" 2684 "2684 System diagnostics: Communication error" 2685 "2685 System diagnostics: Communication error" 2686 "2686 System diagnostics: AFP error" 2687 "2687 System diagnostics: Invalid Node address" 2688 "2688 System diagnostics: 'ID34025 Bus mode':AFP bit not valid" 2689 "2689 System diagnostics: Errors on configuring" 2690 "2690 System diagnostics: Error in Slave configuration (Data size in CCF element too big)" 2691 "2691 System diagnostics" 2692 "2692 System diagnostics: Software warning" 2693 "2693 System diagnostics: Slave Node State error" 2694 "2694 System diagnostics: Slave Node Guarding error" 2695 "2695 System diagnostics: Emergency received" 2696 "2696 System diagnostics: DSDO Router error" 2697 "2697 System diagnostics: Mandatory slave node missing" 2698 "2698 System diagnostics: SDO error during network configuration" 2699 "2699 System diagnostics: System error" 2721 "2721 System diagnostics: Slave defective or no longer on the bus" 2722 "2722 System diagnostics: Cable breakage" 2723 "2723 System Diagnostics" 2724 "2724 System diagnostics: Error during the initialisation for the EtherCAT option" 2725 "2725 System diagnostics" 2726 "2726 System diagnostics: Error in the EtherCAT master booting process" 2727 "2727 System diagnostics: Error EtherCAT configuration" 2728 "2728 System diagnostics: Error EtherCAT protocol during ID access" 2729 "2729 System diagnostics: Error EtherCAT service channel / mailbox" 2730 "2730 System diagnostics: Error EtherCAT datagram sending procedure, communication error" 2731 "2731 System diagnostics: Error EtherCAT sequence slave configuration" 2732 "2732 System diagnostics" 2741 "2741 Modbus configuration" 2742 "2742 MODBUS communication" 2743 "2743 MODBUS protocol" 2744 "2744 MODBUS command" 2760 "2760 System diagnostics: Missing DC bus voltage at state 'SWITCHED ON' or when switching to..." 2761 "2761 System diagnostics: Error when changing the operating mode" 2762 "2762 System diagnostics: Error in function 'Touch Probe'" 2763 "2763 System diagnostics: Error in scaling configuration" 2764 "2764 System diagnostics: Error in Brake function" 2816 "2816 PS option" 3072 "3072 Error option SERCOS" 3328 "3328 NC option error" 3584 "3584 Special SW msg: Fault overload protection connectbox (n)" 3585 "3585 FSE: CAN/config error during init (voltage limit / torque reduction limits)" 3586 "3586 FSE CAN: Error during initialization (config mode, index, signal, length, baud)" 3587 "3587 FSE CAN: Error during operation (setpoint telegram failure, checksum, counter)" 3588 "3588 Special SW msg: Frequency too low" 3589 "3589 Special SW msg: Frequency too high" 3590 "3590 Special SW msg: Voltage too low" 3591 "3591 Special SW msg: Voltage too high" 3592 "3592 Special SW msg: Fault voltage (switch on)" 3593 "3593 Special SW msg: Fault frequency (switch on)" 3594 "3594 Special SW msg: Warning string monitoring connectbox (n)..." 3595 "3595 Special SW msg: Fault init bus" 3596 "3596 Special SW msg: Fault check DC" 3597 "3597 Special SW msg: Fault check AC / DC" 3598 "3598 Special SW msg: See special descriptions corresponding to..." 3599 "3599 Special SW msg: See special descriptions corresponding to..." 3600 "3600 Special SW msg: See special descriptions corresponding to..." 3601 "3601 Special SW msg: See special descriptions corresponding to..." 3602 "3602 Special SW msg: See special descriptions corresponding to..." 3603 "3603 System diagnostics: AFP-PLC error" 3605 "3605 Safety - Invalid parameterisation" 3606 "3606 Safety - Error during operation" 3607 "3607 Safety - Internal system error" 3609 "3609 Safety - Faulty parameter transfer" 3610 "3610 Safety - Warning during operation" 3840 "3840 File access" 3841 "3841 System diagnostics: Internal communication: Error message returned from end device" 3842 "3842 System diagnostics: Internal communication: No heap memory could be addressed." 3843 "3843 System diagnostics: Internal communication: Source module does not exist (not logged in?)" 3844 "3844 System diagnostics: Internal communication: The addressed target does not exist" 3845 "3845 System diagnostics" 3846 "3846 System diagnostics: Internal communication: A module has logged on that already exists..." 3847 "3847 System diagnostics: Internal communication: The element code is unknown" 3848 "3848 System diagnostics: Internal communication: Too many modules have logged in or" 3849 "3849 System diagnostics: Internal communication: Protocol or command order is incorrect" 3850 "3850 System diagnostics: A bus connected to the internal communication is not in standby mod..." 3851 "3851 System diagnostics: An internal communication path has been occupied by a module by wri..." 3852 "3852 System diagnostics: An internal communication path specified by a module is not valid o..." 3853 "3853 System diagnostics: Router error in module setting" 3854 "3854 System diagnostics: Router memory overflow of the inernal buffer" 3855 "3855 System diagnostics: Router memory overflow at access to the internal database" 3860 "3860 ADB-File access" 3861 "3861 System start / update" 3862 "3862 System diagnostics: System exception, CPU error" 3863 "3863 System diagnostics: Router memory overflow internal buffer" 3864 "3864 Bus configuration" 3865 "3865 Software version option" 3867 "3867 System diagnostics: Error in updating device data record" 3868 "3868 System diagnostics: Error during initialisation of system" 3869 "3869 I/O Optional Card" 3871 "3871 System diagnostics: Communication" ;
